VERSION "dbc-export 1 2025.20.8"

NS_ :

BS_:

BU_: APP BMS CC CMP CMPD CP DAS DI DIF DIR EPBL EPBR EVSE FC GTW HCML HCMR HVP ICR PCS PM PMF PMR PTC SCCM SDCR TAS UMC VC VCFRONT VCLEFT VCRIGHT VCSEC

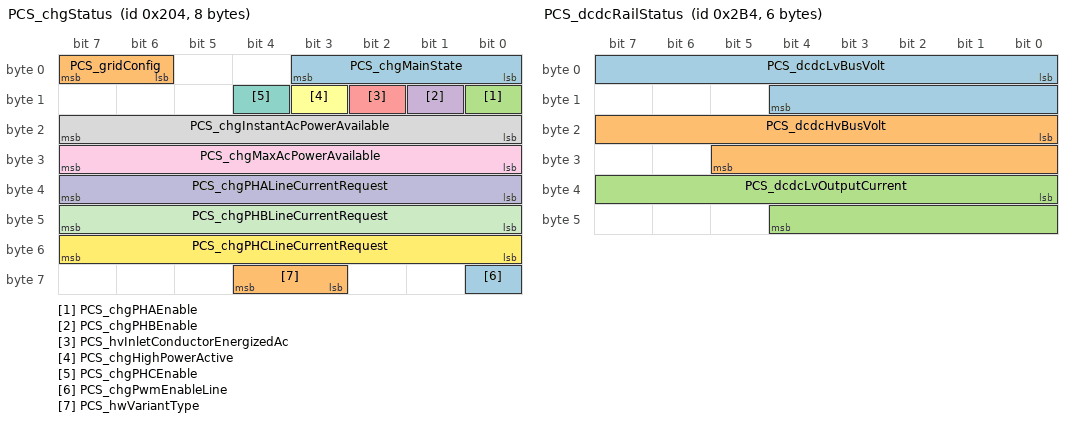
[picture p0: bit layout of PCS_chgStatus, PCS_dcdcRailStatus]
BO_ 516 PCS_chgStatus: 8 PCS
 SG_ PCS_chgMainState : 0|4@1+ (1,0) [0|15] "" Vector__XXX
 SG_ PCS_gridConfig : 6|2@1+ (1,0) [1|3] "" Vector__XXX
 SG_ PCS_chgPHAEnable : 8|1@1+ (1,0) [0|1] "" Vector__XXX
 SG_ PCS_chgPHBEnable : 9|1@1+ (1,0) [0|1] "" Vector__XXX
 SG_ PCS_hvInletConductorEnergizedAc : 10|1@1+ (1,0) [0|1] "" Vector__XXX
 SG_ PCS_chgHighPowerActive : 11|1@1+ (1,0) [0|1] "" Vector__XXX
 SG_ PCS_chgPHCEnable : 12|1@1+ (1,0) [0|1] "" Vector__XXX
 SG_ PCS_chgInstantAcPowerAvailable : 16|8@1+ (0.1,0) [0|20] "kW" Vector__XXX
 SG_ PCS_chgMaxAcPowerAvailable : 24|8@1+ (0.1,0) [0|20] "kW" Vector__XXX
 SG_ PCS_chgPHALineCurrentRequest : 32|8@1+ (0.1,0) [0|20] "A" Vector__XXX
 SG_ PCS_chgPHBLineCurrentRequest : 40|8@1+ (0.1,0) [0|20] "A" Vector__XXX
 SG_ PCS_chgPHCLineCurrentRequest : 48|8@1+ (0.1,0) [0|20] "A" Vector__XXX
 SG_ PCS_chgPwmEnableLine : 56|1@1+ (1,0) [0|1] "" Vector__XXX
 SG_ PCS_hwVariantType : 59|2@1+ (1,0) [0|2] "" Vector__XXX

BO_ 692 PCS_dcdcRailStatus: 6 PCS
 SG_ PCS_dcdcLvBusVolt : 0|13@1+ (0.01,0) [0|80] "V" Vector__XXX
 SG_ PCS_dcdcHvBusVolt : 16|14@1+ (0.1,0) [0|1600] "V" Vector__XXX
 SG_ PCS_dcdcLvOutputCurrent : 32|13@1- (0.1,0) [-400|400] "A" Vector__XXX

BO_ 548 PCS_dcdcStatus: 8 PCS
 SG_ PCS_dcdcPrechargeStatus : 0|2@1+ (1,0) [0|3] "" Vector__XXX
 SG_ PCS_dcdcLvSupportStatus : 2|2@1+ (1,0) [0|3] "" Vector__XXX
 SG_ PCS_dcdcHvBusDischargeStatus : 4|2@1+ (1,0) [0|3] "" Vector__XXX
 SG_ PCS_coldSleepAllowed : 8|1@1+ (1,0) [0|1] "" Vector__XXX
 SG_ PCS_dcdcPchgHVBusLowRDetected : 9|1@1+ (1,0) [0|1] "" Vector__XXX
 SG_ PCS_dcdcSubState : 10|5@1+ (1,0) [0|31] "" Vector__XXX
 SG_ PCS_dcdcFaulted : 15|1@1+ (1,0) [0|1] "" Vector__XXX
 SG_ PCS_okToBePowerCycled : 27|1@1+ (1,0) [0|1] "" Vector__XXX
 SG_ PCS_dcdcOutputIsLimited : 28|1@1+ (1,0) [0|1] "" Vector__XXX
 SG_ PCS_dcdcMaxOutputCurrentAllowed : 29|12@1+ (0.1,0) [0|400] "A" Vector__XXX
 SG_ PCS_dcdcPrechargeRtyCnt : 41|3@1+ (1,0) [0|7] "" Vector__XXX
 SG_ PCS_dcdcLvSupportRtyCnt : 44|4@1+ (1,0) [0|15] "" Vector__XXX
 SG_ PCS_dcdcDischargeRtyCnt : 48|4@1+ (1,0) [0|15] "" Vector__XXX
 SG_ PCS_dcdcPwmEnableLine : 52|1@1+ (1,0) [0|1] "" Vector__XXX
 SG_ PCS_dcdcSupportingFixedLvTarget : 53|1@1+ (1,0) [0|1] "" Vector__XXX
 SG_ PCS_ecuLogUploadRequest : 54|2@1+ (1,0) [0|3] "" Vector__XXX
 SG_ PCS_dcdcPrechargeRestartCnt : 56|3@1+ (1,0) [0|7] "" Vector__XXX
 SG_ PCS_dcdcInitialPrechargeSubState : 59|5@1+ (1,0) [0|31] "" Vector__XXX

BO_ 964 PCS_info: 8 PCS
 SG_ PCS_infoIndex M : 0|8@1+ (1,0) [0|255] "" Vector__XXX
 SG_ PCS_buildType m10 : 8|8@1+ (1,0) [0|255] "" Vector__XXX
 SG_ PCS_buildConfigId m10 : 16|16@1+ (1,0) [0|65535] "" Vector__XXX
 SG_ PCS_hardwareId m10 : 32|16@1+ (1,0) [0|65535] "" Vector__XXX
 SG_ PCS_componentId m10 : 48|16@1+ (1,0) [0|65535] "" Vector__XXX
 SG_ PCS_pcbaId m11 : 16|8@1+ (1,0) [0|255] "" Vector__XXX
 SG_ PCS_assemblyId m11 : 24|8@1+ (1,0) [0|255] "" Vector__XXX
 SG_ PCS_usageId m11 : 32|16@1+ (1,0) [0|65535] "" Vector__XXX
 SG_ PCS_subUsageId m11 : 48|16@1+ (1,0) [0|65535] "" Vector__XXX
 SG_ PCS_platformType m13 : 8|8@1+ (1,0) [0|255] "" Vector__XXX
 SG_ PCS_appCrc m13 : 32|32@1+ (1,0) [0|4294967295] "" Vector__XXX
 SG_ PCS_cpu2AppCrc m16 : 32|32@1+ (1,0) [0|4294967295] "" Vector__XXX
 SG_ PCS_appGitHash m17 : 8|56@1+ (1,0) [0|7.20575940379e+16] "" Vector__XXX
 SG_ PCS_bootGitHash m18 : 8|56@1+ (1,0) [0|7.20575940379e+16] "" Vector__XXX
 SG_ PCS_bootUdsProtoVersion m20 : 8|8@1+ (1,0) [0|255] "" Vector__XXX
 SG_ PCS_bootCrc m20 : 32|32@1+ (1,0) [0|4294967295] "" Vector__XXX

BO_ 708 PCS_logging: 8 PCS
 SG_ PCS_logMessageSelect M : 0|5@1+ (1,0) [0|31] "" Vector__XXX
 SG_ PCS_chgPhAInputIrms m0 : 5|9@1+ (0.1,0) [0|51.1] "A" Vector__XXX
 SG_ PCS_chgPhAIntBusV m0 : 14|9@1+ (1,0) [0|511] "V" Vector__XXX
 SG_ PCS_chgPhAIntBusVTarget m0 : 23|9@1+ (1,0) [0|511] "V" Vector__XXX
 SG_ PCS_chgPhAOutputI m0 : 32|8@1+ (0.1,0) [0|25.5] "A" Vector__XXX
 SG_ PCS_chgPhAInputCurrentLimitReaso m0 : 40|3@1+ (1,0) [0|7] "" Vector__XXX
 SG_ PCS_chgPhBInputIrms m1 : 5|9@1+ (0.1,0) [0|51.1] "A" Vector__XXX
 SG_ PCS_chgPhBIntBusV m1 : 14|9@1+ (1,0) [0|511] "V" Vector__XXX
 SG_ PCS_chgPhBIntBusVTarget m1 : 23|9@1+ (1,0) [0|511] "V" Vector__XXX
 SG_ PCS_chgPhBOutputI m1 : 32|8@1+ (0.1,0) [0|25.5] "A" Vector__XXX
 SG_ PCS_chgPhBInputCurrentLimitReaso m1 : 40|3@1+ (1,0) [0|7] "" Vector__XXX
 SG_ PCS_chgPhCInputIrms m2 : 5|9@1+ (0.1,0) [0|51.1] "A" Vector__XXX
 SG_ PCS_chgPhCIntBusV m2 : 14|9@1+ (1,0) [0|511] "V" Vector__XXX
 SG_ PCS_chgPhCIntBusVTarget m2 : 23|9@1+ (1,0) [0|511] "V" Vector__XXX
 SG_ PCS_chgPhCOutputI m2 : 32|8@1+ (0.1,0) [0|25.5] "A" Vector__XXX
 SG_ PCS_chgPhCInputCurrentLimitReaso m2 : 40|3@1+ (1,0) [0|7] "" Vector__XXX
 SG_ PCS_chgInputL1NVrms m3 : 5|12@1+ (0.2,0) [0|819] "V" Vector__XXX
 SG_ PCS_chgInputL2NVrms m3 : 17|12@1+ (0.2,0) [0|819] "V" Vector__XXX
 SG_ PCS_chgInputL3NVrms m3 : 29|12@1+ (0.2,0) [0|819] "V" Vector__XXX
 SG_ PCS_chgInputL1L2Vrms m3 : 41|12@1+ (0.2,0) [0|819] "V" Vector__XXX
 SG_ PCS_chgInputNGVrms m3 : 53|9@1+ (1,0) [0|511] "V" Vector__XXX
 SG_ PCS_chgInputFrequencyL1N m4 : 5|12@1+ (0.01,40) [40|80.95] "Hz" Vector__XXX
 SG_ PCS_chgInputFrequencyL2N m4 : 17|12@1+ (0.01,40) [40|80.95] "Hz" Vector__XXX
 SG_ PCS_chgInputFrequencyL3N m4 : 29|12@1+ (0.01,40) [40|80.95] "Hz" Vector__XXX
 SG_ PCS_chgInternalPhaseConfig m4 : 41|4@1+ (1,0) [1|15] "" Vector__XXX
 SG_ PCS_chgPhasesPriority m4 : 45|6@1+ (1,0) [0|63] "" Vector__XXX
 SG_ PCS_chgOutputV m4 : 51|12@1+ (0.146484375,0) [0|599.853515625] "V" Vector__XXX
 SG_ PCS_chgPhAState m5 : 5|4@1+ (1,0) [0|15] "" Vector__XXX
 SG_ PCS_chgPhBState m5 : 9|4@1+ (1,0) [0|15] "" Vector__XXX
 SG_ PCS_chgPhCState m5 : 13|4@1+ (1,0) [0|15] "" Vector__XXX
 SG_ PCS_chgPhALastShutdownReason m5 : 17|5@1+ (1,0) [0|31] "" Vector__XXX
 SG_ PCS_chgPhBLastShutdownReason m5 : 22|5@1+ (1,0) [0|31] "" Vector__XXX
 SG_ PCS_chgPhCLastShutdownReason m5 : 27|5@1+ (1,0) [0|31] "" Vector__XXX
 SG_ PCS_chgPhARetryCount m5 : 32|3@1+ (1,0) [0|7] "" Vector__XXX
 SG_ PCS_chgPhBRetryCount m5 : 35|3@1+ (1,0) [0|7] "" Vector__XXX
 SG_ PCS_chgPhCRetryCount m5 : 38|3@1+ (1,0) [0|7] "" Vector__XXX
 SG_ PCS_chgRetryCount m5 : 41|3@1+ (1,0) [0|7] "" Vector__XXX
 SG_ PCS_chgPhManCurrentToDist m5 : 44|10@1+ (0.1,0) [0|100] "A" Vector__XXX
 SG_ PCS_chgL1NPllLocked m5 : 54|1@1+ (1,0) [0|1] "" Vector__XXX
 SG_ PCS_chgL2NPllLocked m5 : 55|1@1+ (1,0) [0|1] "" Vector__XXX
 SG_ PCS_chgL3NPllLocked m5 : 56|1@1+ (1,0) [0|1] "" Vector__XXX
 SG_ PCS_chgL1L2PllLocked m5 : 57|1@1+ (1,0) [0|1] "" Vector__XXX
 SG_ PCS_chgNgPllLocked m5 : 58|1@1+ (1,0) [0|1] "" Vector__XXX
 SG_ PCS_chgPhManOptimalPhsToUse m5 : 59|2@1+ (1,0) [0|3] "" Vector__XXX
 SG_ PCS_chg5VL1Enable m5 : 61|1@1+ (1,0) [0|1] "" Vector__XXX
 SG_ PCS_dcdcMaxLvOutputCurrent m6 : 8|12@1+ (0.1,0) [0|400] "A" Vector__XXX
 SG_ PCS_dcdcCurrentLimit m6 : 20|12@1+ (0.1,0) [0|400] "A" Vector__XXX
 SG_ PCS_dcdcLvOutputCurrentTempLimit m6 : 32|12@1+ (0.1,0) [0|400] "A" Vector__XXX
 SG_ PCS_dcdcLvOutputCurrentFiltered m6 : 44|12@1+ (0.1,0) [0|400] "A" Vector__XXX
 SG_ PCS_dcdcUnifiedCommand m7 : 5|10@1+ (0.001,0) [0|1] "1" Vector__XXX
 SG_ PCS_dcdcCLAControllerOutput m7 : 16|10@1+ (0.001,0) [0|1] "1" Vector__XXX
 SG_ PCS_dcdcTankVoltage m7 : 26|11@1- (1,0) [-1024|1023] "V" Vector__XXX
 SG_ PCS_dcdcTankVoltageTarget m7 : 37|10@1+ (1,0) [0|1023] "V" Vector__XXX
 SG_ PCS_dcdcClaCurrentFreq m7 : 48|12@1+ (0.09765625,0) [0|399.9] "kHz" Vector__XXX
 SG_ PCS_dcdcTCommMeasured m8 : 5|16@1- (0.001953125,0) [-64|63.998] "us" Vector__XXX
 SG_ PCS_dcdcShortTimeUs m8 : 21|16@1+ (0.00048828125,0) [0|31.9995] "us" Vector__XXX
 SG_ PCS_dcdcHalfPeriodUs m8 : 37|16@1+ (0.00048828125,0) [0|31.9995] "us" Vector__XXX
 SG_ PCS_dcdcLvBusVoltTargetWithOffse m8 : 53|11@1+ (0.01,0) [0|20] "V" Vector__XXX
 SG_ PCS_cpu2BootState m9 : 5|2@1+ (1,0) [0|3] "" Vector__XXX
 SG_ PCS_acChargeSelfTestState m9 : 7|1@1+ (1,0) [0|1] "" Vector__XXX
 SG_ PCS_1V5Min10s m9 : 8|11@1+ (0.001,0) [0|2.047] "V" Vector__XXX
 SG_ PCS_1V5Max10s m9 : 19|11@1+ (0.001,0) [0|2.047] "V" Vector__XXX
 SG_ PCS_1V2Min10s m9 : 32|11@1+ (0.001,0) [0|2.047] "V" Vector__XXX
 SG_ PCS_1V2Max10s m9 : 43|11@1+ (0.001,0) [0|2.047] "V" Vector__XXX
 SG_ PCS_5VNMax10s m9 : 54|10@1+ (0.01,0) [0|10.23] "V" Vector__XXX
 SG_ PCS_chgPhAIntBusVMin10s m10 : 5|9@1+ (1,0) [0|511] "V" Vector__XXX
 SG_ PCS_chgPhAIntBusVMax10s m10 : 14|9@1+ (1,0) [0|511] "V" Vector__XXX
 SG_ PCS_chgPhAPchgVoltDeltaMax10s m10 : 23|8@1+ (0.5,0) [0|127.5] "V" Vector__XXX
 SG_ PCS_chgPhALifetimekWh m10 : 31|24@1+ (0.01,0) [0|167772.15] "kWh" Vector__XXX
 SG_ PCS_chgPhATransientRetryCount m10 : 55|9@1+ (0.1,0) [0|51.1] "-" Vector__XXX
 SG_ PCS_chgPhBIntBusVMin10s m11 : 5|9@1+ (1,0) [0|511] "V" Vector__XXX
 SG_ PCS_chgPhBIntBusVMax10s m11 : 14|9@1+ (1,0) [0|511] "V" Vector__XXX
 SG_ PCS_chgPhBPchgVoltDeltaMax10s m11 : 23|8@1+ (0.5,0) [0|127.5] "V" Vector__XXX
 SG_ PCS_chgPhBLifetimekWh m11 : 31|24@1+ (0.01,0) [0|167772.15] "kWh" Vector__XXX
 SG_ PCS_chgPhBTransientRetryCount m11 : 55|9@1+ (0.1,0) [0|51.1] "-" Vector__XXX
 SG_ PCS_chgPhCIntBusVMin10s m12 : 5|9@1+ (1,0) [0|511] "V" Vector__XXX
 SG_ PCS_chgPhCIntBusVMax10s m12 : 14|9@1+ (1,0) [0|511] "V" Vector__XXX
 SG_ PCS_chgPhCPchgVoltDeltaMax10s m12 : 23|8@1+ (0.5,0) [0|127.5] "V" Vector__XXX
 SG_ PCS_chgPhCLifetimekWh m12 : 31|24@1+ (0.01,0) [0|167772.15] "kWh" Vector__XXX
 SG_ PCS_chgPhCTransientRetryCount m12 : 55|9@1+ (0.1,0) [0|51.1] "-" Vector__XXX
 SG_ PCS_chgPhANoFlowBucket m20 : 5|9@1+ (0.01,0) [0|5.11] "-" Vector__XXX
 SG_ PCS_chgPhBNoFlowBucket m20 : 14|9@1+ (0.01,0) [0|5.11] "-" Vector__XXX
 SG_ PCS_chgPhCNoFlowBucket m20 : 23|9@1+ (0.01,0) [0|5.11] "-" Vector__XXX
 SG_ PCS_chgCurrentSensorOutOfBandUs m20 : 32|10@1+ (0.01,0) [0|10.23] "us" Vector__XXX
 SG_ PCS_chgAcpwHeartbeatState m20 : 42|3@1+ (1,0) [0|7] "" Vector__XXX
 SG_ PCS_chgKwhLostByFreqDroop m20 : 48|8@1+ (0.1,0) [0|25.5] "kWh" Vector__XXX
 SG_ PCS_chgReqKwhLostByFreqDroop m20 : 56|8@1+ (0.1,0) [0|25.5] "kWh" Vector__XXX
 SG_ PCS_dcdcLvSupportLifetimekWh m22 : 8|24@1+ (0.01,0) [0|167772.15] "kWh" Vector__XXX
 SG_ PCS_chgPwmEnableLineErrorCount m22 : 32|10@1+ (1,0) [0|1023] "" Vector__XXX
 SG_ PCS_dcdcPwmEnableLineErrorCount m22 : 42|10@1+ (1,0) [0|1023] "" Vector__XXX
 SG_ PCS_numAlertsSet m22 : 56|7@1+ (1,0) [0|127] "" Vector__XXX
 SG_ PCS_dcdcPchgStartLvBusVolt m24 : 5|10@1+ (0.0390625,0) [0|39.9609375] "V" Vector__XXX
 SG_ PCS_dcdcPchgStartHvBusVolt m24 : 16|12@1+ (0.146484375,0) [0|599.853515625] "V" Vector__XXX
 SG_ PCS_processorDieIdLot m26 : 8|24@1+ (1,0) [0|16777215] "" Vector__XXX
 SG_ PCS_processorDieIdWafer m26 : 32|8@1+ (1,0) [0|255] "" Vector__XXX
 SG_ PCS_processorDieIdX m26 : 40|12@1+ (1,0) [0|4095] "" Vector__XXX
 SG_ PCS_processorDieIdY m26 : 52|12@1+ (1,0) [0|4095] "" Vector__XXX

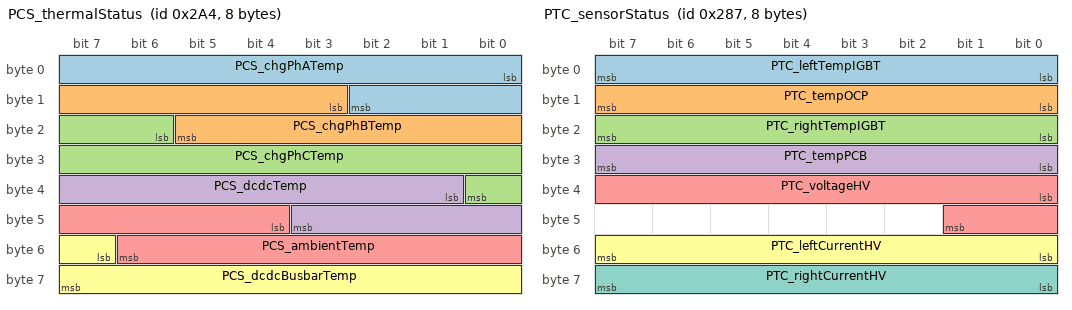
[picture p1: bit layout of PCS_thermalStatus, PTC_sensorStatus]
BO_ 676 PCS_thermalStatus: 8 PCS
 SG_ PCS_chgPhATemp : 0|11@1- (0.1,40) [-62.4|142.3] "C" Vector__XXX
 SG_ PCS_chgPhBTemp : 11|11@1- (0.1,40) [-62.4|142.3] "C" Vector__XXX
 SG_ PCS_chgPhCTemp : 22|11@1- (0.1,40) [-62.4|142.3] "C" Vector__XXX
 SG_ PCS_dcdcTemp : 33|11@1- (0.1,40) [-62.4|142.3] "C" Vector__XXX
 SG_ PCS_ambientTemp : 44|11@1- (0.1,40) [-62.4|142.3] "C" Vector__XXX
 SG_ PCS_dcdcBusbarTemp : 55|9@1+ (0.2935421,0) [0|149.706471] "C" Vector__XXX

BO_ 790 PMF_info: 8 PMF
 SG_ PMF_infoIndex M : 0|8@1+ (1,0) [0|255] "" Vector__XXX
 SG_ PMF_buildType m10 : 8|8@1+ (1,0) [0|255] "" Vector__XXX
 SG_ PMF_buildConfigurationId m10 : 16|16@1+ (1,0) [0|65535] "" Vector__XXX
 SG_ PMF_hardwareId m10 : 32|8@1+ (1,0) [0|252] "" Vector__XXX
 SG_ PMF_deviceFused m10 : 40|1@1+ (1,0) [0|1] "" Vector__XXX
 SG_ PMF_componentId m10 : 48|16@1+ (1,0) [0|65535] "" Vector__XXX
 SG_ PMF_pcbaId m11 : 16|8@1+ (1,0) [0|255] "" Vector__XXX
 SG_ PMF_assemblyId m11 : 24|8@1+ (1,0) [0|255] "" Vector__XXX
 SG_ PMF_usageId m11 : 32|16@1+ (1,0) [0|65535] "" Vector__XXX
 SG_ PMF_subUsageId m11 : 48|16@1+ (1,0) [0|65535] "" Vector__XXX
 SG_ PMF_applicationCrc m13 : 32|32@1+ (1,0) [0|4294967295] "" Vector__XXX
 SG_ PMF_appGitHash m17 : 8|56@1+ (1,0) [0|7.20575940379e+16] "" Vector__XXX
 SG_ PMF_bootGitHash m18 : 8|56@1+ (1,0) [0|7.20575940379e+16] "" Vector__XXX
 SG_ PMF_platformTyp m19 : 8|8@1+ (1,0) [0|255] "" Vector__XXX
 SG_ PMF_udsProtocolVersion m20 : 8|8@1+ (1,0) [0|255] "" Vector__XXX
 SG_ PMF_bootloaderCrc m20 : 32|32@1+ (1,0) [0|4294967295] "" Vector__XXX

BO_ 1748 PMR_info: 8 PMR
 SG_ PMR_infoIndex M : 0|8@1+ (1,0) [0|255] "" Vector__XXX
 SG_ PMR_buildType m10 : 8|8@1+ (1,0) [0|255] "" Vector__XXX
 SG_ PMR_buildConfigurationId m10 : 16|16@1+ (1,0) [0|65535] "" Vector__XXX
 SG_ PMR_hardwareId m10 : 32|8@1+ (1,0) [0|252] "" Vector__XXX
 SG_ PMR_deviceFused m10 : 40|1@1+ (1,0) [0|1] "" Vector__XXX
 SG_ PMR_componentId m10 : 48|16@1+ (1,0) [0|65535] "" Vector__XXX
 SG_ PMR_pcbaId m11 : 16|8@1+ (1,0) [0|255] "" Vector__XXX
 SG_ PMR_assemblyId m11 : 24|8@1+ (1,0) [0|255] "" Vector__XXX
 SG_ PMR_usageId m11 : 32|16@1+ (1,0) [0|65535] "" Vector__XXX
 SG_ PMR_subUsageId m11 : 48|16@1+ (1,0) [0|65535] "" Vector__XXX
 SG_ PMR_applicationCrc m13 : 32|32@1+ (1,0) [0|4294967295] "" Vector__XXX
 SG_ PMR_appGitHash m17 : 8|56@1+ (1,0) [0|7.20575940379e+16] "" Vector__XXX
 SG_ PMR_bootGitHash m18 : 8|56@1+ (1,0) [0|7.20575940379e+16] "" Vector__XXX
 SG_ PMR_platformTyp m19 : 8|8@1+ (1,0) [0|255] "" Vector__XXX
 SG_ PMR_udsProtocolVersion m20 : 8|8@1+ (1,0) [0|255] "" Vector__XXX
 SG_ PMR_bootloaderCrc m20 : 32|32@1+ (1,0) [0|4294967295] "" Vector__XXX

BO_ 1551 PM_info: 8 PM
 SG_ PM_infoIndex M : 0|8@1+ (1,0) [0|255] "" Vector__XXX
 SG_ PM_buildType m10 : 8|8@1+ (1,0) [0|255] "" Vector__XXX
 SG_ PM_buildConfigurationId m10 : 16|16@1+ (1,0) [0|65535] "" Vector__XXX
 SG_ PM_hardwareId m10 : 32|8@1+ (1,0) [0|252] "" Vector__XXX
 SG_ PM_deviceFused m10 : 40|1@1+ (1,0) [0|1] "" Vector__XXX
 SG_ PM_componentId m10 : 48|16@1+ (1,0) [0|65535] "" Vector__XXX
 SG_ PM_pcbaId m11 : 16|8@1+ (1,0) [0|255] "" Vector__XXX
 SG_ PM_assemblyId m11 : 24|8@1+ (1,0) [0|255] "" Vector__XXX
 SG_ PM_usageId m11 : 32|16@1+ (1,0) [0|65535] "" Vector__XXX
 SG_ PM_subUsageId m11 : 48|16@1+ (1,0) [0|65535] "" Vector__XXX
 SG_ PM_applicationCrc m13 : 32|32@1+ (1,0) [0|4294967295] "" Vector__XXX
 SG_ PM_bootGitHash m18 : 8|56@1+ (1,0) [0|7.20575940379e+16] "" Vector__XXX

BO_ 837 PTC_info: 8 PTC
 SG_ PTC_infoIndex M : 0|8@1+ (1,0) [0|255] "" Vector__XXX
 SG_ PTC_infoBuildType m10 : 8|3@1+ (1,0) [0|7] "" Vector__XXX
 SG_ PTC_infoBuildConfigId m10 : 16|16@1+ (1,0) [0|65535] "" Vector__XXX
 SG_ PTC_infoHardwareId m10 : 32|16@1+ (1,0) [0|65535] "" Vector__XXX
 SG_ PTC_infoComponentId m10 : 48|16@1+ (1,0) [0|65535] "" Vector__XXX
 SG_ PTC_infoPcbaId m11 : 16|8@1+ (1,0) [0|255] "" Vector__XXX
 SG_ PTC_infoAssemblyId m11 : 24|8@1+ (1,0) [0|254] "" Vector__XXX
 SG_ PTC_infoUsageId m11 : 32|16@1+ (1,0) [0|65535] "" Vector__XXX
 SG_ PTC_infoSubUsageId m11 : 48|16@1+ (1,0) [0|65535] "" Vector__XXX
 SG_ PTC_infoPlatformType m13 : 8|8@1+ (1,0) [0|255] "" Vector__XXX
 SG_ PTC_infoAppCrc m13 : 32|32@1+ (1,0) [0|4294967295] "" Vector__XXX
 SG_ PTC_infoBootUdsProtoVersion m20 : 8|8@1+ (1,0) [0|255] "" Vector__XXX
 SG_ PTC_infoBootCrc m20 : 32|32@1+ (1,0) [0|4294967295] "" Vector__XXX

BO_ 647 PTC_sensorStatus: 8 PTC
 SG_ PTC_leftTempIGBT : 0|8@1+ (1,-40) [-40|200] "degC" Vector__XXX
 SG_ PTC_tempOCP : 8|8@1+ (1,-40) [-40|200] "degC" Vector__XXX
 SG_ PTC_rightTempIGBT : 16|8@1+ (1,-40) [-40|200] "degC" Vector__XXX
 SG_ PTC_tempPCB : 24|8@1+ (1,-40) [-40|200] "degC" Vector__XXX
 SG_ PTC_voltageHV : 32|10@1+ (0.5,0) [0|511.5] "V" Vector__XXX
 SG_ PTC_leftCurrentHV : 48|8@1+ (0.2,0) [0|50] "A" Vector__XXX
 SG_ PTC_rightCurrentHV : 56|8@1+ (0.2,0) [0|50] "A" Vector__XXX

BO_ 816 SCCM_info: 8 SCCM
 SG_ SCCM_infoIndex M : 0|8@1+ (1,0) [0|255] "" Vector__XXX
 SG_ SCCM_infoBuildType m10 : 8|8@1+ (1,0) [0|255] "" Vector__XXX
 SG_ SCCM_infoBuildConfigId m10 : 16|16@1+ (1,0) [0|65535] "" Vector__XXX
 SG_ SCCM_infoHardwareId m10 : 32|16@1+ (1,0) [0|65535] "" Vector__XXX
 SG_ SCCM_infoComponentId m10 : 48|16@1+ (1,0) [0|65535] "" Vector__XXX
 SG_ SCCM_infoPcbaId m11 : 16|8@1+ (1,0) [0|255] "" Vector__XXX
 SG_ SCCM_infoAssemblyId m11 : 24|8@1+ (1,0) [0|255] "" Vector__XXX
 SG_ SCCM_infoUsageId m11 : 32|16@1+ (1,0) [0|65535] "" Vector__XXX
 SG_ SCCM_infoSubUsageId m11 : 48|16@1+ (1,0) [0|65535] "" Vector__XXX
 SG_ SCCM_infoPlatformType m13 : 8|8@1+ (1,0) [0|255] "" Vector__XXX
 SG_ SCCM_infoAppCrc m13 : 39|32@0+ (1,0) [0|4294967295] "" Vector__XXX
 SG_ SCCM_infoBootSvnRev m14 : 8|24@1+ (1,0) [0|16777215] "" Vector__XXX
 SG_ SCCM_infoBootSvnUrlHash m14 : 32|32@1+ (1,0) [0|4294967295] "" Vector__XXX
 SG_ SCCM_infoSubcomponent1Version m16 : 16|32@1+ (1,0) [0|4294967295] "" Vector__XXX
 SG_ SCCM_infoAppSvnHash m17 : 8|56@1+ (1,0) [0|7.20575940379e+16] "" Vector__XXX
 SG_ SCCM_infoBootSvnHash m18 : 8|56@1+ (1,0) [0|7.20575940379e+16] "" Vector__XXX
 SG_ SCCM_infoUdsProtoVersion m20 : 8|8@1+ (1,0) [0|255] "" Vector__XXX
 SG_ SCCM_infoBootCrc m20 : 32|32@1+ (1,0) [0|4294967295] "" Vector__XXX

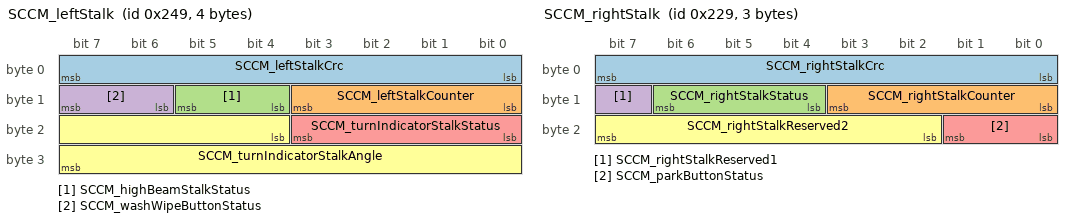
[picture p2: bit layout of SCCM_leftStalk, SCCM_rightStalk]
BO_ 585 SCCM_leftStalk: 4 SCCM
 SG_ SCCM_leftStalkCrc : 0|8@1+ (1,0) [0|255] "" Vector__XXX
 SG_ SCCM_leftStalkCounter : 8|4@1+ (1,0) [0|15] "" Vector__XXX
 SG_ SCCM_highBeamStalkStatus : 12|2@1+ (1,0) [0|2] "" Vector__XXX
 SG_ SCCM_washWipeButtonStatus : 14|2@1+ (1,0) [0|2] "" Vector__XXX
 SG_ SCCM_turnIndicatorStalkStatus : 16|4@1+ (1,0) [0|15] "" Vector__XXX
 SG_ SCCM_turnIndicatorStalkAngle : 20|12@1+ (0.1,-180) [-180|180] "deg" Vector__XXX

BO_ 553 SCCM_rightStalk: 3 SCCM
 SG_ SCCM_rightStalkCrc : 0|8@1+ (1,0) [0|255] "" Vector__XXX
 SG_ SCCM_rightStalkCounter : 8|4@1+ (1,0) [0|15] "" Vector__XXX
 SG_ SCCM_rightStalkStatus : 12|3@1+ (1,0) [0|7] "" Vector__XXX
 SG_ SCCM_rightStalkReserved1 : 15|1@1+ (1,0) [0|1] "" Vector__XXX
 SG_ SCCM_parkButtonStatus : 16|2@1+ (1,0) [0|2] "" Vector__XXX
 SG_ SCCM_rightStalkReserved2 : 18|6@1+ (1,0) [0|63] "" Vector__XXX

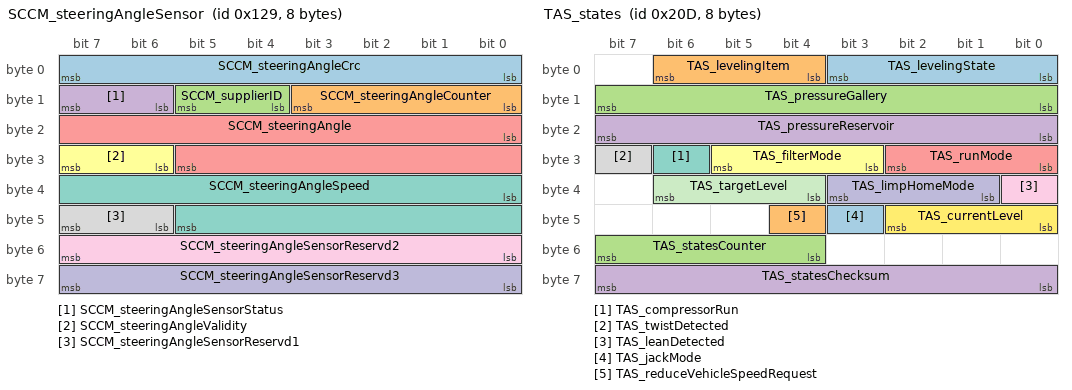
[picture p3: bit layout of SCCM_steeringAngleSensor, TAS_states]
BO_ 297 SCCM_steeringAngleSensor: 8 SCCM
 SG_ SCCM_steeringAngleCrc : 0|8@1+ (1,0) [0|255] "" Vector__XXX
 SG_ SCCM_steeringAngleCounter : 8|4@1+ (1,0) [0|15] "" Vector__XXX
 SG_ SCCM_supplierID : 12|2@1+ (1,0) [0|3] "" Vector__XXX
 SG_ SCCM_steeringAngleSensorStatus : 14|2@1+ (1,0) [0|3] "" Vector__XXX
 SG_ SCCM_steeringAngle : 16|14@1+ (0.1,-819.2) [-819.2|819] "deg" Vector__XXX
 SG_ SCCM_steeringAngleValidity : 30|2@1+ (1,0) [0|2] "" Vector__XXX
 SG_ SCCM_steeringAngleSpeed : 32|14@1+ (0.5,-4096) [-4096|4095.5] "deg/s" Vector__XXX
 SG_ SCCM_steeringAngleSensorReservd1 : 46|2@1+ (1,0) [0|3] "" Vector__XXX
 SG_ SCCM_steeringAngleSensorReservd2 : 48|8@1+ (1,0) [0|255] "" Vector__XXX
 SG_ SCCM_steeringAngleSensorReservd3 : 56|8@1+ (1,0) [0|255] "" Vector__XXX

BO_ 1597 SDCR_info: 8 SDCR
 SG_ SDCR_infoIndex M : 0|8@1+ (1,0) [0|255] "" Vector__XXX
 SG_ SDCR_infoBuildType m10 : 13|3@1+ (1,0) [0|7] "" Vector__XXX
 SG_ SDCR_infoBuildConfigId m10 : 16|16@1+ (1,0) [0|65535] "" Vector__XXX
 SG_ SDCR_infoHardwareId m10 : 32|16@1+ (1,0) [0|65535] "" Vector__XXX
 SG_ SDCR_infoComponentId m10 : 55|16@0+ (1,0) [0|65535] "" Vector__XXX
 SG_ SDCR_infoPcbaId m11 : 8|8@1+ (1,0) [0|255] "" Vector__XXX
 SG_ SDCR_infoAssemblyId m11 : 16|8@1+ (1,0) [0|255] "" Vector__XXX
 SG_ SDCR_infoUsageId m11 : 31|16@0+ (1,0) [0|65535] "" Vector__XXX
 SG_ SDCR_infoSubUsageId m11 : 40|16@1+ (1,0) [0|65535] "" Vector__XXX
 SG_ SDCR_infoAppCrc m13 : 15|32@0+ (1,0) [0|4294967295] "" Vector__XXX
 SG_ SDCR_infoBootGitHash m18 : 8|56@1+ (1,0) [0|7.20575940379e+16] "" Vector__XXX

BO_ 523 TAS_axleData: 8 TAS
 SG_ TAS_axleIndex M : 0|1@1+ (1,0) [0|1] "" Vector__XXX
 SG_ TAS_rawHeightFL m0 : 4|10@1+ (1,-512) [-512|510] "mm" Vector__XXX
 SG_ TAS_staticHeightEstimateFL m0 : 14|10@1+ (1,-512) [-512|510] "mm" Vector__XXX
 SG_ TAS_componentPressureFL m0 : 24|8@1+ (0.1,0) [0|25.4] "bara" Vector__XXX
 SG_ TAS_rawHeightFR m0 : 32|10@1+ (1,-512) [-512|510] "mm" Vector__XXX
 SG_ TAS_staticHeightEstimateFR m0 : 42|10@1+ (1,-512) [-512|510] "mm" Vector__XXX
 SG_ TAS_componentPressureFR m0 : 52|8@1+ (0.1,0) [0|25.4] "bara" Vector__XXX
 SG_ TAS_rawHeightRL m1 : 4|10@1+ (1,-512) [-512|510] "mm" Vector__XXX
 SG_ TAS_staticHeightEstimateRL m1 : 14|10@1+ (1,-512) [-512|510] "mm" Vector__XXX
 SG_ TAS_componentPressureRL m1 : 24|8@1+ (0.1,0) [0|25.4] "bara" Vector__XXX
 SG_ TAS_rawHeightRR m1 : 32|10@1+ (1,-512) [-512|510] "mm" Vector__XXX
 SG_ TAS_staticHeightEstimateRR m1 : 42|10@1+ (1,-512) [-512|510] "mm" Vector__XXX
 SG_ TAS_componentPressureRR m1 : 52|8@1+ (0.1,0) [0|25.4] "bara" Vector__XXX

BO_ 1398 TAS_dampingStates: 8 TAS
 SG_ TAS_endstopState : 0|1@1+ (1,0) [0|1] "" Vector__XXX
 SG_ TAS_continuousControlState : 1|1@1+ (1,0) [0|1] "" Vector__XXX
 SG_ TAS_activeTireTune : 2|1@1+ (1,0) [0|1] "" Vector__XXX
 SG_ TAS_roughnessRaiseReason : 3|2@1+ (1,0) [0|3] "" Vector__XXX
 SG_ TAS_frontMetricDrivesRear : 5|2@1+ (1,0) [0|3] "" Vector__XXX
 SG_ TAS_roadCondition : 8|8@1+ (0.005,0) [0|1.27] "-" Vector__XXX
 SG_ TAS_bellyProtect : 16|2@1+ (1,0) [0|3] "" Vector__XXX
 SG_ TAS_frontMetricDrivesFront : 18|2@1+ (1,0) [0|3] "" Vector__XXX
 SG_ TAS_speedBumpAxleFront : 20|3@1+ (1,0) [0|7] "" Vector__XXX
 SG_ TAS_speedBumpAxleRear : 23|3@1+ (1,0) [0|7] "" Vector__XXX
 SG_ TAS_holeProtectFL : 26|2@1+ (1,0) [0|3] "" Vector__XXX
 SG_ TAS_holeProtectFR : 28|2@1+ (1,0) [0|3] "" Vector__XXX
 SG_ TAS_holeProtectRL : 30|2@1+ (1,0) [0|3] "" Vector__XXX
 SG_ TAS_holeProtectRR : 32|2@1+ (1,0) [0|3] "" Vector__XXX
 SG_ TAS_stepProtectFL : 34|2@1+ (1,0) [0|3] "" Vector__XXX
 SG_ TAS_stepProtectFR : 36|2@1+ (1,0) [0|3] "" Vector__XXX
 SG_ TAS_stepProtectRL : 38|2@1+ (1,0) [0|3] "" Vector__XXX
 SG_ TAS_stepProtectRR : 40|2@1+ (1,0) [0|3] "" Vector__XXX
 SG_ TAS_FDUTorqueCorruptionScale : 42|4@1+ (0.075,0) [0|1.05] "-" Vector__XXX
 SG_ TAS_sprungMassEstimate : 46|5@1+ (64,1800) [1800|3720] "kg" Vector__XXX
 SG_ TAS_anyDamperActive : 51|1@1+ (1,0) [0|1] "" Vector__XXX
 SG_ TAS_dampingStatesCounter : 52|4@1+ (1,0) [0|15] "" Vector__XXX
 SG_ TAS_dampingStatesChecksum : 56|8@1+ (1,0) [0|255] "" Vector__XXX

BO_ 1357 TAS_info: 8 TAS
 SG_ TAS_infoIndex M : 0|8@1+ (1,0) [0|255] "" Vector__XXX
 SG_ TAS_infoBuildType m10 : 8|8@1+ (1,0) [0|255] "" Vector__XXX
 SG_ TAS_infoBuildConfigId m10 : 16|16@1+ (1,0) [0|65535] "" Vector__XXX
 SG_ TAS_infoHardwareId m10 : 32|1@1+ (1,0) [0|1] "" Vector__XXX
 SG_ TAS_infoComponentId m10 : 48|16@1+ (1,0) [0|65535] "" Vector__XXX
 SG_ TAS_infoPcbaId m11 : 16|8@1+ (1,0) [0|255] "" Vector__XXX
 SG_ TAS_infoAssemblyId m11 : 24|8@1+ (1,0) [0|254] "" Vector__XXX
 SG_ TAS_infoUsageId m11 : 32|16@1+ (1,0) [0|65535] "" Vector__XXX
 SG_ TAS_infoSubUsageId m11 : 48|16@1+ (1,0) [0|65535] "" Vector__XXX
 SG_ TAS_infoAppCrc m13 : 32|32@1+ (1,0) [0|4294967295] "" Vector__XXX
 SG_ TAS_infoAppGitHash m17 : 8|56@1+ (1,0) [0|7.20575940379e+16] "" Vector__XXX
 SG_ TAS_infoBootGitHash m18 : 8|56@1+ (1,0) [0|7.20575940379e+16] "" Vector__XXX
 SG_ TAS_infoPlatformType m19 : 8|8@1+ (1,0) [0|255] "" Vector__XXX
 SG_ TAS_infoMajorVersion m19 : 16|8@1+ (1,0) [0|254] "" Vector__XXX
 SG_ TAS_infoBranchOrigin m19 : 24|8@1+ (1,0) [0|254] "" Vector__XXX
 SG_ TAS_infoMaturity m19 : 32|8@1+ (1,0) [0|254] "" Vector__XXX
 SG_ TAS_infoHardwareRevision m19 : 40|8@1+ (1,0) [0|254] "" Vector__XXX

BO_ 525 TAS_states: 8 TAS
 SG_ TAS_levelingState : 0|4@1+ (1,0) [0|15] "" Vector__XXX
 SG_ TAS_levelingItem : 4|3@1+ (1,0) [0|7] "" Vector__XXX
 SG_ TAS_pressureGallery : 8|8@1+ (0.1,0) [0|25.4] "bara" Vector__XXX
 SG_ TAS_pressureReservoir : 16|8@1+ (0.1,0) [0|25.4] "bara" Vector__XXX
 SG_ TAS_runMode : 24|3@1+ (1,0) [0|7] "" Vector__XXX
 SG_ TAS_filterMode : 27|3@1+ (1,0) [0|7] "" Vector__XXX
 SG_ TAS_compressorRun : 30|1@1+ (1,0) [0|1] "" Vector__XXX
 SG_ TAS_twistDetected : 31|1@1+ (1,0) [0|1] "" Vector__XXX
 SG_ TAS_leanDetected : 32|1@1+ (1,0) [0|1] "" Vector__XXX
 SG_ TAS_limpHomeMode : 33|3@1+ (1,0) [0|7] "" Vector__XXX
 SG_ TAS_targetLevel : 36|3@1+ (1,0) [0|7] "" Vector__XXX
 SG_ TAS_currentLevel : 40|3@1+ (1,0) [0|7] "" Vector__XXX
 SG_ TAS_jackMode : 43|1@1+ (1,0) [0|1] "" Vector__XXX
 SG_ TAS_reduceVehicleSpeedRequest : 44|1@1+ (1,0) [0|1] "" Vector__XXX
 SG_ TAS_statesCounter : 52|4@1+ (1,0) [0|15] "" Vector__XXX
 SG_ TAS_statesChecksum : 56|8@1+ (1,0) [0|255] "" Vector__XXX

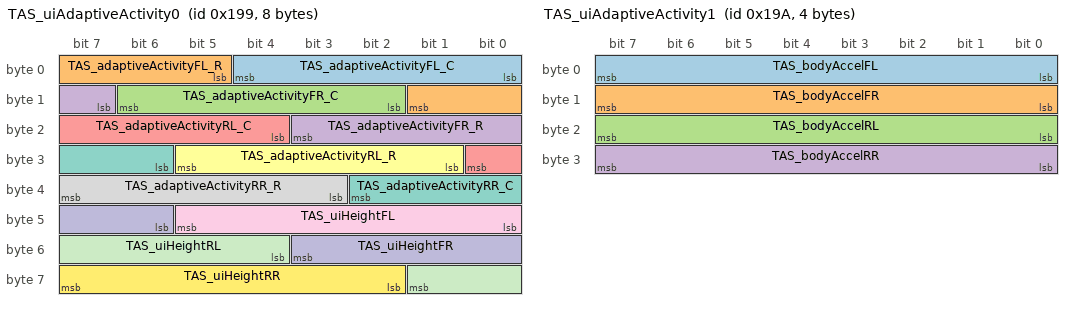
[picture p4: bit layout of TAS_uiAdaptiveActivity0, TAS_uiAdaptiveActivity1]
BO_ 409 TAS_uiAdaptiveActivity0: 8 TAS
 SG_ TAS_adaptiveActivityFL_C : 0|5@1+ (0.04,0) [0|1] "-" Vector__XXX
 SG_ TAS_adaptiveActivityFL_R : 5|5@1+ (0.04,0) [0|1] "-" Vector__XXX
 SG_ TAS_adaptiveActivityFR_C : 10|5@1+ (0.04,0) [0|1] "-" Vector__XXX
 SG_ TAS_adaptiveActivityFR_R : 15|5@1+ (0.04,0) [0|1] "-" Vector__XXX
 SG_ TAS_adaptiveActivityRL_C : 20|5@1+ (0.04,0) [0|1] "-" Vector__XXX
 SG_ TAS_adaptiveActivityRL_R : 25|5@1+ (0.04,0) [0|1] "-" Vector__XXX
 SG_ TAS_adaptiveActivityRR_C : 30|5@1+ (0.04,0) [0|1] "-" Vector__XXX
 SG_ TAS_adaptiveActivityRR_R : 35|5@1+ (0.04,0) [0|1] "-" Vector__XXX
 SG_ TAS_uiHeightFL : 40|6@1+ (4,-128) [-128|120] "mm" Vector__XXX
 SG_ TAS_uiHeightFR : 46|6@1+ (4,-128) [-128|120] "mm" Vector__XXX
 SG_ TAS_uiHeightRL : 52|6@1+ (4,-128) [-128|120] "mm" Vector__XXX
 SG_ TAS_uiHeightRR : 58|6@1+ (4,-128) [-128|120] "mm" Vector__XXX

BO_ 410 TAS_uiAdaptiveActivity1: 4 TAS
 SG_ TAS_bodyAccelFL : 0|8@1+ (0.05,-5) [-5|5] "g" Vector__XXX
 SG_ TAS_bodyAccelFR : 8|8@1+ (0.05,-5) [-5|5] "g" Vector__XXX
 SG_ TAS_bodyAccelRL : 16|8@1+ (0.05,-5) [-5|5] "g" Vector__XXX
 SG_ TAS_bodyAccelRR : 24|8@1+ (0.05,-5) [-5|5] "g" Vector__XXX

BO_ 538 TAS_uiControl: 5 TAS
 SG_ TAS_yellowWarningLamp : 0|1@1+ (1,0) [0|1] "" Vector__XXX
 SG_ TAS_redWarningLamp : 1|1@1+ (1,0) [0|1] "" Vector__XXX
 SG_ TAS_veryLowAllowed : 2|1@1+ (1,0) [0|1] "" Vector__XXX
 SG_ TAS_lowAllowed : 3|1@1+ (1,0) [0|1] "" Vector__XXX
 SG_ TAS_standardAllowed : 4|1@1+ (1,0) [0|1] "" Vector__XXX
 SG_ TAS_highAllowed : 5|1@1+ (1,0) [0|1] "" Vector__XXX
 SG_ TAS_veryHighAllowed : 6|1@1+ (1,0) [0|1] "" Vector__XXX
 SG_ TAS_extractAllowed : 7|1@1+ (1,0) [0|1] "" Vector__XXX
 SG_ TAS_showSpinner : 9|1@1+ (1,0) [0|1] "" Vector__XXX
 SG_ TAS_adaptiveRideModeOverride : 10|2@1+ (1,0) [0|2] "" Vector__XXX
 SG_ TAS_levelSelectEnabled : 12|1@1+ (1,0) [0|1] "" Vector__XXX
 SG_ TAS_jackModeToggleEnabled : 13|1@1+ (1,0) [0|1] "" Vector__XXX
 SG_ TAS_adaptiveRideSelectEnabled : 14|1@1+ (1,0) [0|1] "" Vector__XXX
 SG_ TAS_launchModeState : 16|3@1+ (1,0) [0|7] "" Vector__XXX
 SG_ TAS_restrictUpLevelingFalcons : 19|1@1+ (1,0) [0|1] "" Vector__XXX
 SG_ TAS_restrictUpLevelingTrunk : 20|1@1+ (1,0) [0|1] "" Vector__XXX
 SG_ TAS_restrictDownLevelingDoors : 21|1@1+ (1,0) [0|1] "" Vector__XXX
 SG_ TAS_restrictLevelingChargeCable : 22|1@1+ (1,0) [0|1] "" Vector__XXX
 SG_ TAS_restrictLevelingSystemCheck : 23|1@1+ (1,0) [0|1] "" Vector__XXX
 SG_ TAS_restrictLevelingTransport : 24|1@1+ (1,0) [0|1] "" Vector__XXX
 SG_ TAS_restrictLevelingShowroom : 25|1@1+ (1,0) [0|1] "" Vector__XXX
 SG_ TAS_uiControlCounter : 28|4@1+ (1,0) [0|15] "" Vector__XXX
 SG_ TAS_uiControlChecksum : 32|8@1+ (1,0) [0|255] "" Vector__XXX

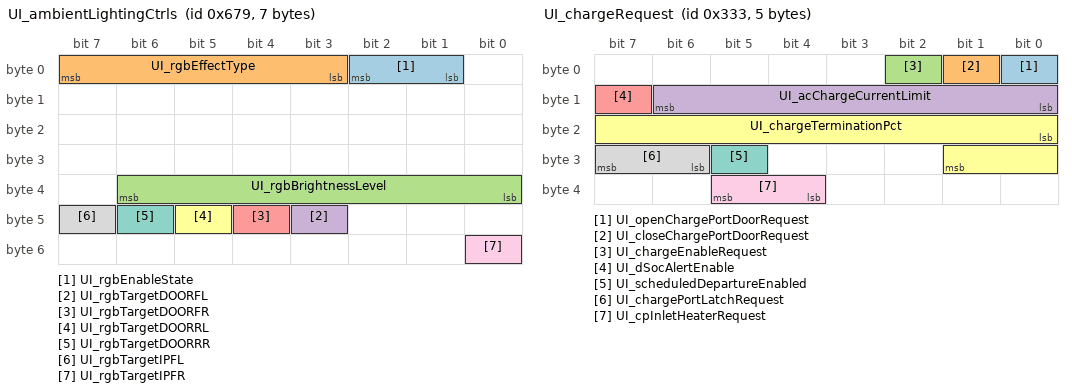
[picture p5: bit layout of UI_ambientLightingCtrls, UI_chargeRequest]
BO_ 1657 UI_ambientLightingCtrls: 7 GTW
 SG_ UI_rgbEnableState : 1|2@1+ (1,0) [0|3] "" Vector__XXX
 SG_ UI_rgbEffectType : 3|5@1+ (1,0) [0|31] "" Vector__XXX
 SG_ UI_rgbBrightnessLevel : 32|7@1+ (1,0) [0|100] "%" Vector__XXX
 SG_ UI_rgbTargetDOORFL : 43|1@1+ (1,0) [0|1] "" Vector__XXX
 SG_ UI_rgbTargetDOORFR : 44|1@1+ (1,0) [0|1] "" Vector__XXX
 SG_ UI_rgbTargetDOORRL : 45|1@1+ (1,0) [0|1] "" Vector__XXX
 SG_ UI_rgbTargetDOORRR : 46|1@1+ (1,0) [0|1] "" Vector__XXX
 SG_ UI_rgbTargetIPFL : 47|1@1+ (1,0) [0|1] "" Vector__XXX
 SG_ UI_rgbTargetIPFR : 48|1@1+ (1,0) [0|1] "" Vector__XXX

BO_ 1021 UI_autopilotControl: 8 GTW
 SG_ UI_autopilotControlIndex M : 0|3@1+ (1,0) [0|7] "" Vector__XXX
 SG_ UI_hovEnabled m0 : 3|1@1+ (1,0) [0|1] "" Vector__XXX
 SG_ UI_smartSetSpeedOffset m0 : 25|6@1+ (1,-30) [-30|33] "%" Vector__XXX
 SG_ UI_smartSetSpeedOffsetType m0 : 31|1@1+ (1,0) [0|1] "" Vector__XXX
 SG_ UI_fsdStopsControlEnabled m0 : 38|1@1+ (1,0) [0|1] "" Vector__XXX
 SG_ UI_smartSetSpeed m0 : 40|1@1+ (1,0) [0|1] "" Vector__XXX
 SG_ UI_automaticSetSpeedOffset m0 : 41|1@1+ (1,0) [0|1] "" Vector__XXX
 SG_ UI_enableFullSelfDriving m0 : 46|1@1+ (1,0) [0|1] "" Vector__XXX
 SG_ UI_hasFullSelfDriving m0 : 47|1@1+ (1,0) [0|1] "" Vector__XXX
 SG_ UI_autosteerActivation m0 : 48|1@1+ (1,0) [0|1] "" Vector__XXX
 SG_ UI_autopilotDrivingProfile m0 : 49|2@1+ (1,0) [0|3] "" Vector__XXX
 SG_ UI_fsdBetaRequest m0 : 51|1@1+ (1,0) [0|1] "" Vector__XXX
 SG_ UI_fullSelfDrivingSuspended m0 : 52|1@1+ (1,0) [0|1] "" Vector__XXX
 SG_ UI_disableOptionalLaneChanges m0 : 53|1@1+ (1,0) [0|1] "" Vector__XXX
 SG_ UI_selectableCameraRequest m1 : 8|4@1+ (1,0) [0|14] "" Vector__XXX
 SG_ UI_driverMonitorConfirmation m1 : 17|1@1+ (1,0) [0|1] "" Vector__XXX
 SG_ UI_parkAssistUseVision m1 : 18|1@1+ (1,0) [0|1] "" Vector__XXX
 SG_ UI_noStalkConfirmAlertHaptic m1 : 32|1@1+ (1,0) [0|1] "" Vector__XXX
 SG_ UI_noStalkConfirmAlertChime m1 : 37|1@1+ (1,0) [0|1] "" Vector__XXX
 SG_ UI_factorySummonEnable m1 : 39|1@1+ (1,0) [0|1] "" Vector__XXX
 SG_ UI_enableCabinCamera m1 : 43|1@1+ (1,0) [0|1] "" Vector__XXX
 SG_ UI_enableAutopilotStopWarning m1 : 44|1@1+ (1,0) [0|1] "" Vector__XXX
 SG_ UI_enableVisionSpeedControl m1 : 49|1@1+ (1,0) [0|1] "" Vector__XXX
 SG_ UI_enableTeslaAutopark m1 : 51|1@1+ (1,0) [0|1] "" Vector__XXX
 SG_ UI_autoTurnSignalMode m1 : 52|1@1+ (1,0) [0|1] "" Vector__XXX
 SG_ UI_enableCabinAudioRecording m1 : 59|1@1+ (1,0) [0|1] "" Vector__XXX

BO_ 819 UI_chargeRequest: 5 GTW
 SG_ UI_openChargePortDoorRequest : 0|1@1+ (1,0) [0|1] "" Vector__XXX
 SG_ UI_closeChargePortDoorRequest : 1|1@1+ (1,0) [0|1] "" Vector__XXX
 SG_ UI_chargeEnableRequest : 2|1@1+ (1,0) [0|1] "" Vector__XXX
 SG_ UI_acChargeCurrentLimit : 8|7@1+ (1,0) [0|126] "A" Vector__XXX
 SG_ UI_dSocAlertEnable : 15|1@1+ (1,0) [0|1] "" Vector__XXX
 SG_ UI_chargeTerminationPct : 16|10@1+ (0.1,0) [5|100] "%" Vector__XXX
 SG_ UI_scheduledDepartureEnabled : 29|1@1+ (1,0) [0|1] "" Vector__XXX
 SG_ UI_chargePortLatchRequest : 30|2@1+ (1,0) [0|3] "" Vector__XXX
 SG_ UI_cpInletHeaterRequest : 36|2@1+ (1,0) [0|3] "" Vector__XXX

BO_ 659 UI_chassisControl: 8 GTW
 SG_ UI_steeringTuneRequest : 0|2@1+ (1,0) [0|3] "" Vector__XXX
 SG_ UI_tractionControlMode : 2|3@1+ (1,0) [0|7] "" Vector__XXX
 SG_ UI_parkBrakeRequest : 5|2@1+ (1,0) [0|2] "" Vector__XXX
 SG_ UI_winchModeRequest : 8|2@1+ (1,0) [0|3] "" Vector__XXX
 SG_ UI_trailerMode : 12|1@1+ (1,0) [0|1] "" Vector__XXX
 SG_ UI_accOvertakeEnable : 16|2@1+ (1,0) [0|2] "" Vector__XXX
 SG_ UI_aebEnable : 18|2@1+ (1,0) [0|2] "" Vector__XXX
 SG_ UI_aesEnable : 20|2@1+ (1,0) [0|2] "" Vector__XXX
 SG_ UI_ahlbEnable : 22|2@1+ (1,0) [0|2] "" Vector__XXX
 SG_ UI_autoLaneChangeEnable : 24|2@1+ (1,0) [0|2] "" Vector__XXX
 SG_ UI_winchProxUserOverride : 26|1@1+ (1,0) [0|1] "" Vector__XXX
 SG_ UI_autoParkRequest : 28|4@1+ (1,0) [0|14] "" Vector__XXX
 SG_ UI_bsdEnable : 32|2@1+ (1,0) [0|2] "" Vector__XXX
 SG_ UI_fcwEnable : 34|2@1+ (1,0) [0|2] "" Vector__XXX
 SG_ UI_fcwSensitivity : 36|2@1+ (1,0) [0|2] "" Vector__XXX
 SG_ UI_latControlEnable : 38|2@1+ (1,0) [0|2] "" Vector__XXX
 SG_ UI_ldwEnable : 40|2@1+ (1,0) [0|2] "" Vector__XXX

BO_ 531 UI_cruiseControl: 2 GTW
 SG_ UI_cruiseSpeedCommand : 0|3@1+ (1,0) [0|7] "" Vector__XXX

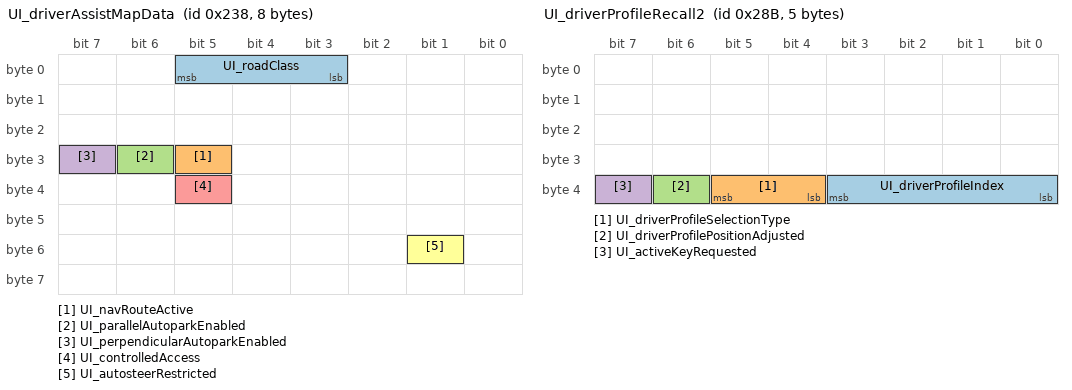
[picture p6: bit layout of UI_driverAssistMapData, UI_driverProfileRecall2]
BO_ 568 UI_driverAssistMapData: 8 GTW
 SG_ UI_roadClass : 3|3@1+ (1,0) [1|7] "" Vector__XXX
 SG_ UI_navRouteActive : 29|1@1+ (1,0) [0|1] "" Vector__XXX
 SG_ UI_parallelAutoparkEnabled : 30|1@1+ (1,0) [0|1] "" Vector__XXX
 SG_ UI_perpendicularAutoparkEnabled : 31|1@1+ (1,0) [0|1] "" Vector__XXX
 SG_ UI_controlledAccess : 37|1@1+ (1,0) [0|1] "" Vector__XXX
 SG_ UI_autosteerRestricted : 49|1@1+ (1,0) [0|1] "" Vector__XXX

BO_ 645 UI_driverProfileRecall: 8 GTW
 SG_ UI_driverProfileRecallIndex M : 0|3@1+ (1,0) [1|7] "" Vector__XXX
 SG_ UI_driverProfileRecallStop : 3|1@1+ (1,0) [0|1] "" Vector__XXX
 SG_ UI_frontSeatRecallActive m1 : 4|1@1+ (1,0) [0|1] "" Vector__XXX
 SG_ UI_leftMirrorTiltXPosition m3 : 8|8@1+ (0.02,0) [0|5] "V" Vector__XXX
 SG_ UI_leftMirrorTiltYPosition m3 : 16|8@1+ (0.02,0) [0|5] "V" Vector__XXX
 SG_ UI_customMirrorDipPositionsSet m4 : 5|1@1+ (1,0) [0|1] "" Vector__XXX
 SG_ UI_leftMirrorDipXPosition m4 : 8|8@1+ (0.02,0) [0|5] "V" Vector__XXX
 SG_ UI_leftMirrorDipYPosition m4 : 16|8@1+ (0.02,0) [0|5] "V" Vector__XXX
 SG_ UI_modifyMirrorDipRequest m4 : 40|2@1+ (1,0) [0|3] "" Vector__XXX

BO_ 651 UI_driverProfileRecall2: 5 GTW
 SG_ UI_driverProfileIndex : 32|4@1+ (1,0) [0|15] "" Vector__XXX
 SG_ UI_driverProfileSelectionType : 36|2@1+ (1,0) [0|3] "" Vector__XXX
 SG_ UI_driverProfilePositionAdjusted : 38|1@1+ (1,0) [0|1] "" Vector__XXX
 SG_ UI_activeKeyRequested : 39|1@1+ (1,0) [0|1] "" Vector__XXX

BO_ 1139 UI_ethNm: 8 GTW
 SG_ UI_nmKeepAwakeReason : 16|5@1+ (1,0) [1|31] "" Vector__XXX
 SG_ UI_wakeupTime : 32|32@1+ (1,0) [0|4294967295] "" Vector__XXX

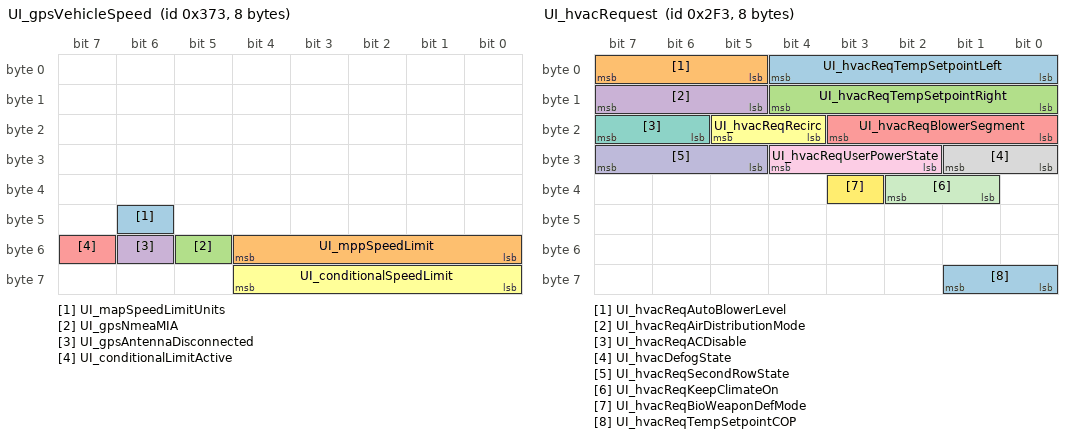
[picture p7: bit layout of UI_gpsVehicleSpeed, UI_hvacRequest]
BO_ 883 UI_gpsVehicleSpeed: 8 GTW
 SG_ UI_mapSpeedLimitUnits : 46|1@1+ (1,0) [0|1] "" Vector__XXX
 SG_ UI_mppSpeedLimit : 48|5@1+ (5,0) [0|155] "kph/mph" Vector__XXX
 SG_ UI_gpsNmeaMIA : 53|1@1+ (1,0) [0|1] "" Vector__XXX
 SG_ UI_gpsAntennaDisconnected : 54|1@1+ (1,0) [0|1] "" Vector__XXX
 SG_ UI_conditionalLimitActive : 55|1@1+ (1,0) [0|1] "" Vector__XXX
 SG_ UI_conditionalSpeedLimit : 56|5@1+ (5,0) [0|150] "kph/mph" Vector__XXX

BO_ 755 UI_hvacRequest: 8 GTW
 SG_ UI_hvacReqTempSetpointLeft : 0|5@1+ (0.5,15) [15|28] "degC" Vector__XXX
 SG_ UI_hvacReqAutoBlowerLevel : 5|3@1+ (1,0) [0|7] "" Vector__XXX
 SG_ UI_hvacReqTempSetpointRight : 8|5@1+ (0.5,15) [15|28] "degC" Vector__XXX
 SG_ UI_hvacReqAirDistributionMode : 13|3@1+ (1,0) [0|7] "" Vector__XXX
 SG_ UI_hvacReqBlowerSegment : 16|4@1+ (1,0) [0|15] "" Vector__XXX
 SG_ UI_hvacReqRecirc : 20|2@1+ (1,0) [0|3] "" Vector__XXX
 SG_ UI_hvacReqACDisable : 22|2@1+ (1,0) [0|3] "" Vector__XXX
 SG_ UI_hvacDefogState : 24|2@1+ (1,0) [0|3] "" Vector__XXX
 SG_ UI_hvacReqUserPowerState : 26|3@1+ (1,0) [0|7] "" Vector__XXX
 SG_ UI_hvacReqSecondRowState : 29|3@1+ (1,0) [0|7] "" Vector__XXX
 SG_ UI_hvacReqKeepClimateOn : 33|2@1+ (1,0) [0|3] "" Vector__XXX
 SG_ UI_hvacReqBioWeaponDefMode : 35|1@1+ (1,0) [0|1] "" Vector__XXX
 SG_ UI_hvacReqTempSetpointCOP : 56|2@1+ (1,0) [0|3] "" Vector__XXX

BO_ 1523 UI_odo: 3 GTW
 SG_ UI_odometer : 0|24@1+ (0.1,0) [0|1677721.4] "km" Vector__XXX

BO_ 948 UI_peripheralPowerRequests: 1 GTW
 SG_ UI_usbFrontHubPowerStateRequest : 0|2@1+ (1,0) [1|3] "" Vector__XXX

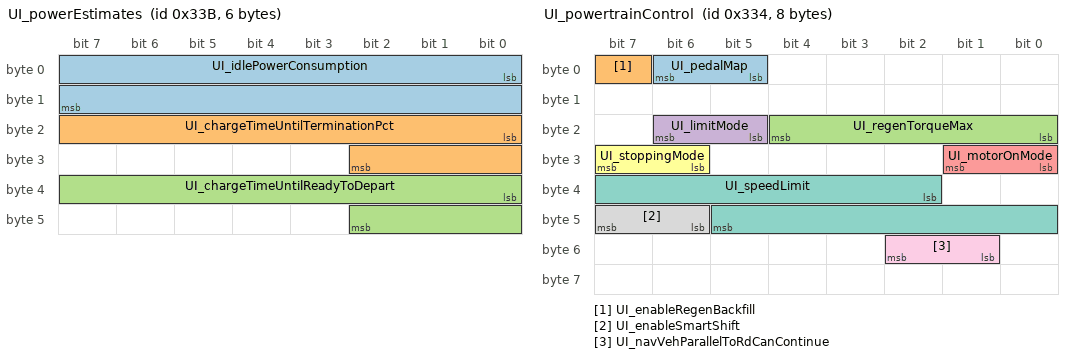
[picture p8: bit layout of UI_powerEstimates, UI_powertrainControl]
BO_ 827 UI_powerEstimates: 6 GTW
 SG_ UI_idlePowerConsumption : 0|16@1+ (0.001,0) [0|50] "kW" Vector__XXX
 SG_ UI_chargeTimeUntilTerminationPct : 16|11@1+ (1,0) [0|2046] "min" Vector__XXX
 SG_ UI_chargeTimeUntilReadyToDepart : 32|11@1+ (1,0) [0|2046] "min" Vector__XXX

BO_ 820 UI_powertrainControl: 8 GTW
 SG_ UI_pedalMap : 5|2@1+ (1,0) [0|3] "" Vector__XXX
 SG_ UI_enableRegenBackfill : 7|1@1+ (1,0) [0|1] "" Vector__XXX
 SG_ UI_regenTorqueMax : 16|5@1+ (5,0) [0|100] "%" Vector__XXX
 SG_ UI_limitMode : 21|2@1+ (1,0) [0|3] "" Vector__XXX
 SG_ UI_motorOnMode : 24|2@1+ (1,0) [0|3] "" Vector__XXX
 SG_ UI_stoppingMode : 30|2@1+ (1,0) [0|3] "" Vector__XXX
 SG_ UI_speedLimit : 34|12@1+ (0.1,0) [0|335] "kph" Vector__XXX
 SG_ UI_enableSmartShift : 46|2@1+ (1,0) [0|3] "" Vector__XXX
 SG_ UI_navVehParallelToRdCanContinue : 49|2@1+ (1,0) [1|3] "" Vector__XXX

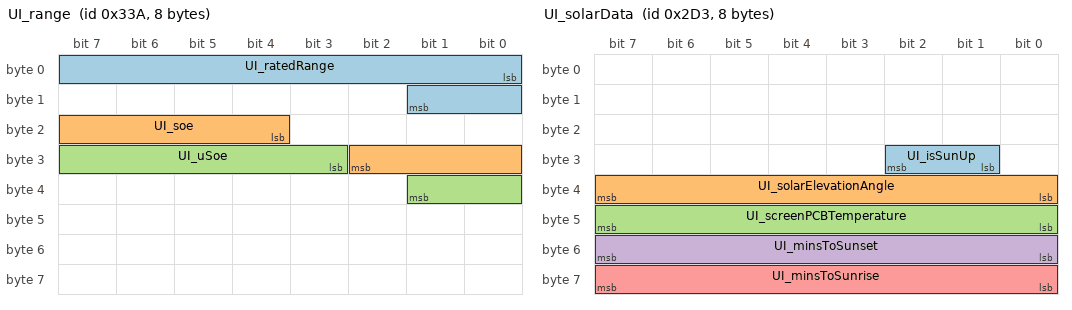
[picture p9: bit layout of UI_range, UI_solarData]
BO_ 826 UI_range: 8 GTW
 SG_ UI_ratedRange : 0|10@1+ (1,0) [0|1023] "mi" Vector__XXX
 SG_ UI_soe : 20|7@1+ (1,0) [0|127] "%" Vector__XXX
 SG_ UI_uSoe : 27|7@1+ (1,0) [0|127] "%" Vector__XXX

BO_ 723 UI_solarData: 8 GTW
 SG_ UI_isSunUp : 25|2@1+ (1,0) [0|2] "" Vector__XXX
 SG_ UI_solarElevationAngle : 32|8@1- (1,0) [-128|126] "degrees" Vector__XXX
 SG_ UI_screenPCBTemperature : 40|8@1- (0.5,40) [-20|100] "degC" Vector__XXX
 SG_ UI_minsToSunset : 48|8@1+ (10,0) [0|2550] "min" Vector__XXX
 SG_ UI_minsToSunrise : 56|8@1+ (10,0) [0|2550] "min" Vector__XXX

BO_ 851 UI_status: 8 GTW
 SG_ UI_touchActive : 0|1@1+ (1,0) [0|1] "" Vector__XXX
 SG_ UI_audioActive : 1|1@1+ (1,0) [0|1] "" Vector__XXX
 SG_ UI_cellActive : 3|1@1+ (1,0) [0|1] "" Vector__XXX
 SG_ UI_displayReady : 4|1@1+ (1,0) [0|1] "" Vector__XXX
 SG_ UI_displayOn : 5|1@1+ (1,0) [0|1] "" Vector__XXX
 SG_ UI_wifiActive : 6|1@1+ (1,0) [0|1] "" Vector__XXX
 SG_ UI_wifiConnected : 7|1@1+ (1,0) [0|1] "" Vector__XXX
 SG_ UI_readyForDrive : 9|1@1+ (1,0) [0|1] "" Vector__XXX
 SG_ UI_cellConnected : 10|1@1+ (1,0) [0|1] "" Vector__XXX
 SG_ UI_vpnActive : 11|1@1+ (1,0) [0|1] "" Vector__XXX
 SG_ UI_factoryReset : 14|2@1+ (1,0) [1|3] "" Vector__XXX
 SG_ UI_gpsActive : 16|1@1+ (1,0) [0|1] "" Vector__XXX
 SG_ UI_cellNetworkTechnology : 19|4@1+ (1,0) [0|14] "" Vector__XXX
 SG_ UI_falseTouchCounter : 32|8@1+ (1,0) [0|255] "1" Vector__XXX
 SG_ UI_cellSignalBars : 42|3@1+ (1,0) [0|6] "" Vector__XXX
 SG_ UI_trailerModeTelltale : 45|2@1+ (1,0) [0|3] "" Vector__XXX
 SG_ UI_pcbTemperature : 48|8@1- (1,40) [-20|100] "degC" Vector__XXX
 SG_ UI_cpuTemperature : 56|8@1- (1,40) [-20|100] "degC" Vector__XXX

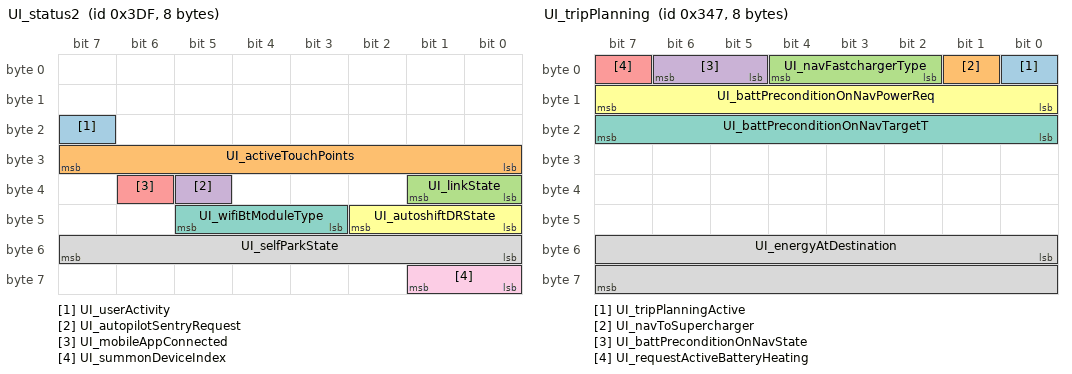
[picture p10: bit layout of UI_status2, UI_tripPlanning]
BO_ 991 UI_status2: 8 GTW
 SG_ UI_userActivity : 23|1@1+ (1,0) [0|1] "" Vector__XXX
 SG_ UI_activeTouchPoints : 24|8@1+ (1,0) [0|255] "1" Vector__XXX
 SG_ UI_linkState : 32|2@1+ (1,0) [0|3] "" Vector__XXX
 SG_ UI_autopilotSentryRequest : 37|1@1+ (1,0) [0|1] "" Vector__XXX
 SG_ UI_mobileAppConnected : 38|1@1+ (1,0) [0|1] "" Vector__XXX
 SG_ UI_autoshiftDRState : 40|3@1+ (1,0) [0|7] "" Vector__XXX
 SG_ UI_wifiBtModuleType : 43|3@1+ (1,0) [0|7] "" Vector__XXX
 SG_ UI_selfParkState : 48|8@1+ (1,0) [0|254] "" Vector__XXX
 SG_ UI_summonDeviceIndex : 56|2@1+ (1,0) [0|3] "" Vector__XXX

BO_ 663 UI_suspensionControl: 8 GTW
 SG_ UI_adaptiveRideRequest : 3|2@1+ (1,0) [0|3] "" Vector__XXX
 SG_ UI_geofenceLevelingRequest : 7|3@1+ (1,0) [0|7] "" Vector__XXX

BO_ 787 UI_trackModeSettings: 8 GTW
 SG_ UI_trackModeRequest : 0|2@1+ (1,0) [0|3] "" Vector__XXX
 SG_ UI_trackDrivePowerAvailability : 27|2@1+ (1,0) [0|3] "" Vector__XXX

BO_ 839 UI_tripPlanning: 8 GTW
 SG_ UI_tripPlanningActive : 0|1@1+ (1,0) [0|1] "" Vector__XXX
 SG_ UI_navToSupercharger : 1|1@1+ (1,0) [0|1] "" Vector__XXX
 SG_ UI_navFastchargerType : 2|3@1+ (1,0) [0|7] "" Vector__XXX
 SG_ UI_battPreconditionOnNavState : 5|2@1+ (1,0) [0|3] "" Vector__XXX
 SG_ UI_requestActiveBatteryHeating : 7|1@1+ (1,0) [0|1] "" Vector__XXX
 SG_ UI_battPreconditionOnNavPowerReq : 8|8@1- (125,0) [-16000|15750] "W" Vector__XXX
 SG_ UI_battPreconditionOnNavTargetT : 16|8@1+ (0.25,0) [0|63.5] "degC" Vector__XXX
 SG_ UI_energyAtDestination : 48|16@1- (0.01,0) [-327.67|327.67] "kWh" Vector__XXX

BO_ 627 UI_vehicleControl: 8 GTW
 SG_ UI_powerStateRequest : 0|2@1+ (1,0) [0|3] "" Vector__XXX
 SG_ UI_childDoorLockOnRight : 2|1@1+ (1,0) [0|1] "" Vector__XXX
 SG_ UI_frontFogSwitch : 3|1@1+ (1,0) [0|1] "" Vector__XXX
 SG_ UI_summonActive : 4|1@1+ (1,0) [0|1] "" Vector__XXX
 SG_ UI_frunkRequest : 5|1@1+ (1,0) [0|1] "" Vector__XXX
 SG_ UI_wiperMode : 6|2@1+ (1,0) [1|3] "" Vector__XXX
 SG_ UI_steeringButtonMode : 9|3@1+ (1,0) [0|7] "" Vector__XXX
 SG_ UI_walkUpUnlock : 12|1@1+ (1,0) [0|1] "" Vector__XXX
 SG_ UI_walkAwayLock : 13|1@1+ (1,0) [0|1] "" Vector__XXX
 SG_ UI_unlockOnPark : 14|1@1+ (1,0) [0|1] "" Vector__XXX
 SG_ UI_globalUnlockOn : 15|1@1+ (1,0) [0|1] "" Vector__XXX
 SG_ UI_childDoorLockOnLeft : 16|1@1+ (1,0) [0|1] "" Vector__XXX
 SG_ UI_lockRequest : 17|3@1+ (1,0) [0|6] "" Vector__XXX
 SG_ UI_alarmEnabled : 20|1@1+ (1,0) [0|1] "" Vector__XXX
 SG_ UI_stop12vSupport : 22|1@1+ (1,0) [0|1] "" Vector__XXX
 SG_ UI_rearFogSwitch : 23|1@1+ (1,0) [0|1] "" Vector__XXX
 SG_ UI_mirrorFoldRequest : 24|2@1+ (1,0) [0|2] "" Vector__XXX
 SG_ UI_mirrorHeatRequest : 26|1@1+ (1,0) [0|1] "" Vector__XXX
 SG_ UI_remoteStartRequest : 27|3@1+ (1,0) [0|7] "" Vector__XXX
 SG_ UI_seeYouHomeLightingOn : 30|1@1+ (1,0) [0|1] "" Vector__XXX
 SG_ UI_powerOff : 31|1@1+ (1,0) [0|1] "" Vector__XXX
 SG_ UI_displayBrightnessLevel : 32|8@1+ (0.5,0) [0|127] "%" Vector__XXX
 SG_ UI_autoHighBeamEnabled : 41|1@1+ (1,0) [0|1] "" Vector__XXX
 SG_ UI_frontLeftSeatHeatReq : 42|2@1+ (1,0) [0|3] "" Vector__XXX
 SG_ UI_frontRightSeatHeatReq : 44|2@1+ (1,0) [0|3] "" Vector__XXX
 SG_ UI_rearLeftSeatHeatReq : 46|2@1+ (1,0) [0|3] "" Vector__XXX
 SG_ UI_rearCenterSeatHeatReq : 48|2@1+ (1,0) [0|3] "" Vector__XXX
 SG_ UI_rearRightSeatHeatReq : 50|2@1+ (1,0) [0|3] "" Vector__XXX
 SG_ UI_autoFoldMirrorsOn : 52|1@1+ (1,0) [0|1] "" Vector__XXX
 SG_ UI_mirrorDipOnReverse : 53|1@1+ (1,0) [0|1] "" Vector__XXX
 SG_ UI_remoteClosureRequest : 54|2@1+ (1,0) [0|2] "" Vector__XXX
 SG_ UI_wiperRequest : 56|3@1+ (1,0) [1|7] "" Vector__XXX
 SG_ UI_domeLightSwitch : 59|2@1+ (1,0) [0|3] "" Vector__XXX

BO_ 947 UI_vehicleControl2: 8 GTW
 SG_ UI_gloveboxRequest : 0|1@1+ (1,0) [0|1] "" Vector__XXX
 SG_ UI_trunkRequest : 1|1@1+ (1,0) [0|1] "" Vector__XXX
 SG_ UI_PINToDriveEnabled : 6|1@1+ (1,0) [0|1] "" Vector__XXX
 SG_ UI_PINToDrivePassed : 7|1@1+ (1,0) [0|1] "" Vector__XXX
 SG_ UI_disableMirrorAutoDim : 8|1@1+ (1,0) [0|1] "" Vector__XXX
 SG_ UI_lightSwitch : 9|3@1+ (1,0) [0|7] "" Vector__XXX
 SG_ UI_readyToAddKey : 12|1@1+ (1,0) [0|1] "" Vector__XXX
 SG_ UI_alarmTriggerRequest : 13|1@1+ (1,0) [0|1] "" Vector__XXX
 SG_ UI_displayOnForUser : 18|1@1+ (1,0) [0|1] "" Vector__XXX
 SG_ UI_BLEPushNotificationRequest : 20|1@1+ (1,0) [0|1] "" Vector__XXX
 SG_ UI_keepAutopilotAwake : 22|1@1+ (1,0) [0|1] "" Vector__XXX
 SG_ UI_batteryPreconditioningRequest : 23|1@1+ (1,0) [0|1] "" Vector__XXX
 SG_ UI_autopilotPowerStateRequest : 25|2@1+ (1,0) [0|3] "" Vector__XXX
 SG_ UI_autoRollWindowsOnLockEnable : 29|1@1+ (1,0) [0|1] "" Vector__XXX
 SG_ UI_steeringWheelHeatReq : 33|1@1+ (1,0) [0|1] "" Vector__XXX
 SG_ UI_disableHorn : 34|1@1+ (1,0) [0|1] "" Vector__XXX
 SG_ UI_frontLeftSeatFanReq : 37|2@1+ (1,0) [0|3] "" Vector__XXX
 SG_ UI_frontRightSeatAutoClimateReq : 39|1@1+ (1,0) [0|1] "" Vector__XXX
 SG_ UI_frontRightSeatFanReq : 40|2@1+ (1,0) [0|3] "" Vector__XXX
 SG_ UI_frontLeftSeatAutoClimateReq : 56|1@1+ (1,0) [0|1] "" Vector__XXX
 SG_ UI_wiperHeaterReq : 57|1@1+ (1,0) [0|1] "" Vector__XXX
 SG_ UI_silentAlarm : 61|1@1+ (1,0) [0|1] "" Vector__XXX

BO_ 660 UI_vehicleControl3: 8 GTW
 SG_ UI_lightFlashRequest : 0|2@1+ (1,0) [0|3] "" Vector__XXX
 SG_ UI_phoneCallActive : 3|1@1+ (1,0) [0|1] "" Vector__XXX
 SG_ UI_lightShowClosuresEnabled : 8|1@1+ (1,0) [0|1] "" Vector__XXX
 SG_ UI_steeringWheelHeatAutoReq : 9|1@1+ (1,0) [0|1] "" Vector__XXX
 SG_ UI_steeringWheelHeatLevelReq : 10|2@1+ (1,0) [0|3] "" Vector__XXX
 SG_ UI_headlightPulseRequest : 12|1@1+ (1,0) [0|1] "" Vector__XXX
 SG_ UI_displayRedShiftActive : 24|1@1+ (1,0) [0|1] "" Vector__XXX
 SG_ UI_fasciaCameraWashRequest : 26|1@1+ (1,0) [0|1] "" Vector__XXX
 SG_ UI_leftRearSeatAdjustmentRequest : 28|3@1+ (1,0) [0|7] "" Vector__XXX
 SG_ UI_rightRearSeatAdjustmentReques : 32|3@1+ (1,0) [0|7] "" Vector__XXX
 SG_ UI_blindSpotIndicatorLightReques : 35|1@1+ (1,0) [0|1] "" Vector__XXX
 SG_ UI_keepOnAccessoryPortsReq : 38|1@1+ (1,0) [0|1] "" Vector__XXX
 SG_ UI_fasciaCameraShown : 39|1@1+ (1,0) [0|1] "" Vector__XXX
 SG_ UI_rearSeatChildLock : 40|2@1+ (1,0) [0|3] "" Vector__XXX
 SG_ UI_windowPercentageRequest : 42|6@1- (5,0) [-100|100] "%" Vector__XXX
 SG_ UI_windowRequestedFL : 48|1@1+ (1,0) [0|1] "" Vector__XXX
 SG_ UI_windowRequestedFR : 49|1@1+ (1,0) [0|1] "" Vector__XXX
 SG_ UI_windowRequestedRL : 50|1@1+ (1,0) [0|1] "" Vector__XXX
 SG_ UI_windowRequestedRR : 51|1@1+ (1,0) [0|1] "" Vector__XXX
 SG_ UI_windowRequest : 52|3@1+ (1,0) [0|7] "" Vector__XXX
 SG_ UI_closeTrunkRequest : 55|1@1+ (1,0) [0|1] "" Vector__XXX
 SG_ UI_childPresenceDetectionDisable : 56|1@1+ (1,0) [0|1] "" Vector__XXX
 SG_ UI_derivedLoadshedFeature : 59|1@1+ (1,0) [0|1] "" Vector__XXX
 SG_ UI_selfParkStandingBy : 62|1@1+ (1,0) [0|1] "" Vector__XXX

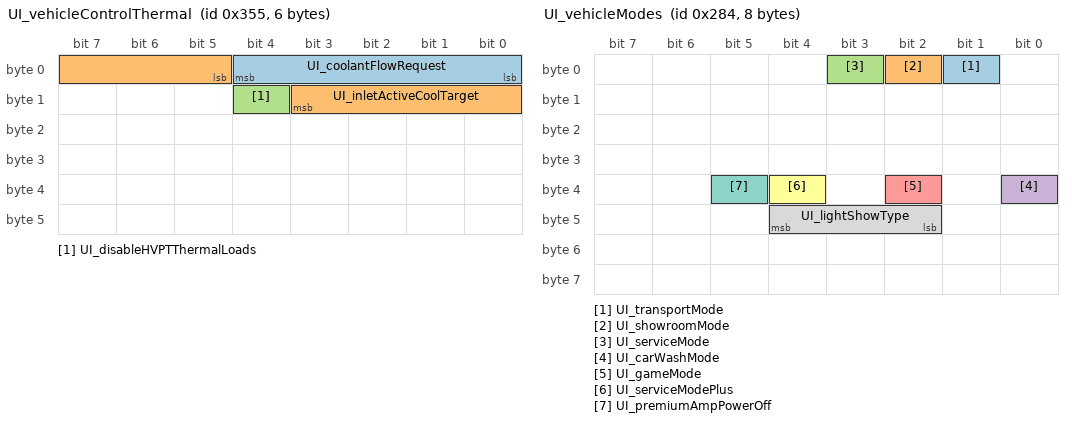
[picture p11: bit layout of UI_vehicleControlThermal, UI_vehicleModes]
BO_ 853 UI_vehicleControlThermal: 6 GTW
 SG_ UI_coolantFlowRequest : 0|5@1+ (1,0) [0|25] "LPM" Vector__XXX
 SG_ UI_inletActiveCoolTarget : 5|7@1+ (1,0) [0|127] "degC" Vector__XXX
 SG_ UI_disableHVPTThermalLoads : 12|1@1+ (1,0) [0|1] "" Vector__XXX

BO_ 644 UI_vehicleModes: 8 GTW
 SG_ UI_transportMode : 1|1@1+ (1,0) [0|1] "" Vector__XXX
 SG_ UI_showroomMode : 2|1@1+ (1,0) [0|1] "" Vector__XXX
 SG_ UI_serviceMode : 3|1@1+ (1,0) [0|1] "" Vector__XXX
 SG_ UI_carWashMode : 32|1@1+ (1,0) [0|1] "" Vector__XXX
 SG_ UI_gameMode : 34|1@1+ (1,0) [0|1] "" Vector__XXX
 SG_ UI_serviceModePlus : 36|1@1+ (1,0) [0|1] "" Vector__XXX
 SG_ UI_premiumAmpPowerOff : 37|1@1+ (1,0) [0|1] "" Vector__XXX
 SG_ UI_lightShowType : 42|3@1+ (1,0) [0|7] "" Vector__XXX

BO_ 595 UI_ventPanelControlRequest: 8 GTW
 SG_ UI_ventPanelControlRequestIndex M : 0|1@1+ (1,0) [0|1] "" Vector__XXX
 SG_ UI_ventPanelLeftPositionX m0 : 8|8@1+ (0.5,0) [0|100] "%" Vector__XXX
 SG_ UI_ventPanelLeftPositionY m0 : 16|8@1+ (0.5,0) [0|100] "%" Vector__XXX
 SG_ UI_ventPanelLeftLateralSplit m0 : 24|8@1+ (0.5,0) [0|100] "%" Vector__XXX
 SG_ UI_ventPanelRightPositionX m0 : 32|8@1+ (0.5,0) [0|100] "%" Vector__XXX
 SG_ UI_ventPanelRightPositionY m0 : 40|8@1+ (0.5,0) [0|100] "%" Vector__XXX
 SG_ UI_ventPanelRightLateralSplit m0 : 48|8@1+ (0.5,0) [0|100] "%" Vector__XXX
 SG_ UI_ventPanelLeftLateralMode m0 : 56|2@1+ (1,0) [0|3] "" Vector__XXX
 SG_ UI_ventPanelRightLateralMode m0 : 58|2@1+ (1,0) [0|3] "" Vector__XXX
 SG_ UI_hvacReqActiveVents m0 : 60|2@1+ (1,0) [0|3] "" Vector__XXX
 SG_ UI_vent2RLeftPositionX m1 : 8|8@1+ (0.5,0) [0|100] "%" Vector__XXX
 SG_ UI_vent2RLeftPositionY m1 : 16|8@1+ (0.5,0) [0|100] "%" Vector__XXX
 SG_ UI_vent2RRightPositionX m1 : 24|8@1+ (0.5,0) [0|100] "%" Vector__XXX
 SG_ UI_vent2RRightPositionY m1 : 32|8@1+ (0.5,0) [0|100] "%" Vector__XXX

BO_ 1285 UMC_smartAdapterInfo: 8 UMC
 SG_ SA_infoIndex M : 0|8@1+ (1,0) [0|255] "" Vector__XXX
 SG_ SA_genealogyVersion m0 : 8|8@1+ (1,0) [0|255] "" Vector__XXX
 SG_ SA_genealogyCrc m0 : 16|32@1+ (1,0) [0|4294967295] "" Vector__XXX
 SG_ SA_region m0 : 48|4@1+ (1,0) [0|15] "" Vector__XXX
 SG_ SA_OverTempThreshold m0 : 56|8@1+ (1,0) [0|255] "" Vector__XXX
 SG_ SA_partNumInt m31 : 8|32@1+ (1,0) [0|4294967295] "" Vector__XXX
 SG_ SA_partNumRev m31 : 40|8@1+ (1,0) [0|255] "" Vector__XXX
 SG_ SA_currentLimit m31 : 48|8@1+ (1,0) [0|255] "" Vector__XXX
 SG_ SA_l1Voltage m31 : 56|8@1+ (1,0) [0|255] "" Vector__XXX

BO_TX_BU_ 516 : PCS;
BO_TX_BU_ 692 : PCS;
BO_TX_BU_ 548 : PCS;
BO_TX_BU_ 964 : PCS;
BO_TX_BU_ 708 : PCS;
BO_TX_BU_ 676 : PCS;
BO_TX_BU_ 790 : PMF;
BO_TX_BU_ 1748 : PMR;
BO_TX_BU_ 1551 : PM;
BO_TX_BU_ 837 : PTC;
BO_TX_BU_ 647 : PTC;
BO_TX_BU_ 816 : SCCM;
BO_TX_BU_ 585 : SCCM;
BO_TX_BU_ 553 : SCCM;
BO_TX_BU_ 297 : SCCM;
BO_TX_BU_ 1597 : SDCR;
BO_TX_BU_ 523 : TAS;
BO_TX_BU_ 1398 : TAS;
BO_TX_BU_ 1357 : TAS;
BO_TX_BU_ 525 : TAS;
BO_TX_BU_ 409 : TAS;
BO_TX_BU_ 410 : TAS;
BO_TX_BU_ 538 : TAS;
BO_TX_BU_ 1657 : GTW;
BO_TX_BU_ 1021 : GTW;
BO_TX_BU_ 819 : GTW;
BO_TX_BU_ 659 : GTW;
BO_TX_BU_ 531 : GTW;
BO_TX_BU_ 568 : GTW;
BO_TX_BU_ 645 : GTW;
BO_TX_BU_ 651 : GTW;
BO_TX_BU_ 1139 : GTW;
BO_TX_BU_ 883 : GTW;
BO_TX_BU_ 755 : GTW;
BO_TX_BU_ 1523 : GTW;
BO_TX_BU_ 948 : GTW;
BO_TX_BU_ 827 : GTW;
BO_TX_BU_ 820 : GTW;
BO_TX_BU_ 826 : GTW;
BO_TX_BU_ 723 : GTW;
BO_TX_BU_ 851 : GTW;
BO_TX_BU_ 991 : GTW;
BO_TX_BU_ 663 : GTW;
BO_TX_BU_ 787 : GTW;
BO_TX_BU_ 839 : GTW;
BO_TX_BU_ 627 : GTW;
BO_TX_BU_ 947 : GTW;
BO_TX_BU_ 660 : GTW;
BO_TX_BU_ 853 : GTW;
BO_TX_BU_ 644 : GTW;
BO_TX_BU_ 595 : GTW;
BO_TX_BU_ 1285 : UMC;
CM_ BO_ 516 "Power conversion system (on-board charger and DC-DC converter) message: chg status";
CM_ SG_ 516 PCS_chgMainState "Power conversion system (on-board charger and DC-DC converter): chg main state";
CM_ SG_ 516 PCS_gridConfig "AC charger sensed grid configuration; raw 0 = signal not available (SNA)";
CM_ SG_ 516 PCS_chgPHAEnable "Indicates whether AC charger phase A is enabled";
CM_ SG_ 516 PCS_chgPHBEnable "Indicates whether AC charger phase B is enabled";
CM_ SG_ 516 PCS_hvInletConductorEnergizedAc "Power conversion system (on-board charger and DC-DC converter): hv inlet conductor energized ac";
CM_ SG_ 516 PCS_chgHighPowerActive "Power conversion system (on-board charger and DC-DC converter): chg high power active";
CM_ SG_ 516 PCS_chgPHCEnable "Indicates whether AC charger phase C is enabled";
CM_ SG_ 516 PCS_chgInstantAcPowerAvailable "Instantaneous power capability of the AC charger";
CM_ SG_ 516 PCS_chgMaxAcPowerAvailable "Maximum power capability of the AC charger; raw 255 = signal not available (SNA)";
CM_ SG_ 516 PCS_chgPHALineCurrentRequest "AC charger phase A input current command";
CM_ SG_ 516 PCS_chgPHBLineCurrentRequest "AC charger phase B input current command";
CM_ SG_ 516 PCS_chgPHCLineCurrentRequest "AC charger phase B input current command";
CM_ SG_ 516 PCS_chgPwmEnableLine "Sensed state of the charger PWM enable hardline";
CM_ SG_ 516 PCS_hwVariantType "Hardware variant of AC charger; raw 3 = signal not available (SNA)";
CM_ BO_ 692 "Power conversion system (on-board charger and DC-DC converter) message: dcdc rail status";
CM_ SG_ 692 PCS_dcdcLvBusVolt "DCDC's sensed LV bus voltage";
CM_ SG_ 692 PCS_dcdcHvBusVolt "DCDC's sensed HV bus voltage";
CM_ SG_ 692 PCS_dcdcLvOutputCurrent "DCDC's computed LV output current";
CM_ BO_ 548 "Power conversion system (on-board charger and DC-DC converter) message: dcdc status";
CM_ SG_ 548 PCS_dcdcPrechargeStatus "Status of DCDC HV bus precharge";
CM_ SG_ 548 PCS_dcdcLvSupportStatus "Status of DCDC LV support";
CM_ SG_ 548 PCS_dcdcHvBusDischargeStatus "Power conversion system (on-board charger and DC-DC converter): dcdc hv bus discharge status";
CM_ SG_ 548 PCS_coldSleepAllowed "Power conversion system (on-board charger and DC-DC converter): cold sleep allowed";
CM_ SG_ 548 PCS_dcdcPchgHVBusLowRDetected "Power conversion system (on-board charger and DC-DC converter): dcdc pchg HV bus low r detected";
CM_ SG_ 548 PCS_dcdcSubState "Substate of DCDC state machine";
CM_ SG_ 548 PCS_dcdcFaulted "Whether the DCDC is in faulted state";
CM_ SG_ 548 PCS_okToBePowerCycled "Power conversion system (on-board charger and DC-DC converter): ok to be power cycled";
CM_ SG_ 548 PCS_dcdcOutputIsLimited "Whether the DCDC's output is current limiting";
CM_ SG_ 548 PCS_dcdcMaxOutputCurrentAllowed "Maximum LV output current capability of DCDC based on operating point";
CM_ SG_ 548 PCS_dcdcPrechargeRtyCnt "Power conversion system (on-board charger and DC-DC converter): dcdc precharge rty cnt";
CM_ SG_ 548 PCS_dcdcLvSupportRtyCnt "Power conversion system (on-board charger and DC-DC converter): dcdc lv support rty cnt";
CM_ SG_ 548 PCS_dcdcDischargeRtyCnt "Power conversion system (on-board charger and DC-DC converter): dcdc discharge rty cnt";
CM_ SG_ 548 PCS_dcdcPwmEnableLine "Sensed state of the DCDC PWM enable hardline";
CM_ SG_ 548 PCS_dcdcSupportingFixedLvTarget "Whether DCDC is running LV support at a fixed voltage target";
CM_ SG_ 548 PCS_ecuLogUploadRequest "Power conversion system (on-board charger and DC-DC converter): ecu log upload request";
CM_ SG_ 548 PCS_dcdcPrechargeRestartCnt "Power conversion system (on-board charger and DC-DC converter): dcdc precharge restart cnt";
CM_ SG_ 548 PCS_dcdcInitialPrechargeSubState "Power conversion system (on-board charger and DC-DC converter): dcdc initial precharge sub state";
CM_ BO_ 964 "Power conversion system (on-board charger and DC-DC converter) message: info";
CM_ SG_ 964 PCS_infoIndex "Power conversion system (on-board charger and DC-DC converter): info index";
CM_ SG_ 964 PCS_buildType "Power conversion system (on-board charger and DC-DC converter): build type";
CM_ SG_ 964 PCS_buildConfigId "Power conversion system (on-board charger and DC-DC converter): build config id";
CM_ SG_ 964 PCS_hardwareId "Power conversion system (on-board charger and DC-DC converter): hardware id";
CM_ SG_ 964 PCS_componentId "Power conversion system (on-board charger and DC-DC converter): component id";
CM_ SG_ 964 PCS_pcbaId "PCBA ID portion of component hardware ID as reported by application";
CM_ SG_ 964 PCS_assemblyId "Power conversion system (on-board charger and DC-DC converter): assembly id";
CM_ SG_ 964 PCS_usageId "Usage ID portion of component hardware ID as reported by application";
CM_ SG_ 964 PCS_subUsageId "Sub-usage ID portion of component hardware ID as reported by application";
CM_ SG_ 964 PCS_platformType "Power conversion system (on-board charger and DC-DC converter): platform type";
CM_ SG_ 964 PCS_appCrc "Power conversion system (on-board charger and DC-DC converter): app crc";
CM_ SG_ 964 PCS_cpu2AppCrc "Power conversion system (on-board charger and DC-DC converter): cpu2 app crc";
CM_ SG_ 964 PCS_appGitHash "Power conversion system (on-board charger and DC-DC converter): app git hash";
CM_ SG_ 964 PCS_bootGitHash "Power conversion system (on-board charger and DC-DC converter): boot git hash";
CM_ SG_ 964 PCS_bootUdsProtoVersion "Power conversion system (on-board charger and DC-DC converter): boot uds proto version";
CM_ SG_ 964 PCS_bootCrc "Power conversion system (on-board charger and DC-DC converter): boot crc";
CM_ BO_ 708 "Power conversion system (on-board charger and DC-DC converter) message: logging";
CM_ SG_ 708 PCS_logMessageSelect "Power conversion system (on-board charger and DC-DC converter): log message select";
CM_ SG_ 708 PCS_chgPhAInputIrms "AC charger phase A's sensed RMS input current";
CM_ SG_ 708 PCS_chgPhAIntBusV "AC charger phase A's sensed intermediate bus voltage";
CM_ SG_ 708 PCS_chgPhAIntBusVTarget "AC charger phase A's intermediate bus voltage target";
CM_ SG_ 708 PCS_chgPhAOutputI "AC charger phase A sensed output current";
CM_ SG_ 708 PCS_chgPhAInputCurrentLimitReaso "Provides the reason behind the input AC charging current limit for phase A";
CM_ SG_ 708 PCS_chgPhBInputIrms "AC charger phase B's sensed RMS input current";
CM_ SG_ 708 PCS_chgPhBIntBusV "AC charger phase B's sensed intermediate bus voltage";
CM_ SG_ 708 PCS_chgPhBIntBusVTarget "AC charger phase B's intermediate bus voltage target";
CM_ SG_ 708 PCS_chgPhBOutputI "AC charger phase B sensed output current";
CM_ SG_ 708 PCS_chgPhBInputCurrentLimitReaso "Provides the reason behind the input AC charging current limit for phase B";
CM_ SG_ 708 PCS_chgPhCInputIrms "AC charger phase C's sensed RMS input current";
CM_ SG_ 708 PCS_chgPhCIntBusV "AC charger phase C's sensed intermediate bus voltage";
CM_ SG_ 708 PCS_chgPhCIntBusVTarget "AC charger phase C's intermediate bus voltage target";
CM_ SG_ 708 PCS_chgPhCOutputI "AC charger phase C sensed output current";
CM_ SG_ 708 PCS_chgPhCInputCurrentLimitReaso "Provides the reason behind the input AC charging current limit for phase C";
CM_ SG_ 708 PCS_chgInputL1NVrms "AC charger's sensed AC RMS voltage of L1-N voltage source";
CM_ SG_ 708 PCS_chgInputL2NVrms "AC charger's sensed AC RMS voltage of L2-N voltage source";
CM_ SG_ 708 PCS_chgInputL3NVrms "AC charger's sensed AC RMS voltage of L3-N voltage source";
CM_ SG_ 708 PCS_chgInputL1L2Vrms "AC charger's sensed input frequency of L2-N voltage source";
CM_ SG_ 708 PCS_chgInputNGVrms "AC charger's sensed AC RMS voltage of N-G voltage source";
CM_ SG_ 708 PCS_chgInputFrequencyL1N "AC charger's sensed input frequency of L1-N voltage source";
CM_ SG_ 708 PCS_chgInputFrequencyL2N "AC charger's sensed input frequency of L2-N voltage source";
CM_ SG_ 708 PCS_chgInputFrequencyL3N "AC charger's sensed input frequency of L3-N voltage source";
CM_ SG_ 708 PCS_chgInternalPhaseConfig "Internal phase configuration of the AC charger (three phase vs. single phase); raw 0 = signal not available (SNA)";
CM_ SG_ 708 PCS_chgPhasesPriority "AC charger phase manager's priority logic for enabling phases in single phase PCS variant";
CM_ SG_ 708 PCS_chgOutputV "Sensed output voltage of AC charger";
CM_ SG_ 708 PCS_chgPhAState "State of AC charger phase A";
CM_ SG_ 708 PCS_chgPhBState "State of AC charger phase B";
CM_ SG_ 708 PCS_chgPhCState "State of AC charger phase C";
CM_ SG_ 708 PCS_chgPhALastShutdownReason "Last reason for shutting down AC charger phase A";
CM_ SG_ 708 PCS_chgPhBLastShutdownReason "Last reason for shutting down AC charger phase B";
CM_ SG_ 708 PCS_chgPhCLastShutdownReason "Last reason for shutting down AC charger phase C";
CM_ SG_ 708 PCS_chgPhARetryCount "AC charger phase A number of retries used during the current charge session";
CM_ SG_ 708 PCS_chgPhBRetryCount "AC charger phase B number of retries used during the current charge session";
CM_ SG_ 708 PCS_chgPhCRetryCount "AC charger phase C number of retries used during the current charge session";
CM_ SG_ 708 PCS_chgRetryCount "AC charger number of system level retries used during the current charge session";
CM_ SG_ 708 PCS_chgPhManCurrentToDist "Power conversion system (on-board charger and DC-DC converter): chg ph man current to dist";
CM_ SG_ 708 PCS_chgL1NPllLocked "Power conversion system (on-board charger and DC-DC converter): chg L1 n pll locked";
CM_ SG_ 708 PCS_chgL2NPllLocked "Power conversion system (on-board charger and DC-DC converter): chg L2 n pll locked";
CM_ SG_ 708 PCS_chgL3NPllLocked "Power conversion system (on-board charger and DC-DC converter): chg L3 n pll locked";
CM_ SG_ 708 PCS_chgL1L2PllLocked "Power conversion system (on-board charger and DC-DC converter): chg L1 L2 pll locked";
CM_ SG_ 708 PCS_chgNgPllLocked "Power conversion system (on-board charger and DC-DC converter): chg ng pll locked";
CM_ SG_ 708 PCS_chgPhManOptimalPhsToUse "Power conversion system (on-board charger and DC-DC converter): chg ph man optimal phs to use";
CM_ SG_ 708 PCS_chg5VL1Enable "Power conversion system (on-board charger and DC-DC converter): chg5 VL1 enable";
CM_ SG_ 708 PCS_dcdcMaxLvOutputCurrent "Overall maxmum LV output current capability of DCDC";
CM_ SG_ 708 PCS_dcdcCurrentLimit "Power conversion system (on-board charger and DC-DC converter): dcdc current limit";
CM_ SG_ 708 PCS_dcdcLvOutputCurrentTempLimit "Maximum LV output current capability of DCDC based on thermals";
CM_ SG_ 708 PCS_dcdcLvOutputCurrentFiltered "DCDC's filtered LV output current";
CM_ SG_ 708 PCS_dcdcUnifiedCommand "Power conversion system (on-board charger and DC-DC converter): dcdc unified command";
CM_ SG_ 708 PCS_dcdcCLAControllerOutput "Power conversion system (on-board charger and DC-DC converter): dcdc CLA controller output";
CM_ SG_ 708 PCS_dcdcTankVoltage "Power conversion system (on-board charger and DC-DC converter): dcdc tank voltage; raw 1024 = signal not available (SNA)";
CM_ SG_ 708 PCS_dcdcTankVoltageTarget "Power conversion system (on-board charger and DC-DC converter): dcdc tank voltage target";
CM_ SG_ 708 PCS_dcdcClaCurrentFreq "Power conversion system (on-board charger and DC-DC converter): dcdc cla current freq";
CM_ SG_ 708 PCS_dcdcTCommMeasured "Power conversion system (on-board charger and DC-DC converter): dcdc t comm measured";
CM_ SG_ 708 PCS_dcdcShortTimeUs "Power conversion system (on-board charger and DC-DC converter): dcdc short time us";
CM_ SG_ 708 PCS_dcdcHalfPeriodUs "Power conversion system (on-board charger and DC-DC converter): dcdc half period us";
CM_ SG_ 708 PCS_dcdcLvBusVoltTargetWithOffse "LV support Voltage target with Feed-forward offset";
CM_ SG_ 708 PCS_cpu2BootState "Power conversion system (on-board charger and DC-DC converter): cpu2 boot state";
CM_ SG_ 708 PCS_acChargeSelfTestState "Power conversion system (on-board charger and DC-DC converter): ac charge self test state";
CM_ SG_ 708 PCS_1V5Min10s "Power conversion system (on-board charger and DC-DC converter): 1 V5 min10s";
CM_ SG_ 708 PCS_1V5Max10s "Power conversion system (on-board charger and DC-DC converter): 1 V5 max10s";
CM_ SG_ 708 PCS_1V2Min10s "Power conversion system (on-board charger and DC-DC converter): 1 V2 min10s";
CM_ SG_ 708 PCS_1V2Max10s "Power conversion system (on-board charger and DC-DC converter): 1 V2 max10s";
CM_ SG_ 708 PCS_5VNMax10s "Power conversion system (on-board charger and DC-DC converter): 5 VN max10s";
CM_ SG_ 708 PCS_chgPhAIntBusVMin10s "AC charger phase A's minimum sensed intermediate bus voltage over the last ten seconds";
CM_ SG_ 708 PCS_chgPhAIntBusVMax10s "AC charger phase A's maximum sensed intermediate bus voltage over the last ten seconds";
CM_ SG_ 708 PCS_chgPhAPchgVoltDeltaMax10s "AC charger phase A maximum sensed voltage delta between line and intermediate bus in the last 10 seconds during SCR precharge";
CM_ SG_ 708 PCS_chgPhALifetimekWh "Lifetime total energy throughput of AC charger phase A";
CM_ SG_ 708 PCS_chgPhATransientRetryCount "AC charger phase A number of transient retries used during the current charge session";
CM_ SG_ 708 PCS_chgPhBIntBusVMin10s "AC charger phase B's minimum sensed intermediate bus voltage over the last ten seconds";
CM_ SG_ 708 PCS_chgPhBIntBusVMax10s "AC charger phase B's maximum sensed intermediate bus voltage over the last ten seconds";
CM_ SG_ 708 PCS_chgPhBPchgVoltDeltaMax10s "AC charger phase B maximum sensed voltage delta between line and intermediate bus in the last 10 seconds during SCR precharge";
CM_ SG_ 708 PCS_chgPhBLifetimekWh "Lifetime total energy throughput of AC charger phase B";
CM_ SG_ 708 PCS_chgPhBTransientRetryCount "AC charger phase B number of transient retries used during the current charge session";
CM_ SG_ 708 PCS_chgPhCIntBusVMin10s "AC charger phase C's minimum sensed intermediate bus voltage over the last ten seconds";
CM_ SG_ 708 PCS_chgPhCIntBusVMax10s "AC charger phase C's maximum sensed intermediate bus voltage over the last ten seconds";
CM_ SG_ 708 PCS_chgPhCPchgVoltDeltaMax10s "AC charger phase C maximum sensed voltage delta between line and intermediate bus in the last 10 seconds during SCR precharge";
CM_ SG_ 708 PCS_chgPhCLifetimekWh "Lifetime total energy throughput of AC charger phase C";
CM_ SG_ 708 PCS_chgPhCTransientRetryCount "AC charger phase C number of transient retries used during the current charge session";
CM_ SG_ 708 PCS_chgPhANoFlowBucket "Power conversion system (on-board charger and DC-DC converter): chg ph a no flow bucket";
CM_ SG_ 708 PCS_chgPhBNoFlowBucket "Power conversion system (on-board charger and DC-DC converter): chg ph b no flow bucket";
CM_ SG_ 708 PCS_chgPhCNoFlowBucket "Power conversion system (on-board charger and DC-DC converter): chg ph c no flow bucket";
CM_ SG_ 708 PCS_chgCurrentSensorOutOfBandUs "Power conversion system (on-board charger and DC-DC converter): chg current sensor out of band us";
CM_ SG_ 708 PCS_chgAcpwHeartbeatState "A signal to indicate if PCS detects the heartbeat signature from AC Power Wall";
CM_ SG_ 708 PCS_chgKwhLostByFreqDroop "Power conversion system (on-board charger and DC-DC converter): chg kwh lost by freq droop";
CM_ SG_ 708 PCS_chgReqKwhLostByFreqDroop "Power conversion system (on-board charger and DC-DC converter): chg req kwh lost by freq droop";
CM_ SG_ 708 PCS_dcdcLvSupportLifetimekWh "Lifetime energy throughput of DCDC LV support mode";
CM_ SG_ 708 PCS_chgPwmEnableLineErrorCount "Power conversion system (on-board charger and DC-DC converter): chg pwm enable line error count";
CM_ SG_ 708 PCS_dcdcPwmEnableLineErrorCount "Number of deassertions detected for DCDC PWM enable line";
CM_ SG_ 708 PCS_numAlertsSet "Power conversion system (on-board charger and DC-DC converter): num alerts set";
CM_ SG_ 708 PCS_dcdcPchgStartLvBusVolt "Sensed LV bus votlage when beginning DCDC precharge";
CM_ SG_ 708 PCS_dcdcPchgStartHvBusVolt "Sensed HV bus votlage when beginning DCDC precharge";
CM_ SG_ 708 PCS_processorDieIdLot "Power conversion system (on-board charger and DC-DC converter): processor die id lot";
CM_ SG_ 708 PCS_processorDieIdWafer "Power conversion system (on-board charger and DC-DC converter): processor die id wafer";
CM_ SG_ 708 PCS_processorDieIdX "Power conversion system (on-board charger and DC-DC converter): processor die id x";
CM_ SG_ 708 PCS_processorDieIdY "Power conversion system (on-board charger and DC-DC converter): processor die id y";
CM_ BO_ 676 "Power conversion system (on-board charger and DC-DC converter) message: thermal status";
CM_ SG_ 676 PCS_chgPhATemp "Sensed temperature of AC charger phase A; raw 1025 = signal not available (SNA)";
CM_ SG_ 676 PCS_chgPhBTemp "Sensed temperature of AC charger phase B; raw 1025 = signal not available (SNA)";
CM_ SG_ 676 PCS_chgPhCTemp "Sensed temperature of AC charger phase C; raw 1025 = signal not available (SNA)";
CM_ SG_ 676 PCS_dcdcTemp "Sensed temperature of DCDC; raw 1025 = signal not available (SNA)";
CM_ SG_ 676 PCS_ambientTemp "Ambient temperature sensed by the PCS; raw 1025 = signal not available (SNA)";
CM_ SG_ 676 PCS_dcdcBusbarTemp "Sensed temperature of DCDC busbar; raw 511 = signal not available (SNA)";
CM_ BO_ 790 "PMF ECU message: info";
CM_ SG_ 790 PMF_infoIndex "PMF ECU: info index";
CM_ SG_ 790 PMF_buildType "PMF ECU: build type";
CM_ SG_ 790 PMF_buildConfigurationId "PMF ECU: build configuration id";
CM_ SG_ 790 PMF_hardwareId "PMF ECU: hardware id";
CM_ SG_ 790 PMF_deviceFused "PMF ECU: device fused";
CM_ SG_ 790 PMF_componentId "PMF ECU: component id";
CM_ SG_ 790 PMF_pcbaId "PMF ECU: pcba id";
CM_ SG_ 790 PMF_assemblyId "PMF ECU: assembly id";
CM_ SG_ 790 PMF_usageId "PMF ECU: usage id";
CM_ SG_ 790 PMF_subUsageId "PMF ECU: sub usage id";
CM_ SG_ 790 PMF_applicationCrc "PMF ECU: application crc";
CM_ SG_ 790 PMF_appGitHash "PMF ECU: app git hash";
CM_ SG_ 790 PMF_bootGitHash "PMF ECU: boot git hash";
CM_ SG_ 790 PMF_platformTyp "PMF ECU: platform typ";
CM_ SG_ 790 PMF_udsProtocolVersion "PMF ECU: uds protocol version";
CM_ SG_ 790 PMF_bootloaderCrc "PMF ECU: bootloader crc";
CM_ BO_ 1748 "PMR ECU message: info";
CM_ SG_ 1748 PMR_infoIndex "PMR ECU: info index";
CM_ SG_ 1748 PMR_buildType "PMR ECU: build type";
CM_ SG_ 1748 PMR_buildConfigurationId "PMR ECU: build configuration id";
CM_ SG_ 1748 PMR_hardwareId "PMR ECU: hardware id";
CM_ SG_ 1748 PMR_deviceFused "PMR ECU: device fused";
CM_ SG_ 1748 PMR_componentId "PMR ECU: component id";
CM_ SG_ 1748 PMR_pcbaId "PMR ECU: pcba id";
CM_ SG_ 1748 PMR_assemblyId "PMR ECU: assembly id";
CM_ SG_ 1748 PMR_usageId "PMR ECU: usage id";
CM_ SG_ 1748 PMR_subUsageId "PMR ECU: sub usage id";
CM_ SG_ 1748 PMR_applicationCrc "PMR ECU: application crc";
CM_ SG_ 1748 PMR_appGitHash "PMR ECU: app git hash";
CM_ SG_ 1748 PMR_bootGitHash "PMR ECU: boot git hash";
CM_ SG_ 1748 PMR_platformTyp "PMR ECU: platform typ";
CM_ SG_ 1748 PMR_udsProtocolVersion "PMR ECU: uds protocol version";
CM_ SG_ 1748 PMR_bootloaderCrc "PMR ECU: bootloader crc";
CM_ BO_ 1551 "PM ECU message: info";
CM_ SG_ 1551 PM_infoIndex "PM ECU: info index";
CM_ SG_ 1551 PM_buildType "PM ECU: build type";
CM_ SG_ 1551 PM_buildConfigurationId "PM ECU: build configuration id";
CM_ SG_ 1551 PM_hardwareId "PM ECU: hardware id";
CM_ SG_ 1551 PM_deviceFused "PM ECU: device fused";
CM_ SG_ 1551 PM_componentId "PM ECU: component id";
CM_ SG_ 1551 PM_pcbaId "PM ECU: pcba id";
CM_ SG_ 1551 PM_assemblyId "PM ECU: assembly id";
CM_ SG_ 1551 PM_usageId "PM ECU: usage id";
CM_ SG_ 1551 PM_subUsageId "PM ECU: sub usage id";
CM_ SG_ 1551 PM_applicationCrc "PM ECU: application crc";
CM_ SG_ 1551 PM_bootGitHash "PM ECU: boot git hash";
CM_ BO_ 837 "Cabin heater message: info";
CM_ SG_ 837 PTC_infoIndex "Cabin heater: info index";
CM_ SG_ 837 PTC_infoBuildType "Cabin heater: info build type";
CM_ SG_ 837 PTC_infoBuildConfigId "Cabin heater: info build config id";
CM_ SG_ 837 PTC_infoHardwareId "Cabin heater: info hardware id";
CM_ SG_ 837 PTC_infoComponentId "Cabin heater: info component id";
CM_ SG_ 837 PTC_infoPcbaId "Cabin heater: info pcba id";
CM_ SG_ 837 PTC_infoAssemblyId "Cabin heater: info assembly id; raw 255 = signal not available (SNA)";
CM_ SG_ 837 PTC_infoUsageId "Cabin heater: info usage id";
CM_ SG_ 837 PTC_infoSubUsageId "Cabin heater: info sub usage id";
CM_ SG_ 837 PTC_infoPlatformType "Cabin heater: info platform type";
CM_ SG_ 837 PTC_infoAppCrc "Cabin heater: info app crc";
CM_ SG_ 837 PTC_infoBootUdsProtoVersion "Cabin heater: info boot uds proto version";
CM_ SG_ 837 PTC_infoBootCrc "Cabin heater: info boot crc";
CM_ BO_ 647 "Cabin heater message: sensor status";
CM_ SG_ 647 PTC_leftTempIGBT "Heater left bank IGBT temperature";
CM_ SG_ 647 PTC_tempOCP "Temperature measured near the over current protection circuit";
CM_ SG_ 647 PTC_rightTempIGBT "Heater right bank IGBT temperature";
CM_ SG_ 647 PTC_tempPCB "Heater printed circuit board temperature";
CM_ SG_ 647 PTC_voltageHV "Heater high voltage input voltage";
CM_ SG_ 647 PTC_leftCurrentHV "Cabin heater: left current HV";
CM_ SG_ 647 PTC_rightCurrentHV "Cabin heater: right current HV";
CM_ BO_ 816 "Steering column control module message: info";
CM_ SG_ 816 SCCM_infoIndex "Steering column control module: info index";
CM_ SG_ 816 SCCM_infoBuildType "Steering column control module: info build type";
CM_ SG_ 816 SCCM_infoBuildConfigId "Steering column control module: info build config id";
CM_ SG_ 816 SCCM_infoHardwareId "Steering column control module: info hardware id";
CM_ SG_ 816 SCCM_infoComponentId "Steering column control module: info component id";
CM_ SG_ 816 SCCM_infoPcbaId "Steering column control module: info pcba id";
CM_ SG_ 816 SCCM_infoAssemblyId "Steering column control module: info assembly id";
CM_ SG_ 816 SCCM_infoUsageId "Steering column control module: info usage id";
CM_ SG_ 816 SCCM_infoSubUsageId "Steering column control module: info sub usage id";
CM_ SG_ 816 SCCM_infoPlatformType "Steering column control module: info platform type";
CM_ SG_ 816 SCCM_infoAppCrc "Steering column control module: info app crc";
CM_ SG_ 816 SCCM_infoBootSvnRev "Steering column control module: info boot svn rev";
CM_ SG_ 816 SCCM_infoBootSvnUrlHash "Steering column control module: info boot svn url hash";
CM_ SG_ 816 SCCM_infoSubcomponent1Version "Steering column control module: info subcomponent1 version";
CM_ SG_ 816 SCCM_infoAppSvnHash "Steering column control module: info app svn hash";
CM_ SG_ 816 SCCM_infoBootSvnHash "Steering column control module: info boot svn hash";
CM_ SG_ 816 SCCM_infoUdsProtoVersion "Steering column control module: info uds proto version";
CM_ SG_ 816 SCCM_infoBootCrc "Steering column control module: info boot crc";
CM_ BO_ 585 "Steering column control module message: left stalk";
CM_ SG_ 585 SCCM_leftStalkCrc "Steering column control module: left stalk crc";
CM_ SG_ 585 SCCM_leftStalkCounter "Steering column control module: left stalk counter";
CM_ SG_ 585 SCCM_highBeamStalkStatus "Active state of high beam push/pull stalk position; raw 3 = signal not available (SNA)";
CM_ SG_ 585 SCCM_washWipeButtonStatus "Active state of wash/wipe button on the turn signal stalk; raw 3 = signal not available (SNA)";
CM_ SG_ 585 SCCM_turnIndicatorStalkStatus "Active state of turn indicator stalk position; raw 9 = signal not available (SNA)";
CM_ SG_ 585 SCCM_turnIndicatorStalkAngle "Measured angle of the turn signal stalk; raw 4095 = signal not available (SNA)";
CM_ BO_ 553 "Steering column control module message: right stalk";
CM_ SG_ 553 SCCM_rightStalkCrc "Steering column control module: right stalk crc";
CM_ SG_ 553 SCCM_rightStalkCounter "Steering column control module: right stalk counter";
CM_ SG_ 553 SCCM_rightStalkStatus "Active state of drive stalk position, does not indicate active drive gear; raw 6 = signal not available (SNA)";
CM_ SG_ 553 SCCM_rightStalkReserved1 "Steering column control module: right stalk reserved1";
CM_ SG_ 553 SCCM_parkButtonStatus "Active state of park button on the drive stalk; raw 3 = signal not available (SNA)";
CM_ SG_ 553 SCCM_rightStalkReserved2 "Steering column control module: right stalk reserved2";
CM_ BO_ 297 "Steering column control module message: steering angle sensor";
CM_ SG_ 297 SCCM_steeringAngleCrc "Steering column control module: steering angle crc";
CM_ SG_ 297 SCCM_steeringAngleCounter "Message counter";
CM_ SG_ 297 SCCM_supplierID "Steering column control module: supplier ID";
CM_ SG_ 297 SCCM_steeringAngleSensorStatus "Reports steering angle sensor status and validity based on bootup checks";
CM_ SG_ 297 SCCM_steeringAngle "Measured ASAS sensor angle; raw 16383 = signal not available (SNA)";
CM_ SG_ 297 SCCM_steeringAngleValidity "Transitions to VALID when rotation of over 4 deg has occurred; raw 3 = signal not available (SNA)";
CM_ SG_ 297 SCCM_steeringAngleSpeed "Speed of steering angle rotation";
CM_ SG_ 297 SCCM_steeringAngleSensorReservd1 "Steering column control module: steering angle sensor reservd1";
CM_ SG_ 297 SCCM_steeringAngleSensorReservd2 "Steering column control module: steering angle sensor reservd2";
CM_ SG_ 297 SCCM_steeringAngleSensorReservd3 "Steering column control module: steering angle sensor reservd3";
CM_ BO_ 1597 "SDCR ECU message: info";
CM_ SG_ 1597 SDCR_infoIndex "SDCR ECU: info index";
CM_ SG_ 1597 SDCR_infoBuildType "SDCR ECU: info build type";
CM_ SG_ 1597 SDCR_infoBuildConfigId "SDCR ECU: info build config id";
CM_ SG_ 1597 SDCR_infoHardwareId "SDCR ECU: info hardware id";
CM_ SG_ 1597 SDCR_infoComponentId "SDCR ECU: info component id";
CM_ SG_ 1597 SDCR_infoPcbaId "SDCR ECU: info pcba id";
CM_ SG_ 1597 SDCR_infoAssemblyId "SDCR ECU: info assembly id";
CM_ SG_ 1597 SDCR_infoUsageId "SDCR ECU: info usage id";
CM_ SG_ 1597 SDCR_infoSubUsageId "SDCR ECU: info sub usage id";
CM_ SG_ 1597 SDCR_infoAppCrc "SDCR ECU: info app crc";
CM_ SG_ 1597 SDCR_infoBootGitHash "SDCR ECU: info boot git hash";
CM_ BO_ 523 "Air suspension controller message: axle data";
CM_ SG_ 523 TAS_axleIndex "Air suspension controller: axle index";
CM_ SG_ 523 TAS_rawHeightFL "Current height of the FL air spring.; raw 1023 = signal not available (SNA)";
CM_ SG_ 523 TAS_staticHeightEstimateFL "Current static height estimate of the FL air spring.; raw 1023 = signal not available (SNA)";
CM_ SG_ 523 TAS_componentPressureFL "Current static pressure of the FL air spring.; raw 255 = signal not available (SNA)";
CM_ SG_ 523 TAS_rawHeightFR "Current height of the FR air spring.; raw 1023 = signal not available (SNA)";
CM_ SG_ 523 TAS_staticHeightEstimateFR "Current static height estimate of the FR air spring.; raw 1023 = signal not available (SNA)";
CM_ SG_ 523 TAS_componentPressureFR "Current static pressure of the FR air spring.; raw 255 = signal not available (SNA)";
CM_ SG_ 523 TAS_rawHeightRL "Current height of the RL air spring.; raw 1023 = signal not available (SNA)";
CM_ SG_ 523 TAS_staticHeightEstimateRL "Current static height estimate of the RL air spring.; raw 1023 = signal not available (SNA)";
CM_ SG_ 523 TAS_componentPressureRL "Current static pressure of the RL air spring.; raw 255 = signal not available (SNA)";
CM_ SG_ 523 TAS_rawHeightRR "Current height of the RR air spring.; raw 1023 = signal not available (SNA)";
CM_ SG_ 523 TAS_staticHeightEstimateRR "Current static height estimate of the RR air spring.; raw 1023 = signal not available (SNA)";
CM_ SG_ 523 TAS_componentPressureRR "Current static pressure of the RR air spring.; raw 255 = signal not available (SNA)";
CM_ BO_ 1398 "Air suspension controller message: damping states";
CM_ SG_ 1398 TAS_endstopState "Air suspension controller: endstop state";
CM_ SG_ 1398 TAS_continuousControlState "SW-237496";
CM_ SG_ 1398 TAS_activeTireTune "Air suspension controller: active tire tune";
CM_ SG_ 1398 TAS_roughnessRaiseReason "Air suspension controller: roughness raise reason";
CM_ SG_ 1398 TAS_frontMetricDrivesRear "Air suspension controller: front metric drives rear";
CM_ SG_ 1398 TAS_roadCondition "Air suspension controller: road condition; raw 255 = signal not available (SNA)";
CM_ SG_ 1398 TAS_bellyProtect "Air suspension controller: belly protect";
CM_ SG_ 1398 TAS_frontMetricDrivesFront "Air suspension controller: front metric drives front";
CM_ SG_ 1398 TAS_speedBumpAxleFront "Air suspension controller: speed bump axle front";
CM_ SG_ 1398 TAS_speedBumpAxleRear "Air suspension controller: speed bump axle rear";
CM_ SG_ 1398 TAS_holeProtectFL "Air suspension controller: hole protect FL";
CM_ SG_ 1398 TAS_holeProtectFR "Air suspension controller: hole protect FR";
CM_ SG_ 1398 TAS_holeProtectRL "Air suspension controller: hole protect RL";
CM_ SG_ 1398 TAS_holeProtectRR "Air suspension controller: hole protect RR";
CM_ SG_ 1398 TAS_stepProtectFL "Air suspension controller: step protect FL";
CM_ SG_ 1398 TAS_stepProtectFR "Air suspension controller: step protect FR";
CM_ SG_ 1398 TAS_stepProtectRL "Air suspension controller: step protect RL";
CM_ SG_ 1398 TAS_stepProtectRR "Air suspension controller: step protect RR";
CM_ SG_ 1398 TAS_FDUTorqueCorruptionScale "Air suspension controller: FDU torque corruption scale; raw 15 = signal not available (SNA)";
CM_ SG_ 1398 TAS_sprungMassEstimate "Air suspension controller: sprung mass estimate; raw 31 = signal not available (SNA)";
CM_ SG_ 1398 TAS_anyDamperActive "Air suspension controller: any damper active";
CM_ SG_ 1398 TAS_dampingStatesCounter "Air suspension controller: damping states counter";
CM_ SG_ 1398 TAS_dampingStatesChecksum "Air suspension controller: damping states checksum";
CM_ BO_ 1357 "Air suspension controller message: info";
CM_ SG_ 1357 TAS_infoIndex "Air suspension controller: info index";
CM_ SG_ 1357 TAS_infoBuildType "Air suspension controller: info build type";
CM_ SG_ 1357 TAS_infoBuildConfigId "Air suspension controller: info build config id";
CM_ SG_ 1357 TAS_infoHardwareId "Air suspension controller: info hardware id";
CM_ SG_ 1357 TAS_infoComponentId "Air suspension controller: info component id";
CM_ SG_ 1357 TAS_infoPcbaId "Air suspension controller: info pcba id";
CM_ SG_ 1357 TAS_infoAssemblyId "Air suspension controller: info assembly id; raw 255 = signal not available (SNA)";
CM_ SG_ 1357 TAS_infoUsageId "Air suspension controller: info usage id";
CM_ SG_ 1357 TAS_infoSubUsageId "Air suspension controller: info sub usage id";
CM_ SG_ 1357 TAS_infoAppCrc "Air suspension controller: info app crc";
CM_ SG_ 1357 TAS_infoAppGitHash "Air suspension controller: info app git hash";
CM_ SG_ 1357 TAS_infoBootGitHash "Air suspension controller: info boot git hash";
CM_ SG_ 1357 TAS_infoPlatformType "Air suspension controller: info platform type";
CM_ SG_ 1357 TAS_infoMajorVersion "Air suspension controller: info major version; raw 255 = signal not available (SNA)";
CM_ SG_ 1357 TAS_infoBranchOrigin "Air suspension controller: info branch origin; raw 255 = signal not available (SNA)";
CM_ SG_ 1357 TAS_infoMaturity "Air suspension controller: info maturity; raw 255 = signal not available (SNA)";
CM_ SG_ 1357 TAS_infoHardwareRevision "Air suspension controller: info hardware revision; raw 255 = signal not available (SNA)";
CM_ BO_ 525 "Air suspension controller message: states";
CM_ SG_ 525 TAS_levelingState "Indicates air suspension leveling state.";
CM_ SG_ 525 TAS_levelingItem "Indicates the currently active air suspension components.";
CM_ SG_ 525 TAS_pressureGallery "Current air suspension valve block gallery pressure.; raw 255 = signal not available (SNA)";
CM_ SG_ 525 TAS_pressureReservoir "Indicates the latest valid reservoir pressure.; raw 255 = signal not available (SNA)";
CM_ SG_ 525 TAS_runMode "Indicates the status of run mode.";
CM_ SG_ 525 TAS_filterMode "Indicates the status of filter mode.";
CM_ SG_ 525 TAS_compressorRun "Either an indication that the compressor is running or a request to run the air compressor";
CM_ SG_ 525 TAS_twistDetected "TAS has detected large amount of twist.";
CM_ SG_ 525 TAS_leanDetected "TAS has detected vehicle to be leaning left or right.";
CM_ SG_ 525 TAS_limpHomeMode "Indicates which limp home mode is active.";
CM_ SG_ 525 TAS_targetLevel "Indicates target ride height.";
CM_ SG_ 525 TAS_currentLevel "Indicates current ride height.";
CM_ SG_ 525 TAS_jackMode "Indicates the status of Jack mode.";
CM_ SG_ 525 TAS_reduceVehicleSpeedRequest "Air suspension controller: reduce vehicle speed request";
CM_ SG_ 525 TAS_statesCounter "Air suspension controller: states counter";
CM_ SG_ 525 TAS_statesChecksum "Air suspension controller: states checksum";
CM_ BO_ 409 "Air suspension controller message: ui adaptive activity0";
CM_ SG_ 409 TAS_adaptiveActivityFL_C "Air suspension controller: adaptive activity FL c; raw 31 = signal not available (SNA)";
CM_ SG_ 409 TAS_adaptiveActivityFL_R "Air suspension controller: adaptive activity FL r; raw 31 = signal not available (SNA)";
CM_ SG_ 409 TAS_adaptiveActivityFR_C "Air suspension controller: adaptive activity FR c; raw 31 = signal not available (SNA)";
CM_ SG_ 409 TAS_adaptiveActivityFR_R "Air suspension controller: adaptive activity FR r; raw 31 = signal not available (SNA)";
CM_ SG_ 409 TAS_adaptiveActivityRL_C "Air suspension controller: adaptive activity RL c; raw 31 = signal not available (SNA)";
CM_ SG_ 409 TAS_adaptiveActivityRL_R "Air suspension controller: adaptive activity RL r; raw 31 = signal not available (SNA)";
CM_ SG_ 409 TAS_adaptiveActivityRR_C "Air suspension controller: adaptive activity RR c; raw 31 = signal not available (SNA)";
CM_ SG_ 409 TAS_adaptiveActivityRR_R "Air suspension controller: adaptive activity RR r; raw 31 = signal not available (SNA)";
CM_ SG_ 409 TAS_uiHeightFL "Air suspension controller: ui height FL; raw 63 = signal not available (SNA)";
CM_ SG_ 409 TAS_uiHeightFR "Air suspension controller: ui height FR; raw 63 = signal not available (SNA)";
CM_ SG_ 409 TAS_uiHeightRL "Air suspension controller: ui height RL; raw 63 = signal not available (SNA)";
CM_ SG_ 409 TAS_uiHeightRR "Air suspension controller: ui height RR; raw 63 = signal not available (SNA)";
CM_ BO_ 410 "Air suspension controller message: ui adaptive activity1";
CM_ SG_ 410 TAS_bodyAccelFL "Air suspension controller: body accel FL; raw 255 = signal not available (SNA)";
CM_ SG_ 410 TAS_bodyAccelFR "Air suspension controller: body accel FR; raw 255 = signal not available (SNA)";
CM_ SG_ 410 TAS_bodyAccelRL "Air suspension controller: body accel RL; raw 255 = signal not available (SNA)";
CM_ SG_ 410 TAS_bodyAccelRR "Air suspension controller: body accel RR; raw 255 = signal not available (SNA)";
CM_ BO_ 538 "Air suspension controller message: ui control";
CM_ SG_ 538 TAS_yellowWarningLamp "Air suspension controller: yellow warning lamp";
CM_ SG_ 538 TAS_redWarningLamp "Air suspension controller: red warning lamp";
CM_ SG_ 538 TAS_veryLowAllowed "Air suspension controller: very low allowed";
CM_ SG_ 538 TAS_lowAllowed "Air suspension controller: low allowed";
CM_ SG_ 538 TAS_standardAllowed "Air suspension controller: standard allowed";
CM_ SG_ 538 TAS_highAllowed "Air suspension controller: high allowed";
CM_ SG_ 538 TAS_veryHighAllowed "Air suspension controller: very high allowed";
CM_ SG_ 538 TAS_extractAllowed "Air suspension controller: extract allowed";
CM_ SG_ 538 TAS_showSpinner "Air suspension controller: show spinner";
CM_ SG_ 538 TAS_adaptiveRideModeOverride "Air suspension controller: adaptive ride mode override; raw 3 = signal not available (SNA)";
CM_ SG_ 538 TAS_levelSelectEnabled "Air suspension controller: level select enabled";
CM_ SG_ 538 TAS_jackModeToggleEnabled "Air suspension controller: jack mode toggle enabled";
CM_ SG_ 538 TAS_adaptiveRideSelectEnabled "Air suspension controller: adaptive ride select enabled";
CM_ SG_ 538 TAS_launchModeState "Air suspension controller: launch mode state";
CM_ SG_ 538 TAS_restrictUpLevelingFalcons "Air suspension controller: restrict up leveling falcons";
CM_ SG_ 538 TAS_restrictUpLevelingTrunk "Air suspension controller: restrict up leveling trunk";
CM_ SG_ 538 TAS_restrictDownLevelingDoors "Air suspension controller: restrict down leveling doors";
CM_ SG_ 538 TAS_restrictLevelingChargeCable "Air suspension controller: restrict leveling charge cable";
CM_ SG_ 538 TAS_restrictLevelingSystemCheck "Air suspension controller: restrict leveling system check";
CM_ SG_ 538 TAS_restrictLevelingTransport "Air suspension controller: restrict leveling transport";
CM_ SG_ 538 TAS_restrictLevelingShowroom "Indication that up and down leveling are restricted while showroom mode is active.";
CM_ SG_ 538 TAS_uiControlCounter "Air suspension controller: ui control counter";
CM_ SG_ 538 TAS_uiControlChecksum "Air suspension controller: ui control checksum";
CM_ BO_ 1657 "Touchscreen user interface computer message: ambient lighting ctrls; forwarded onto this bus by the gateway";
CM_ SG_ 1657 UI_rgbEnableState "Request to enable RGB lights";
CM_ SG_ 1657 UI_rgbEffectType "Reports the RGB light effect type.";
CM_ SG_ 1657 UI_rgbBrightnessLevel "Reports the requested RGB brightness level.; raw 127 = signal not available (SNA)";
CM_ SG_ 1657 UI_rgbTargetDOORFL "Target RGB control for front left door";
CM_ SG_ 1657 UI_rgbTargetDOORFR "Target RGB control for the front right door";
CM_ SG_ 1657 UI_rgbTargetDOORRL "Target RGB control for rear left door";
CM_ SG_ 1657 UI_rgbTargetDOORRR "Target RGB control for the rear right door";
CM_ SG_ 1657 UI_rgbTargetIPFL "Reports control for RGB lighting for the front left instrument panel.";
CM_ SG_ 1657 UI_rgbTargetIPFR "Reports control for RGB lighting for the front right instrument panel.";
CM_ BO_ 1021 "Touchscreen user interface computer message: autopilot control; forwarded onto this bus by the gateway";
CM_ SG_ 1021 UI_autopilotControlIndex "Touchscreen user interface computer: autopilot control index";
CM_ SG_ 1021 UI_hovEnabled "UI HOV routes enabled";
CM_ SG_ 1021 UI_smartSetSpeedOffset "TACC will apply this offset over the speed limit";
CM_ SG_ 1021 UI_smartSetSpeedOffsetType "Offset applied will be a percentage or fixed value based on this setting";
CM_ SG_ 1021 UI_fsdStopsControlEnabled "Indicates if autopilot control for traffic lights and stops signs has been enabled by the driver";
CM_ SG_ 1021 UI_smartSetSpeed "TACC will use speed limit + offset as user set speed when enabled";
CM_ SG_ 1021 UI_automaticSetSpeedOffset "Maximum set speed offset would be determined automatically when this option is enabled";
CM_ SG_ 1021 UI_enableFullSelfDriving "Indicates if the driver has enabled FSD behaviors";
CM_ SG_ 1021 UI_hasFullSelfDriving "Indicates if the vehicle hardware, software, and dependencies allow FSD";
CM_ SG_ 1021 UI_autosteerActivation "User-selected autosteer activation method";
CM_ SG_ 1021 UI_autopilotDrivingProfile "Driving profile for autopilot control";
CM_ SG_ 1021 UI_fsdBetaRequest "User accepted disclaimer and requested FSD (Supervised) builds";
CM_ SG_ 1021 UI_fullSelfDrivingSuspended "Full self driving is suspended";
CM_ SG_ 1021 UI_disableOptionalLaneChanges "Disable optional lane changes while FSD is controlling";
CM_ SG_ 1021 UI_selectableCameraRequest "Infotainment selectable camera state request from AP signal; raw 15 = signal not available (SNA)";
CM_ SG_ 1021 UI_driverMonitorConfirmation "Driver attentiveness confirmation";
CM_ SG_ 1021 UI_parkAssistUseVision "Reports if the vehicle should use vision park assist.";
CM_ SG_ 1021 UI_noStalkConfirmAlertHaptic "Detects if alert haptic feedback should trigger.";
CM_ SG_ 1021 UI_noStalkConfirmAlertChime "Detects if alert chime should trigger.";
CM_ SG_ 1021 UI_factorySummonEnable "Controls Factory Summon.";
CM_ SG_ 1021 UI_enableCabinCamera "Indicates if autopilot can enable cabin camera";
CM_ SG_ 1021 UI_enableAutopilotStopWarning "Enables the Autopilot active red light warning function.";
CM_ SG_ 1021 UI_enableVisionSpeedControl "Indicates if autopilot can enable vision speed control";
CM_ SG_ 1021 UI_enableTeslaAutopark "Indicates if autopilot can enable Telsa Autopark control";
CM_ SG_ 1021 UI_autoTurnSignalMode "Turn signal activation mode";
CM_ SG_ 1021 UI_enableCabinAudioRecording "Indicates if autopilot can record cabin audio";
CM_ BO_ 819 "Touchscreen user interface computer message: charge request; forwarded onto this bus by the gateway";
CM_ SG_ 819 UI_openChargePortDoorRequest "Request to open charge port.";
CM_ SG_ 819 UI_closeChargePortDoorRequest "Request to close charge port.";
CM_ SG_ 819 UI_chargeEnableRequest "Charging request initiated";
CM_ SG_ 819 UI_acChargeCurrentLimit "UI charging line current request; raw 127 = signal not available (SNA)";
CM_ SG_ 819 UI_dSocAlertEnable "Set when the BMS_a117_SW_Delta_SOC_Weak_Short alert for the BMS should have a functional response";
CM_ SG_ 819 UI_chargeTerminationPct "Charge Termination Limit Percent";
CM_ SG_ 819 UI_scheduledDepartureEnabled "Reports scheduled departure feature enablement.";
CM_ SG_ 819 UI_chargePortLatchRequest "Request to engage or disengage the latch.";
CM_ SG_ 819 UI_cpInletHeaterRequest "Enable charge port inlet heater";
CM_ BO_ 659 "Touchscreen user interface computer message: chassis control; forwarded onto this bus by the gateway";
CM_ SG_ 659 UI_steeringTuneRequest "UI customer level request for steering feel. MS had comfort, normal, sport. M3 intent is Normal, sport see SW-95934";
CM_ SG_ 659 UI_tractionControlMode "Transport user selected traction control modes";
CM_ SG_ 659 UI_parkBrakeRequest "User selection for Park brake; raw 3 = signal not available (SNA)";
CM_ SG_ 659 UI_winchModeRequest "Winch mode (towing) request";
CM_ SG_ 659 UI_trailerMode "Indicates whether trailer mode is selected. To be used when towing a trailer.";
CM_ SG_ 659 UI_accOvertakeEnable "Enable ACC Overtake assistance (reduce follow distance when the turn signal is on), UI firmware only sets datavalue to True; raw 3 = signal not available (SNA)";
CM_ SG_ 659 UI_aebEnable "Enable Autonomous Emergency Brakes; raw 3 = signal not available (SNA)";
CM_ SG_ 659 UI_aesEnable "Enable Automatic Emergency Steering (associated datavalue set to true and never changed by UI firmware); raw 3 = signal not available (SNA)";
CM_ SG_ 659 UI_ahlbEnable "Enable Automatic High/Low Beams; raw 3 = signal not available (SNA)";
CM_ SG_ 659 UI_autoLaneChangeEnable "Enable Automatic Lane Change; raw 3 = signal not available (SNA)";
CM_ SG_ 659 UI_winchProxUserOverride "User feedback from tow mode panel confirming that charge cable is disconnected when vehicle is unable to determine cable status";
CM_ SG_ 659 UI_autoParkRequest "Request Automatic Parking; raw 15 = signal not available (SNA)";
CM_ SG_ 659 UI_bsdEnable "Enable Blind Spot Detection (datavalue defaults to true and not changed by UI firmware); raw 3 = signal not available (SNA)";
CM_ SG_ 659 UI_fcwEnable "Enable Forward Collision Warning; raw 3 = signal not available (SNA)";
CM_ SG_ 659 UI_fcwSensitivity "Forward Collision Warning Level; raw 3 = signal not available (SNA)";
CM_ SG_ 659 UI_latControlEnable "Enable Lateral Control (lane centering, lane keeping, lane changing); raw 3 = signal not available (SNA)";
CM_ SG_ 659 UI_ldwEnable "Enable Lane Departure Warning; raw 3 = signal not available (SNA)";
CM_ BO_ 531 "Touchscreen user interface computer message: cruise control; forwarded onto this bus by the gateway";
CM_ SG_ 531 UI_cruiseSpeedCommand "User command to change the cruise set speed.";
CM_ BO_ 568 "Touchscreen user interface computer message: driver assist map data; forwarded onto this bus by the gateway";
CM_ SG_ 568 UI_roadClass "Autopilot map road class; raw 0 = signal not available (SNA)";
CM_ SG_ 568 UI_navRouteActive "Navigation route is active";
CM_ SG_ 568 UI_parallelAutoparkEnabled "Autopilot map parallel park enabled.";
CM_ SG_ 568 UI_perpendicularAutoparkEnabled "Autopilot map perpendicular park enabled.";
CM_ SG_ 568 UI_controlledAccess "DAS map controlled access segment.";
CM_ SG_ 568 UI_autosteerRestricted "Autopilot map is autostreer restricted.";
CM_ BO_ 645 "Touchscreen user interface computer message: driver profile recall; forwarded onto this bus by the gateway";
CM_ SG_ 645 UI_driverProfileRecallIndex "Touchscreen user interface computer: driver profile recall index; raw 0 = signal not available (SNA)";
CM_ SG_ 645 UI_driverProfileRecallStop "notifies controller to stop profile recall action";
CM_ SG_ 645 UI_frontSeatRecallActive "signals when driver seat presets are being recalled";
CM_ SG_ 645 UI_leftMirrorTiltXPosition "signal from ui to command mirror X tilt position";
CM_ SG_ 645 UI_leftMirrorTiltYPosition "signal from ui to command mirror Y tilt position";
CM_ SG_ 645 UI_customMirrorDipPositionsSet "Reports whether custom mirror dip positions are set.";
CM_ SG_ 645 UI_leftMirrorDipXPosition "signal from ui to command left mirror X dip position";
CM_ SG_ 645 UI_leftMirrorDipYPosition "signal from ui to command mirror Y dip position";
CM_ SG_ 645 UI_modifyMirrorDipRequest "Reports that a user is trying to modify the mirrors in the dipped position.";
CM_ BO_ 651 "Touchscreen user interface computer message: driver profile recall2; forwarded onto this bus by the gateway";
CM_ SG_ 651 UI_driverProfileIndex "Tracks manual driver profile selection. Shows the linked phonekey / key card / key fob or profile index if not linked";
CM_ SG_ 651 UI_driverProfileSelectionType "Tracks manual driver profile selection. Shows the linked phonekey / key card / key fob or profile index if not linked";
CM_ SG_ 651 UI_driverProfilePositionAdjusted "Tracks adjustments to driver profile. Sets when a profile position has been adjusted from what was saved";
CM_ SG_ 651 UI_activeKeyRequested "Tracks manual driver profile selection. Shows the linked phonekey / key card / key fob or profile index if not linked";
CM_ BO_ 1139 "Touchscreen user interface computer message: eth nm; forwarded onto this bus by the gateway";
CM_ SG_ 1139 UI_nmKeepAwakeReason "reason UI is being kept awake; raw 0 = signal not available (SNA)";
CM_ SG_ 1139 UI_wakeupTime "Unix epoch time at which vehicle should wake for scheduled charge or update.";
CM_ BO_ 883 "Touchscreen user interface computer message: gps vehicle speed; forwarded onto this bus by the gateway";
CM_ SG_ 883 UI_mapSpeedLimitUnits "Autopilot map speed limit units.";
CM_ SG_ 883 UI_mppSpeedLimit "Autopilot map speed limit";
CM_ SG_ 883 UI_gpsNmeaMIA "GPS NMEA data MIA";
CM_ SG_ 883 UI_gpsAntennaDisconnected "GPS antenna state";
CM_ SG_ 883 UI_conditionalLimitActive "Conditional speed limit condition is currently active";
CM_ SG_ 883 UI_conditionalSpeedLimit "Conditional speed limit value; raw 31 = signal not available (SNA)";
CM_ BO_ 755 "Touchscreen user interface computer message: hvac request; forwarded onto this bus by the gateway";
CM_ SG_ 755 UI_hvacReqTempSetpointLeft "HVAC left set temperature.";
CM_ SG_ 755 UI_hvacReqAutoBlowerLevel "Reports the auto Heating, Ventilation, and Air Conditioning (HVAC) speed aggressiveness setting.";
CM_ SG_ 755 UI_hvacReqTempSetpointRight "HVAC right set temperature.";
CM_ SG_ 755 UI_hvacReqAirDistributionMode "Request for air distribution mode.";
CM_ SG_ 755 UI_hvacReqBlowerSegment "HVAC manual blower request (GUI_hvacManualBlowerRequest)";
CM_ SG_ 755 UI_hvacReqRecirc "HVAC recirculation mode";
CM_ SG_ 755 UI_hvacReqACDisable "Request to disable AC.";
CM_ SG_ 755 UI_hvacDefogState "HVAC defog state.";
CM_ SG_ 755 UI_hvacReqUserPowerState "Reports HVAC power state.";
CM_ SG_ 755 UI_hvacReqSecondRowState "HVAC rear fan request speed.";
CM_ SG_ 755 UI_hvacReqKeepClimateOn "Request accessory power";
CM_ SG_ 755 UI_hvacReqBioWeaponDefMode "Request for BioWeapon Defense Mode";
CM_ SG_ 755 UI_hvacReqTempSetpointCOP "HVAC cabin overheat protection set temperature.";
CM_ BO_ 1523 "Touchscreen user interface computer message: odo; forwarded onto this bus by the gateway";
CM_ SG_ 1523 UI_odometer "Odometer; raw 16777215 = signal not available (SNA)";
CM_ BO_ 948 "Touchscreen user interface computer message: peripheral power requests; forwarded onto this bus by the gateway";
CM_ SG_ 948 UI_usbFrontHubPowerStateRequest "Reports the Universal Serial Bus (USB) Hub power request.; raw 0 = signal not available (SNA)";
CM_ BO_ 827 "Touchscreen user interface computer message: power estimates; forwarded onto this bus by the gateway";
CM_ SG_ 827 UI_idlePowerConsumption "Power consumption when idle";
CM_ SG_ 827 UI_chargeTimeUntilTerminationPct "Charge time minutes until reached uSoe target; raw 2047 = signal not available (SNA)";
CM_ SG_ 827 UI_chargeTimeUntilReadyToDepart "Charge time minutes until enough energy to depart for rest of trip; raw 2047 = signal not available (SNA)";
CM_ BO_ 820 "Touchscreen user interface computer message: powertrain control; forwarded onto this bus by the gateway";
CM_ SG_ 820 UI_pedalMap "Switch between various platform specific pedal maps";
CM_ SG_ 820 UI_enableRegenBackfill "Indicates if regenerative braking backfill has been enabled by the driver";
CM_ SG_ 820 UI_regenTorqueMax "Maximum regen torque from UI - reports different value when in track mode";
CM_ SG_ 820 UI_limitMode "Commands limited drive inverter capabilities based on special vehicle modes";
CM_ SG_ 820 UI_motorOnMode "Request from the UI to selectively enable or disable a drive unit (dev-only)";
CM_ SG_ 820 UI_stoppingMode "Low-speed behavior when no pedal is pressed (stopping/rolling/creeping)";
CM_ SG_ 820 UI_speedLimit "Maximum allowed speed enforced at vehicle level.; raw 511 = signal not available (SNA)";
CM_ SG_ 820 UI_enableSmartShift "Stalkless convenience feature that allows unparking with only a firm press of brake pedal";
CM_ SG_ 820 UI_navVehParallelToRdCanContinue "Whether the vehicle is parallel parked on a public road; raw 0 = signal not available (SNA)";
CM_ BO_ 826 "Touchscreen user interface computer message: range; forwarded onto this bus by the gateway";
CM_ SG_ 826 UI_ratedRange "Rated range in miles";
CM_ SG_ 826 UI_soe "State of energy";
CM_ SG_ 826 UI_uSoe "Usable state of energy";
CM_ BO_ 723 "Touchscreen user interface computer message: solar data; forwarded onto this bus by the gateway";
CM_ SG_ 723 UI_isSunUp "is sun up; raw 3 = signal not available (SNA)";
CM_ SG_ 723 UI_solarElevationAngle "Solar Elevation Angle; raw 127 = signal not available (SNA)";
CM_ SG_ 723 UI_screenPCBTemperature "Temperature of display PCB";
CM_ SG_ 723 UI_minsToSunset "time until to sunset";
CM_ SG_ 723 UI_minsToSunrise "time until to sunrise";
CM_ BO_ 851 "Touchscreen user interface computer message: status; forwarded onto this bus by the gateway";
CM_ SG_ 851 UI_touchActive "No touchscreen errors";
CM_ SG_ 851 UI_audioActive "Audio system is ready.";
CM_ SG_ 851 UI_cellActive "Cell is powered";
CM_ SG_ 851 UI_displayReady "UI is ready (GUI_allReady) and display is ok (GUI_displayHardwareOK)";
CM_ SG_ 851 UI_displayOn "UI display on/off status";
CM_ SG_ 851 UI_wifiActive "WiFi active.";
CM_ SG_ 851 UI_wifiConnected "WiFi Connected.";
CM_ SG_ 851 UI_readyForDrive "Ready for drive (UI ready or self park request)";
CM_ SG_ 851 UI_cellConnected "Detects if the cell is connected to a network.";
CM_ SG_ 851 UI_vpnActive "VPN connected.";
CM_ SG_ 851 UI_factoryReset "UI request for factory reset; raw 0 = signal not available (SNA)";
CM_ SG_ 851 UI_gpsActive "GPS has valid fix";
CM_ SG_ 851 UI_cellNetworkTechnology "Describes the type of cellular network to which the car computer is connected: GPRS_2G(114Kbps) < EGDE_2G(368Kbps) < 3G(3Mbps) < HSDPA_3G(14Mbps) < HSPAplus_4Gg(168Mbps) < 4G_LTE(299Mbps); raw 15 = signal not available (SNA)";
CM_ SG_ 851 UI_falseTouchCounter "Count false touches after display is off.";
CM_ SG_ 851 UI_cellSignalBars "Number of cellular signal bars displayed on the UI, derived from cellSignalStrength; raw 7 = signal not available (SNA)";
CM_ SG_ 851 UI_trailerModeTelltale "Color of the trailer mode telltale";
CM_ SG_ 851 UI_pcbTemperature "PCB digital temp sensor reading in DegC";
CM_ SG_ 851 UI_cpuTemperature "Apollo Lake SOC temperature in DegC";
CM_ BO_ 991 "Touchscreen user interface computer message: status2; forwarded onto this bus by the gateway";
CM_ SG_ 991 UI_userActivity "Indicates user interaction with the center display";
CM_ SG_ 991 UI_activeTouchPoints "Quantity of active touch points on the Center Display";
CM_ SG_ 991 UI_linkState "Connectivity link state";
CM_ SG_ 991 UI_autopilotSentryRequest "whether AP sentry mode should be enabled";
CM_ SG_ 991 UI_mobileAppConnected "Reports if Web Real-Time Communication (WebRTC) connection is connected while summon screen is open on the mobile app.";
CM_ SG_ 991 UI_autoshiftDRState "Reports the User Interface (UI) autoshift Drive/Reverse state.";
CM_ SG_ 991 UI_wifiBtModuleType "Reports the type of Wi-Fi and Bluetooth (BT) module.";
CM_ SG_ 991 UI_selfParkState "Reports the auto park state changes.; raw 255 = signal not available (SNA)";
CM_ SG_ 991 UI_summonDeviceIndex "Reports which device is being used to control summon.";
CM_ BO_ 663 "Touchscreen user interface computer message: suspension control; forwarded onto this bus by the gateway";
CM_ SG_ 663 UI_adaptiveRideRequest "UI customer adaptive ride request for air suspension.";
CM_ SG_ 663 UI_geofenceLevelingRequest "Geofence level request from customer; raw 5 = signal not available (SNA)";
CM_ BO_ 787 "Touchscreen user interface computer message: track mode settings; forwarded onto this bus by the gateway";
CM_ SG_ 787 UI_trackModeRequest "User selected track mode";
CM_ SG_ 787 UI_trackDrivePowerAvailability "Reports power deployment strategy for Track Mode. Ranges from endurance limit to maximum power.";
CM_ BO_ 839 "Touchscreen user interface computer message: trip planning; forwarded onto this bus by the gateway";
CM_ SG_ 839 UI_tripPlanningActive "Indicates that there is active route in navigation with a valid energy at destination prediction.";
CM_ SG_ 839 UI_navToSupercharger "Navigation destination is a supercharger";
CM_ SG_ 839 UI_navFastchargerType "when navigation is turned on, this enum identifies the type of fastcharger the car is navigating to based on the rated power from sc_locations";
CM_ SG_ 839 UI_battPreconditionOnNavState "Indicates to battery and thermal systems whether the battery should be actively heated, passively heated, actively cooled, or passively cooled";
CM_ SG_ 839 UI_requestActiveBatteryHeating "Flag to request BMS enable active battery heating";
CM_ SG_ 839 UI_battPreconditionOnNavPowerReq "The preconditioning power that Trip Planner is requesting from the thermal system to use for battery preconditioning (cooling or heating).; raw 127 = signal not available (SNA)";
CM_ SG_ 839 UI_battPreconditionOnNavTargetT "The pack temperature that Trip Planner is targeting upon arriving to a fast charger.; raw 255 = signal not available (SNA)";
CM_ SG_ 839 UI_energyAtDestination "expected energy at destination in kWh for current navigation route; raw 32768 = signal not available (SNA)";
CM_ BO_ 627 "Touchscreen user interface computer message: vehicle control; forwarded onto this bus by the gateway";
CM_ SG_ 627 UI_powerStateRequest "Request accessory power";
CM_ SG_ 627 UI_childDoorLockOnRight "UI child door lock request status.";
CM_ SG_ 627 UI_frontFogSwitch "Request for front fog lights to be on";
CM_ SG_ 627 UI_summonActive "Summon is active";
CM_ SG_ 627 UI_frunkRequest "Request open frunk";
CM_ SG_ 627 UI_wiperMode "Wiper mode state; raw 0 = signal not available (SNA)";
CM_ SG_ 627 UI_steeringButtonMode "Steering wheel control mode";
CM_ SG_ 627 UI_walkUpUnlock "Walk up unlock request (datavalue defaults to false)";
CM_ SG_ 627 UI_walkAwayLock "Walk away door lock setting.";
CM_ SG_ 627 UI_unlockOnPark "Unlock on park setting";
CM_ SG_ 627 UI_globalUnlockOn "Global Unlock Setting";
CM_ SG_ 627 UI_childDoorLockOnLeft "UI child door lock request status.";
CM_ SG_ 627 UI_lockRequest "Lock or unlock request; raw 7 = signal not available (SNA)";
CM_ SG_ 627 UI_alarmEnabled "UI customer level request to enable alarm.";
CM_ SG_ 627 UI_stop12vSupport "UI request to stop rails as 12v support";
CM_ SG_ 627 UI_rearFogSwitch "Request for rear fog lights to be on";
CM_ SG_ 627 UI_mirrorFoldRequest "Fold the mirrors; raw 3 = signal not available (SNA)";
CM_ SG_ 627 UI_mirrorHeatRequest "Customer usage of mirror heater and rear defrost";
CM_ SG_ 627 UI_remoteStartRequest "remote start or self park request; raw 4 = signal not available (SNA)";
CM_ SG_ 627 UI_seeYouHomeLightingOn "Headlights after exit";
CM_ SG_ 627 UI_powerOff "power off rails request.";
CM_ SG_ 627 UI_displayBrightnessLevel "UI brightness; raw 255 = signal not available (SNA)";
CM_ SG_ 627 UI_autoHighBeamEnabled "Enable Automatic High/Low Beams";
CM_ SG_ 627 UI_frontLeftSeatHeatReq "Request for front left seat heat";
CM_ SG_ 627 UI_frontRightSeatHeatReq "Request for front left seat heat";
CM_ SG_ 627 UI_rearLeftSeatHeatReq "UI request for second row left seat heater";
CM_ SG_ 627 UI_rearCenterSeatHeatReq "UI request for second row middle seat heater";
CM_ SG_ 627 UI_rearRightSeatHeatReq "UI request for second row right seat heater";
CM_ SG_ 627 UI_autoFoldMirrorsOn "Enable Automatic Mirror Fold/Unfold";
CM_ SG_ 627 UI_mirrorDipOnReverse "Enable Mirror Dip On Reverse";
CM_ SG_ 627 UI_remoteClosureRequest "remote actuate trunk; raw 3 = signal not available (SNA)";
CM_ SG_ 627 UI_wiperRequest "Wiper speed; raw 0 = signal not available (SNA)";
CM_ SG_ 627 UI_domeLightSwitch "Dome light switch";
CM_ BO_ 947 "Touchscreen user interface computer message: vehicle control2; forwarded onto this bus by the gateway";
CM_ SG_ 947 UI_gloveboxRequest "UI request to open the glovebox";
CM_ SG_ 947 UI_trunkRequest "Rear trunk request";
CM_ SG_ 947 UI_PINToDriveEnabled "UI customer level request to pin to drive enabled.";
CM_ SG_ 947 UI_PINToDrivePassed "UI customer level request to enable drive with pin passed.";
CM_ SG_ 947 UI_disableMirrorAutoDim "Request to disable side and rear-view mirror auto dim";
CM_ SG_ 947 UI_lightSwitch "Headlight mode; raw 4 = signal not available (SNA)";
CM_ SG_ 947 UI_readyToAddKey "Ready to add key";
CM_ SG_ 947 UI_alarmTriggerRequest "Alarm activation request from UI";
CM_ SG_ 947 UI_displayOnForUser "User is present";
CM_ SG_ 947 UI_BLEPushNotificationRequest "Reports that the User Interface (UI) wants to talk to a phone and Vehicle Controller Security (VCSEC) should let all connected phones know.";
CM_ SG_ 947 UI_keepAutopilotAwake "Reports the request for Vehicle Controller (VC) to keep autopilot awake.";
CM_ SG_ 947 UI_batteryPreconditioningRequest "Requests battery preconditioning.";
CM_ SG_ 947 UI_autopilotPowerStateRequest "Requests different power states from autopilot ECU depending on feature usage.";
CM_ SG_ 947 UI_autoRollWindowsOnLockEnable "UI customer level request to enable auto-roll windows on lock";
CM_ SG_ 947 UI_steeringWheelHeatReq "Request to enable steering wheel heater";
CM_ SG_ 947 UI_disableHorn "Request to disable horn";
CM_ SG_ 947 UI_frontLeftSeatFanReq "Request for front left seat ventilation";
CM_ SG_ 947 UI_frontRightSeatAutoClimateReq "UI setting to enable auto seat heating and cooling for front right seat";
CM_ SG_ 947 UI_frontRightSeatFanReq "Request for front left seat ventilation";
CM_ SG_ 947 UI_frontLeftSeatAutoClimateReq "UI setting to enable auto seat heating and cooling for front left seat";
CM_ SG_ 947 UI_wiperHeaterReq "UI request to enable the wiper heater";
CM_ SG_ 947 UI_silentAlarm "Signal indicating alarms should be silenced";
CM_ BO_ 660 "Touchscreen user interface computer message: vehicle control3; forwarded onto this bus by the gateway";
CM_ SG_ 660 UI_lightFlashRequest "UI flash lights request";
CM_ SG_ 660 UI_phoneCallActive "On phone call via Bluetooth if active";
CM_ SG_ 660 UI_lightShowClosuresEnabled "Closure movements enabled during light show";
CM_ SG_ 660 UI_steeringWheelHeatAutoReq "UI setting to request auto steering wheel heat";
CM_ SG_ 660 UI_steeringWheelHeatLevelReq "Request for steering wheel heat";
CM_ SG_ 660 UI_headlightPulseRequest "Request headlights to pulse";
CM_ SG_ 660 UI_displayRedShiftActive "UI's reduce blue light setting is active";
CM_ SG_ 660 UI_fasciaCameraWashRequest "User request to activate fascia camera wash";
CM_ SG_ 660 UI_leftRearSeatAdjustmentRequest "Reports request from UI to actuate the left rear seat";
CM_ SG_ 660 UI_rightRearSeatAdjustmentReques "Reports request from UI to actuate the right rear seat";
CM_ SG_ 660 UI_blindSpotIndicatorLightReques "Request for blind spot indicator light";
CM_ SG_ 660 UI_keepOnAccessoryPortsReq "User setting to keep 12V outlets, USB ports, and phone chargers powered in CONDITIONING";
CM_ SG_ 660 UI_fasciaCameraShown "Whether the UI is currently showing the fascia camera view";
CM_ SG_ 660 UI_rearSeatChildLock "Reports the state of second row seat fold flat child lock from the UI";
CM_ SG_ 660 UI_windowPercentageRequest "Reports the window percentage value when window request is WINDOW_REQUEST_GOTO_PERCENT.";
CM_ SG_ 660 UI_windowRequestedFL "Reports that the front left window is requested.";
CM_ SG_ 660 UI_windowRequestedFR "Reports that the front right window is requested.";
CM_ SG_ 660 UI_windowRequestedRL "Reports that the rear left window is requested.";
CM_ SG_ 660 UI_windowRequestedRR "Reports that the rear right window is requested.";
CM_ SG_ 660 UI_windowRequest "Window operation request from the mobile app.";
CM_ SG_ 660 UI_closeTrunkRequest "Explicity request for the rear trunk to close";
CM_ SG_ 660 UI_childPresenceDetectionDisable "User request to disable child presence detection behaviors until the next drive cycle";
CM_ SG_ 660 UI_derivedLoadshedFeature "Reports whether vehicle controllers should enable derived loadshed feature.";
CM_ SG_ 660 UI_selfParkStandingBy "Reports that summon is in standby.";
CM_ BO_ 853 "Touchscreen user interface computer message: vehicle control thermal; forwarded onto this bus by the gateway";
CM_ SG_ 853 UI_coolantFlowRequest "request for coolant flow to MCU in LPM";
CM_ SG_ 853 UI_inletActiveCoolTarget "request for coolant temperature at Car Computer inlet";
CM_ SG_ 853 UI_disableHVPTThermalLoads "Request thermal system to disable active battery heating";
CM_ BO_ 644 "Touchscreen user interface computer message: vehicle modes; forwarded onto this bus by the gateway";
CM_ SG_ 644 UI_transportMode "Reports UI Transport mode. Distinct from GTW transport mode.";
CM_ SG_ 644 UI_showroomMode "Reports UI showroom mode.";
CM_ SG_ 644 UI_serviceMode "Service diagnostics mode active";
CM_ SG_ 644 UI_carWashMode "Car Wash Mode";
CM_ SG_ 644 UI_gameMode "Game mode";
CM_ SG_ 644 UI_serviceModePlus "Extended service diagnostics mode active";
CM_ SG_ 644 UI_premiumAmpPowerOff "Premium amplifier power off request";
CM_ SG_ 644 UI_lightShowType "Type of the light show to be run";
CM_ BO_ 595 "Touchscreen user interface computer message: vent panel control request; forwarded onto this bus by the gateway";
CM_ SG_ 595 UI_ventPanelControlRequestIndex "Touchscreen user interface computer: vent panel control request index";
CM_ SG_ 595 UI_ventPanelLeftPositionX "Airwave left X position.";
CM_ SG_ 595 UI_ventPanelLeftPositionY "Airwave left Y position.";
CM_ SG_ 595 UI_ventPanelLeftLateralSplit "Airwave left split amount.";
CM_ SG_ 595 UI_ventPanelRightPositionX "Airwave right X position.";
CM_ SG_ 595 UI_ventPanelRightPositionY "Airwave right Y position.";
CM_ SG_ 595 UI_ventPanelRightLateralSplit "Airwave right split amount.";
CM_ SG_ 595 UI_ventPanelLeftLateralMode "Airwave left focus or split.";
CM_ SG_ 595 UI_ventPanelRightLateralMode "Airwave right focus or split.";
CM_ SG_ 595 UI_hvacReqActiveVents "Active airwave sides - left/right/both";
CM_ SG_ 595 UI_vent2RLeftPositionX "Airwave left X position.";
CM_ SG_ 595 UI_vent2RLeftPositionY "Airwave left Y position.";
CM_ SG_ 595 UI_vent2RRightPositionX "Airwave left X position.";
CM_ SG_ 595 UI_vent2RRightPositionY "Airwave left Y position.";
CM_ BO_ 1285 "UMC ECU message: smart adapter info";
CM_ SG_ 1285 SA_infoIndex "UMC ECU: info index";
CM_ SG_ 1285 SA_genealogyVersion "UMC ECU: genealogy version";
CM_ SG_ 1285 SA_genealogyCrc "UMC ECU: genealogy crc";
CM_ SG_ 1285 SA_region "Reports the smart adapter region from Electrically Erasable Programmable Read-Only Memory (EEPROM).";
CM_ SG_ 1285 SA_OverTempThreshold "Reports the smart adapter overtemperature threshold from Electrically Erasable Programmable Read-Only Memory (EEPROM).";
CM_ SG_ 1285 SA_partNumInt "Reports the smart adapter part number integer representation.";
CM_ SG_ 1285 SA_partNumRev "Reports the smart adapter part number revision.";
CM_ SG_ 1285 SA_currentLimit "Reports the smart adapter current limit from Electrically Erasable Programmable Read-Only Memory (EEPROM).";
CM_ SG_ 1285 SA_l1Voltage "Reports the smart adapter nominal voltage request from Electrically Erasable Programmable Read-Only Memory (EEPROM).";
BA_DEF_ BO_ "GenMsgCycleTime" INT 0 3600000;
BA_DEF_ BO_ "GenMsgSendType" ENUM "Cyclic","NotUsed","NotUsed","NotUsed","NotUsed","NotUsed","NotUsed","IfActive","NoMsgSendType","NotUsed";
BA_DEF_ BO_ "VFrameFormat" ENUM "StandardCAN","ExtendedCAN","reserved","J1939PG","reserved","reserved","reserved","reserved","reserved","reserved","reserved","reserved","reserved","reserved","StandardCAN_FD","ExtendedCAN_FD";
BA_DEF_ BO_ "CANFD_BRS" ENUM "0","1";
BA_DEF_ SG_ "GenSigSNA" STRING;
BA_DEF_ SG_ "SystemSignalLongSymbol" STRING;
BA_DEF_ SG_ "Confidence" ENUM "validated","plausible","layout-only","contradicted";
BA_DEF_DEF_ "GenMsgCycleTime" 0;
BA_DEF_DEF_ "GenMsgSendType" "NoMsgSendType";
BA_DEF_DEF_ "VFrameFormat" "StandardCAN";
BA_DEF_DEF_ "CANFD_BRS" "1";
BA_DEF_DEF_ "GenSigSNA" "";
BA_DEF_DEF_ "SystemSignalLongSymbol" "";
BA_DEF_DEF_ "Confidence" "layout-only";
BA_ "GenMsgCycleTime" BO_ 516 100;
BA_ "GenMsgSendType" BO_ 516 0;
BA_ "GenMsgCycleTime" BO_ 692 100;
BA_ "GenMsgSendType" BO_ 692 0;
BA_ "GenMsgCycleTime" BO_ 548 100;
BA_ "GenMsgSendType" BO_ 548 0;
BA_ "GenMsgCycleTime" BO_ 964 1000;
BA_ "GenMsgSendType" BO_ 964 0;
BA_ "GenMsgCycleTime" BO_ 708 1000;
BA_ "GenMsgSendType" BO_ 708 0;
BA_ "GenMsgCycleTime" BO_ 676 1000;
BA_ "GenMsgSendType" BO_ 676 0;
BA_ "GenMsgCycleTime" BO_ 790 1000;
BA_ "GenMsgSendType" BO_ 790 0;
BA_ "GenMsgCycleTime" BO_ 1748 1000;
BA_ "GenMsgSendType" BO_ 1748 0;
BA_ "GenMsgCycleTime" BO_ 1551 1000;
BA_ "GenMsgSendType" BO_ 1551 0;
BA_ "GenMsgCycleTime" BO_ 837 1000;
BA_ "GenMsgSendType" BO_ 837 0;
BA_ "GenMsgCycleTime" BO_ 647 100;
BA_ "GenMsgSendType" BO_ 647 0;
BA_ "GenMsgCycleTime" BO_ 816 1000;
BA_ "GenMsgSendType" BO_ 816 0;
BA_ "GenMsgCycleTime" BO_ 585 50;
BA_ "GenMsgSendType" BO_ 585 0;
BA_ "GenMsgCycleTime" BO_ 553 100;
BA_ "GenMsgSendType" BO_ 553 0;
BA_ "GenMsgCycleTime" BO_ 297 10;
BA_ "GenMsgSendType" BO_ 297 0;
BA_ "GenMsgCycleTime" BO_ 1597 1000;
BA_ "GenMsgSendType" BO_ 1597 0;
BA_ "GenMsgCycleTime" BO_ 523 20;
BA_ "GenMsgSendType" BO_ 523 0;
BA_ "GenMsgCycleTime" BO_ 1398 100;
BA_ "GenMsgSendType" BO_ 1398 0;
BA_ "GenMsgCycleTime" BO_ 1357 1000;
BA_ "GenMsgSendType" BO_ 1357 0;
BA_ "GenMsgCycleTime" BO_ 525 100;
BA_ "GenMsgSendType" BO_ 525 0;
BA_ "GenMsgCycleTime" BO_ 409 50;
BA_ "GenMsgSendType" BO_ 409 0;
BA_ "GenMsgCycleTime" BO_ 410 50;
BA_ "GenMsgSendType" BO_ 410 0;
BA_ "GenMsgCycleTime" BO_ 538 100;
BA_ "GenMsgSendType" BO_ 538 0;
BA_ "GenMsgCycleTime" BO_ 1657 500;
BA_ "GenMsgSendType" BO_ 1657 0;
BA_ "GenMsgCycleTime" BO_ 1021 500;
BA_ "GenMsgSendType" BO_ 1021 0;
BA_ "GenMsgCycleTime" BO_ 819 500;
BA_ "GenMsgSendType" BO_ 819 0;
BA_ "GenMsgCycleTime" BO_ 659 500;
BA_ "GenMsgSendType" BO_ 659 0;
BA_ "GenMsgCycleTime" BO_ 531 500;
BA_ "GenMsgSendType" BO_ 531 0;
BA_ "GenMsgCycleTime" BO_ 568 500;
BA_ "GenMsgSendType" BO_ 568 0;
BA_ "GenMsgCycleTime" BO_ 645 500;
BA_ "GenMsgSendType" BO_ 645 0;
BA_ "GenMsgCycleTime" BO_ 651 500;
BA_ "GenMsgSendType" BO_ 651 0;
BA_ "GenMsgCycleTime" BO_ 1139 500;
BA_ "GenMsgSendType" BO_ 1139 0;
BA_ "GenMsgCycleTime" BO_ 883 1000;
BA_ "GenMsgSendType" BO_ 883 0;
BA_ "GenMsgCycleTime" BO_ 755 500;
BA_ "GenMsgSendType" BO_ 755 0;
BA_ "GenMsgCycleTime" BO_ 1523 1000;
BA_ "GenMsgSendType" BO_ 1523 0;
BA_ "GenMsgCycleTime" BO_ 948 500;
BA_ "GenMsgSendType" BO_ 948 0;
BA_ "GenMsgCycleTime" BO_ 827 1000;
BA_ "GenMsgSendType" BO_ 827 0;
BA_ "GenMsgCycleTime" BO_ 820 500;
BA_ "GenMsgSendType" BO_ 820 0;
BA_ "GenMsgCycleTime" BO_ 826 1000;
BA_ "GenMsgSendType" BO_ 826 0;
BA_ "GenMsgCycleTime" BO_ 723 1000;
BA_ "GenMsgSendType" BO_ 723 0;
BA_ "GenMsgCycleTime" BO_ 851 1000;
BA_ "GenMsgSendType" BO_ 851 0;
BA_ "GenMsgCycleTime" BO_ 991 500;
BA_ "GenMsgSendType" BO_ 991 0;
BA_ "GenMsgCycleTime" BO_ 663 500;
BA_ "GenMsgSendType" BO_ 663 0;
BA_ "GenMsgCycleTime" BO_ 787 500;
BA_ "GenMsgSendType" BO_ 787 0;
BA_ "GenMsgCycleTime" BO_ 839 1000;
BA_ "GenMsgSendType" BO_ 839 0;
BA_ "GenMsgCycleTime" BO_ 627 500;
BA_ "GenMsgSendType" BO_ 627 0;
BA_ "GenMsgCycleTime" BO_ 947 500;
BA_ "GenMsgSendType" BO_ 947 0;
BA_ "GenMsgCycleTime" BO_ 660 500;
BA_ "GenMsgSendType" BO_ 660 0;
BA_ "GenMsgCycleTime" BO_ 853 1000;
BA_ "GenMsgSendType" BO_ 853 0;
BA_ "GenMsgCycleTime" BO_ 644 500;
BA_ "GenMsgSendType" BO_ 644 0;
BA_ "GenMsgCycleTime" BO_ 595 500;
BA_ "GenMsgSendType" BO_ 595 0;
BA_ "GenMsgCycleTime" BO_ 1285 100;
BA_ "GenMsgSendType" BO_ 1285 0;
BA_ "Confidence" SG_ 516 PCS_chgMainState 0;
BA_ "Confidence" SG_ 516 PCS_gridConfig 0;
BA_ "GenSigSNA" SG_ 516 PCS_gridConfig "0";
BA_ "Confidence" SG_ 516 PCS_chgPHAEnable 0;
BA_ "Confidence" SG_ 516 PCS_chgPHBEnable 0;
BA_ "Confidence" SG_ 516 PCS_hvInletConductorEnergizedAc 0;
BA_ "Confidence" SG_ 516 PCS_chgHighPowerActive 0;
BA_ "Confidence" SG_ 516 PCS_chgPHCEnable 0;
BA_ "Confidence" SG_ 516 PCS_chgInstantAcPowerAvailable 0;
BA_ "Confidence" SG_ 516 PCS_chgMaxAcPowerAvailable 0;
BA_ "GenSigSNA" SG_ 516 PCS_chgMaxAcPowerAvailable "255";
BA_ "Confidence" SG_ 516 PCS_chgPHALineCurrentRequest 0;
BA_ "Confidence" SG_ 516 PCS_chgPHBLineCurrentRequest 0;
BA_ "Confidence" SG_ 516 PCS_chgPHCLineCurrentRequest 0;
BA_ "Confidence" SG_ 516 PCS_chgPwmEnableLine 0;
BA_ "Confidence" SG_ 516 PCS_hwVariantType 0;
BA_ "GenSigSNA" SG_ 516 PCS_hwVariantType "3";
BA_ "Confidence" SG_ 692 PCS_dcdcLvBusVolt 0;
BA_ "Confidence" SG_ 692 PCS_dcdcHvBusVolt 0;
BA_ "Confidence" SG_ 692 PCS_dcdcLvOutputCurrent 0;
BA_ "Confidence" SG_ 548 PCS_dcdcPrechargeStatus 0;
BA_ "Confidence" SG_ 548 PCS_dcdcLvSupportStatus 0;
BA_ "Confidence" SG_ 548 PCS_dcdcHvBusDischargeStatus 0;
BA_ "Confidence" SG_ 548 PCS_coldSleepAllowed 0;
BA_ "Confidence" SG_ 548 PCS_dcdcPchgHVBusLowRDetected 0;
BA_ "Confidence" SG_ 548 PCS_dcdcSubState 0;
BA_ "Confidence" SG_ 548 PCS_dcdcFaulted 0;
BA_ "Confidence" SG_ 548 PCS_okToBePowerCycled 0;
BA_ "Confidence" SG_ 548 PCS_dcdcOutputIsLimited 0;
BA_ "Confidence" SG_ 548 PCS_dcdcMaxOutputCurrentAllowed 0;
BA_ "Confidence" SG_ 548 PCS_dcdcPrechargeRtyCnt 0;
BA_ "Confidence" SG_ 548 PCS_dcdcLvSupportRtyCnt 0;
BA_ "Confidence" SG_ 548 PCS_dcdcDischargeRtyCnt 0;
BA_ "Confidence" SG_ 548 PCS_dcdcPwmEnableLine 0;
BA_ "Confidence" SG_ 548 PCS_dcdcSupportingFixedLvTarget 0;
BA_ "Confidence" SG_ 548 PCS_ecuLogUploadRequest 0;
BA_ "Confidence" SG_ 548 PCS_dcdcPrechargeRestartCnt 0;
BA_ "Confidence" SG_ 548 PCS_dcdcInitialPrechargeSubState 0;
BA_ "Confidence" SG_ 964 PCS_infoIndex 1;
BA_ "Confidence" SG_ 964 PCS_buildType 0;
BA_ "Confidence" SG_ 964 PCS_buildConfigId 0;
BA_ "Confidence" SG_ 964 PCS_hardwareId 0;
BA_ "Confidence" SG_ 964 PCS_componentId 0;
BA_ "Confidence" SG_ 964 PCS_pcbaId 0;
BA_ "Confidence" SG_ 964 PCS_assemblyId 0;
BA_ "Confidence" SG_ 964 PCS_usageId 0;
BA_ "Confidence" SG_ 964 PCS_subUsageId 0;
BA_ "Confidence" SG_ 964 PCS_platformType 0;
BA_ "Confidence" SG_ 964 PCS_appCrc 0;
BA_ "Confidence" SG_ 964 PCS_cpu2AppCrc 0;
BA_ "Confidence" SG_ 964 PCS_appGitHash 0;
BA_ "Confidence" SG_ 964 PCS_bootGitHash 0;
BA_ "Confidence" SG_ 964 PCS_bootUdsProtoVersion 0;
BA_ "Confidence" SG_ 964 PCS_bootCrc 0;
BA_ "Confidence" SG_ 708 PCS_logMessageSelect 1;
BA_ "Confidence" SG_ 708 PCS_chgPhAInputIrms 0;
BA_ "Confidence" SG_ 708 PCS_chgPhAIntBusV 0;
BA_ "Confidence" SG_ 708 PCS_chgPhAIntBusVTarget 0;
BA_ "Confidence" SG_ 708 PCS_chgPhAOutputI 0;
BA_ "Confidence" SG_ 708 PCS_chgPhAInputCurrentLimitReaso 0;
BA_ "SystemSignalLongSymbol" SG_ 708 PCS_chgPhAInputCurrentLimitReaso "PCS_chgPhAInputCurrentLimitReason";
BA_ "Confidence" SG_ 708 PCS_chgPhBInputIrms 0;
BA_ "Confidence" SG_ 708 PCS_chgPhBIntBusV 0;
BA_ "Confidence" SG_ 708 PCS_chgPhBIntBusVTarget 0;
BA_ "Confidence" SG_ 708 PCS_chgPhBOutputI 0;
BA_ "Confidence" SG_ 708 PCS_chgPhBInputCurrentLimitReaso 0;
BA_ "SystemSignalLongSymbol" SG_ 708 PCS_chgPhBInputCurrentLimitReaso "PCS_chgPhBInputCurrentLimitReason";
BA_ "Confidence" SG_ 708 PCS_chgPhCInputIrms 0;
BA_ "Confidence" SG_ 708 PCS_chgPhCIntBusV 0;
BA_ "Confidence" SG_ 708 PCS_chgPhCIntBusVTarget 0;
BA_ "Confidence" SG_ 708 PCS_chgPhCOutputI 0;
BA_ "Confidence" SG_ 708 PCS_chgPhCInputCurrentLimitReaso 0;
BA_ "SystemSignalLongSymbol" SG_ 708 PCS_chgPhCInputCurrentLimitReaso "PCS_chgPhCInputCurrentLimitReason";
BA_ "Confidence" SG_ 708 PCS_chgInputL1NVrms 0;
BA_ "Confidence" SG_ 708 PCS_chgInputL2NVrms 0;
BA_ "Confidence" SG_ 708 PCS_chgInputL3NVrms 0;
BA_ "Confidence" SG_ 708 PCS_chgInputL1L2Vrms 0;
BA_ "Confidence" SG_ 708 PCS_chgInputNGVrms 0;
BA_ "Confidence" SG_ 708 PCS_chgInputFrequencyL1N 0;
BA_ "Confidence" SG_ 708 PCS_chgInputFrequencyL2N 0;
BA_ "Confidence" SG_ 708 PCS_chgInputFrequencyL3N 0;
BA_ "Confidence" SG_ 708 PCS_chgInternalPhaseConfig 0;
BA_ "GenSigSNA" SG_ 708 PCS_chgInternalPhaseConfig "0";
BA_ "Confidence" SG_ 708 PCS_chgPhasesPriority 0;
BA_ "Confidence" SG_ 708 PCS_chgOutputV 0;
BA_ "Confidence" SG_ 708 PCS_chgPhAState 0;
BA_ "Confidence" SG_ 708 PCS_chgPhBState 0;
BA_ "Confidence" SG_ 708 PCS_chgPhCState 0;
BA_ "Confidence" SG_ 708 PCS_chgPhALastShutdownReason 0;
BA_ "Confidence" SG_ 708 PCS_chgPhBLastShutdownReason 0;
BA_ "Confidence" SG_ 708 PCS_chgPhCLastShutdownReason 0;
BA_ "Confidence" SG_ 708 PCS_chgPhARetryCount 0;
BA_ "Confidence" SG_ 708 PCS_chgPhBRetryCount 0;
BA_ "Confidence" SG_ 708 PCS_chgPhCRetryCount 0;
BA_ "Confidence" SG_ 708 PCS_chgRetryCount 0;
BA_ "Confidence" SG_ 708 PCS_chgPhManCurrentToDist 0;
BA_ "Confidence" SG_ 708 PCS_chgL1NPllLocked 0;
BA_ "Confidence" SG_ 708 PCS_chgL2NPllLocked 0;
BA_ "Confidence" SG_ 708 PCS_chgL3NPllLocked 0;
BA_ "Confidence" SG_ 708 PCS_chgL1L2PllLocked 0;
BA_ "Confidence" SG_ 708 PCS_chgNgPllLocked 0;
BA_ "Confidence" SG_ 708 PCS_chgPhManOptimalPhsToUse 0;
BA_ "Confidence" SG_ 708 PCS_chg5VL1Enable 0;
BA_ "Confidence" SG_ 708 PCS_dcdcMaxLvOutputCurrent 0;
BA_ "Confidence" SG_ 708 PCS_dcdcCurrentLimit 0;
BA_ "Confidence" SG_ 708 PCS_dcdcLvOutputCurrentTempLimit 0;
BA_ "Confidence" SG_ 708 PCS_dcdcLvOutputCurrentFiltered 0;
BA_ "Confidence" SG_ 708 PCS_dcdcUnifiedCommand 0;
BA_ "Confidence" SG_ 708 PCS_dcdcCLAControllerOutput 0;
BA_ "Confidence" SG_ 708 PCS_dcdcTankVoltage 0;
BA_ "GenSigSNA" SG_ 708 PCS_dcdcTankVoltage "1024";
BA_ "Confidence" SG_ 708 PCS_dcdcTankVoltageTarget 0;
BA_ "Confidence" SG_ 708 PCS_dcdcClaCurrentFreq 0;
BA_ "Confidence" SG_ 708 PCS_dcdcTCommMeasured 0;
BA_ "Confidence" SG_ 708 PCS_dcdcShortTimeUs 0;
BA_ "Confidence" SG_ 708 PCS_dcdcHalfPeriodUs 0;
BA_ "Confidence" SG_ 708 PCS_dcdcLvBusVoltTargetWithOffse 0;
BA_ "SystemSignalLongSymbol" SG_ 708 PCS_dcdcLvBusVoltTargetWithOffse "PCS_dcdcLvBusVoltTargetWithOffset";
BA_ "Confidence" SG_ 708 PCS_cpu2BootState 0;
BA_ "Confidence" SG_ 708 PCS_acChargeSelfTestState 0;
BA_ "Confidence" SG_ 708 PCS_1V5Min10s 0;
BA_ "Confidence" SG_ 708 PCS_1V5Max10s 0;
BA_ "Confidence" SG_ 708 PCS_1V2Min10s 0;
BA_ "Confidence" SG_ 708 PCS_1V2Max10s 0;
BA_ "Confidence" SG_ 708 PCS_5VNMax10s 0;
BA_ "Confidence" SG_ 708 PCS_chgPhAIntBusVMin10s 0;
BA_ "Confidence" SG_ 708 PCS_chgPhAIntBusVMax10s 0;
BA_ "Confidence" SG_ 708 PCS_chgPhAPchgVoltDeltaMax10s 0;
BA_ "Confidence" SG_ 708 PCS_chgPhALifetimekWh 0;
BA_ "Confidence" SG_ 708 PCS_chgPhATransientRetryCount 0;
BA_ "Confidence" SG_ 708 PCS_chgPhBIntBusVMin10s 0;
BA_ "Confidence" SG_ 708 PCS_chgPhBIntBusVMax10s 0;
BA_ "Confidence" SG_ 708 PCS_chgPhBPchgVoltDeltaMax10s 0;
BA_ "Confidence" SG_ 708 PCS_chgPhBLifetimekWh 0;
BA_ "Confidence" SG_ 708 PCS_chgPhBTransientRetryCount 0;
BA_ "Confidence" SG_ 708 PCS_chgPhCIntBusVMin10s 0;
BA_ "Confidence" SG_ 708 PCS_chgPhCIntBusVMax10s 0;
BA_ "Confidence" SG_ 708 PCS_chgPhCPchgVoltDeltaMax10s 0;
BA_ "Confidence" SG_ 708 PCS_chgPhCLifetimekWh 0;
BA_ "Confidence" SG_ 708 PCS_chgPhCTransientRetryCount 0;
BA_ "Confidence" SG_ 708 PCS_chgPhANoFlowBucket 0;
BA_ "Confidence" SG_ 708 PCS_chgPhBNoFlowBucket 0;
BA_ "Confidence" SG_ 708 PCS_chgPhCNoFlowBucket 0;
BA_ "Confidence" SG_ 708 PCS_chgCurrentSensorOutOfBandUs 0;
BA_ "Confidence" SG_ 708 PCS_chgAcpwHeartbeatState 0;
BA_ "Confidence" SG_ 708 PCS_chgKwhLostByFreqDroop 0;
BA_ "Confidence" SG_ 708 PCS_chgReqKwhLostByFreqDroop 0;
BA_ "Confidence" SG_ 708 PCS_dcdcLvSupportLifetimekWh 0;
BA_ "Confidence" SG_ 708 PCS_chgPwmEnableLineErrorCount 0;
BA_ "Confidence" SG_ 708 PCS_dcdcPwmEnableLineErrorCount 0;
BA_ "Confidence" SG_ 708 PCS_numAlertsSet 0;
BA_ "Confidence" SG_ 708 PCS_dcdcPchgStartLvBusVolt 0;
BA_ "Confidence" SG_ 708 PCS_dcdcPchgStartHvBusVolt 0;
BA_ "Confidence" SG_ 708 PCS_processorDieIdLot 0;
BA_ "Confidence" SG_ 708 PCS_processorDieIdWafer 0;
BA_ "Confidence" SG_ 708 PCS_processorDieIdX 0;
BA_ "Confidence" SG_ 708 PCS_processorDieIdY 0;
BA_ "Confidence" SG_ 676 PCS_chgPhATemp 0;
BA_ "GenSigSNA" SG_ 676 PCS_chgPhATemp "1025";
BA_ "Confidence" SG_ 676 PCS_chgPhBTemp 0;
BA_ "GenSigSNA" SG_ 676 PCS_chgPhBTemp "1025";
BA_ "Confidence" SG_ 676 PCS_chgPhCTemp 0;
BA_ "GenSigSNA" SG_ 676 PCS_chgPhCTemp "1025";
BA_ "Confidence" SG_ 676 PCS_dcdcTemp 0;
BA_ "GenSigSNA" SG_ 676 PCS_dcdcTemp "1025";
BA_ "Confidence" SG_ 676 PCS_ambientTemp 0;
BA_ "GenSigSNA" SG_ 676 PCS_ambientTemp "1025";
BA_ "Confidence" SG_ 676 PCS_dcdcBusbarTemp 0;
BA_ "GenSigSNA" SG_ 676 PCS_dcdcBusbarTemp "511";
BA_ "Confidence" SG_ 790 PMF_infoIndex 1;
BA_ "Confidence" SG_ 790 PMF_buildType 0;
BA_ "Confidence" SG_ 790 PMF_buildConfigurationId 0;
BA_ "Confidence" SG_ 790 PMF_hardwareId 0;
BA_ "Confidence" SG_ 790 PMF_deviceFused 0;
BA_ "Confidence" SG_ 790 PMF_componentId 0;
BA_ "Confidence" SG_ 790 PMF_pcbaId 0;
BA_ "Confidence" SG_ 790 PMF_assemblyId 0;
BA_ "Confidence" SG_ 790 PMF_usageId 0;
BA_ "Confidence" SG_ 790 PMF_subUsageId 0;
BA_ "Confidence" SG_ 790 PMF_applicationCrc 0;
BA_ "Confidence" SG_ 790 PMF_appGitHash 0;
BA_ "Confidence" SG_ 790 PMF_bootGitHash 0;
BA_ "Confidence" SG_ 790 PMF_platformTyp 0;
BA_ "Confidence" SG_ 790 PMF_udsProtocolVersion 0;
BA_ "Confidence" SG_ 790 PMF_bootloaderCrc 0;
BA_ "Confidence" SG_ 1748 PMR_infoIndex 1;
BA_ "Confidence" SG_ 1748 PMR_buildType 0;
BA_ "Confidence" SG_ 1748 PMR_buildConfigurationId 0;
BA_ "Confidence" SG_ 1748 PMR_hardwareId 0;
BA_ "Confidence" SG_ 1748 PMR_deviceFused 0;
BA_ "Confidence" SG_ 1748 PMR_componentId 0;
BA_ "Confidence" SG_ 1748 PMR_pcbaId 0;
BA_ "Confidence" SG_ 1748 PMR_assemblyId 0;
BA_ "Confidence" SG_ 1748 PMR_usageId 0;
BA_ "Confidence" SG_ 1748 PMR_subUsageId 0;
BA_ "Confidence" SG_ 1748 PMR_applicationCrc 0;
BA_ "Confidence" SG_ 1748 PMR_appGitHash 0;
BA_ "Confidence" SG_ 1748 PMR_bootGitHash 0;
BA_ "Confidence" SG_ 1748 PMR_platformTyp 0;
BA_ "Confidence" SG_ 1748 PMR_udsProtocolVersion 0;
BA_ "Confidence" SG_ 1748 PMR_bootloaderCrc 0;
BA_ "Confidence" SG_ 1551 PM_infoIndex 1;
BA_ "Confidence" SG_ 1551 PM_buildType 0;
BA_ "Confidence" SG_ 1551 PM_buildConfigurationId 0;
BA_ "Confidence" SG_ 1551 PM_hardwareId 0;
BA_ "Confidence" SG_ 1551 PM_deviceFused 0;
BA_ "Confidence" SG_ 1551 PM_componentId 0;
BA_ "Confidence" SG_ 1551 PM_pcbaId 0;
BA_ "Confidence" SG_ 1551 PM_assemblyId 0;
BA_ "Confidence" SG_ 1551 PM_usageId 0;
BA_ "Confidence" SG_ 1551 PM_subUsageId 0;
BA_ "Confidence" SG_ 1551 PM_applicationCrc 0;
BA_ "Confidence" SG_ 1551 PM_bootGitHash 0;
BA_ "Confidence" SG_ 837 PTC_infoIndex 1;
BA_ "Confidence" SG_ 837 PTC_infoBuildType 0;
BA_ "Confidence" SG_ 837 PTC_infoBuildConfigId 0;
BA_ "Confidence" SG_ 837 PTC_infoHardwareId 0;
BA_ "Confidence" SG_ 837 PTC_infoComponentId 0;
BA_ "Confidence" SG_ 837 PTC_infoPcbaId 0;
BA_ "Confidence" SG_ 837 PTC_infoAssemblyId 0;
BA_ "GenSigSNA" SG_ 837 PTC_infoAssemblyId "255";
BA_ "Confidence" SG_ 837 PTC_infoUsageId 0;
BA_ "Confidence" SG_ 837 PTC_infoSubUsageId 0;
BA_ "Confidence" SG_ 837 PTC_infoPlatformType 0;
BA_ "Confidence" SG_ 837 PTC_infoAppCrc 0;
BA_ "Confidence" SG_ 837 PTC_infoBootUdsProtoVersion 0;
BA_ "Confidence" SG_ 837 PTC_infoBootCrc 0;
BA_ "Confidence" SG_ 647 PTC_leftTempIGBT 0;
BA_ "Confidence" SG_ 647 PTC_tempOCP 0;
BA_ "Confidence" SG_ 647 PTC_rightTempIGBT 0;
BA_ "Confidence" SG_ 647 PTC_tempPCB 0;
BA_ "Confidence" SG_ 647 PTC_voltageHV 0;
BA_ "Confidence" SG_ 647 PTC_leftCurrentHV 0;
BA_ "Confidence" SG_ 647 PTC_rightCurrentHV 0;
BA_ "Confidence" SG_ 816 SCCM_infoIndex 1;
BA_ "Confidence" SG_ 816 SCCM_infoBuildType 0;
BA_ "Confidence" SG_ 816 SCCM_infoBuildConfigId 0;
BA_ "Confidence" SG_ 816 SCCM_infoHardwareId 0;
BA_ "Confidence" SG_ 816 SCCM_infoComponentId 0;
BA_ "Confidence" SG_ 816 SCCM_infoPcbaId 0;
BA_ "Confidence" SG_ 816 SCCM_infoAssemblyId 0;
BA_ "Confidence" SG_ 816 SCCM_infoUsageId 0;
BA_ "Confidence" SG_ 816 SCCM_infoSubUsageId 0;
BA_ "Confidence" SG_ 816 SCCM_infoPlatformType 0;
BA_ "Confidence" SG_ 816 SCCM_infoBootSvnRev 0;
BA_ "Confidence" SG_ 816 SCCM_infoBootSvnUrlHash 0;
BA_ "Confidence" SG_ 816 SCCM_infoSubcomponent1Version 0;
BA_ "Confidence" SG_ 816 SCCM_infoAppSvnHash 0;
BA_ "Confidence" SG_ 816 SCCM_infoBootSvnHash 0;
BA_ "Confidence" SG_ 816 SCCM_infoUdsProtoVersion 0;
BA_ "Confidence" SG_ 816 SCCM_infoBootCrc 0;
BA_ "Confidence" SG_ 585 SCCM_leftStalkCrc 0;
BA_ "Confidence" SG_ 585 SCCM_leftStalkCounter 0;
BA_ "Confidence" SG_ 585 SCCM_highBeamStalkStatus 0;
BA_ "GenSigSNA" SG_ 585 SCCM_highBeamStalkStatus "3";
BA_ "Confidence" SG_ 585 SCCM_washWipeButtonStatus 0;
BA_ "GenSigSNA" SG_ 585 SCCM_washWipeButtonStatus "3";
BA_ "Confidence" SG_ 585 SCCM_turnIndicatorStalkStatus 0;
BA_ "GenSigSNA" SG_ 585 SCCM_turnIndicatorStalkStatus "9";
BA_ "Confidence" SG_ 585 SCCM_turnIndicatorStalkAngle 0;
BA_ "GenSigSNA" SG_ 585 SCCM_turnIndicatorStalkAngle "4095";
BA_ "Confidence" SG_ 553 SCCM_rightStalkCrc 0;
BA_ "Confidence" SG_ 553 SCCM_rightStalkCounter 0;
BA_ "Confidence" SG_ 553 SCCM_rightStalkStatus 0;
BA_ "GenSigSNA" SG_ 553 SCCM_rightStalkStatus "6";
BA_ "Confidence" SG_ 553 SCCM_rightStalkReserved1 0;
BA_ "Confidence" SG_ 553 SCCM_parkButtonStatus 0;
BA_ "GenSigSNA" SG_ 553 SCCM_parkButtonStatus "3";
BA_ "Confidence" SG_ 553 SCCM_rightStalkReserved2 0;
BA_ "Confidence" SG_ 297 SCCM_steeringAngleCrc 0;
BA_ "Confidence" SG_ 297 SCCM_steeringAngleCounter 0;
BA_ "Confidence" SG_ 297 SCCM_supplierID 0;
BA_ "Confidence" SG_ 297 SCCM_steeringAngleSensorStatus 0;
BA_ "Confidence" SG_ 297 SCCM_steeringAngle 0;
BA_ "GenSigSNA" SG_ 297 SCCM_steeringAngle "16383";
BA_ "Confidence" SG_ 297 SCCM_steeringAngleValidity 0;
BA_ "GenSigSNA" SG_ 297 SCCM_steeringAngleValidity "3";
BA_ "Confidence" SG_ 297 SCCM_steeringAngleSpeed 0;
BA_ "Confidence" SG_ 297 SCCM_steeringAngleSensorReservd1 0;
BA_ "Confidence" SG_ 297 SCCM_steeringAngleSensorReservd2 0;
BA_ "Confidence" SG_ 297 SCCM_steeringAngleSensorReservd3 0;
BA_ "Confidence" SG_ 1597 SDCR_infoIndex 1;
BA_ "Confidence" SG_ 1597 SDCR_infoBuildType 1;
BA_ "Confidence" SG_ 1597 SDCR_infoBuildConfigId 0;
BA_ "Confidence" SG_ 1597 SDCR_infoHardwareId 0;
BA_ "Confidence" SG_ 1597 SDCR_infoSubUsageId 0;
BA_ "Confidence" SG_ 1597 SDCR_infoBootGitHash 0;
BA_ "Confidence" SG_ 523 TAS_axleIndex 1;
BA_ "Confidence" SG_ 523 TAS_rawHeightFL 0;
BA_ "GenSigSNA" SG_ 523 TAS_rawHeightFL "1023";
BA_ "Confidence" SG_ 523 TAS_staticHeightEstimateFL 0;
BA_ "GenSigSNA" SG_ 523 TAS_staticHeightEstimateFL "1023";
BA_ "Confidence" SG_ 523 TAS_componentPressureFL 0;
BA_ "GenSigSNA" SG_ 523 TAS_componentPressureFL "255";
BA_ "Confidence" SG_ 523 TAS_rawHeightFR 0;
BA_ "GenSigSNA" SG_ 523 TAS_rawHeightFR "1023";
BA_ "Confidence" SG_ 523 TAS_staticHeightEstimateFR 0;
BA_ "GenSigSNA" SG_ 523 TAS_staticHeightEstimateFR "1023";
BA_ "Confidence" SG_ 523 TAS_componentPressureFR 0;
BA_ "GenSigSNA" SG_ 523 TAS_componentPressureFR "255";
BA_ "Confidence" SG_ 523 TAS_rawHeightRL 0;
BA_ "GenSigSNA" SG_ 523 TAS_rawHeightRL "1023";
BA_ "Confidence" SG_ 523 TAS_staticHeightEstimateRL 0;
BA_ "GenSigSNA" SG_ 523 TAS_staticHeightEstimateRL "1023";
BA_ "Confidence" SG_ 523 TAS_componentPressureRL 0;
BA_ "GenSigSNA" SG_ 523 TAS_componentPressureRL "255";
BA_ "Confidence" SG_ 523 TAS_rawHeightRR 0;
BA_ "GenSigSNA" SG_ 523 TAS_rawHeightRR "1023";
BA_ "Confidence" SG_ 523 TAS_staticHeightEstimateRR 0;
BA_ "GenSigSNA" SG_ 523 TAS_staticHeightEstimateRR "1023";
BA_ "Confidence" SG_ 523 TAS_componentPressureRR 0;
BA_ "GenSigSNA" SG_ 523 TAS_componentPressureRR "255";
BA_ "Confidence" SG_ 1398 TAS_endstopState 0;
BA_ "Confidence" SG_ 1398 TAS_continuousControlState 0;
BA_ "Confidence" SG_ 1398 TAS_activeTireTune 0;
BA_ "Confidence" SG_ 1398 TAS_roughnessRaiseReason 0;
BA_ "Confidence" SG_ 1398 TAS_frontMetricDrivesRear 0;
BA_ "Confidence" SG_ 1398 TAS_roadCondition 0;
BA_ "GenSigSNA" SG_ 1398 TAS_roadCondition "255";
BA_ "Confidence" SG_ 1398 TAS_bellyProtect 0;
BA_ "Confidence" SG_ 1398 TAS_frontMetricDrivesFront 0;
BA_ "Confidence" SG_ 1398 TAS_speedBumpAxleFront 0;
BA_ "Confidence" SG_ 1398 TAS_speedBumpAxleRear 0;
BA_ "Confidence" SG_ 1398 TAS_holeProtectFL 0;
BA_ "Confidence" SG_ 1398 TAS_holeProtectFR 0;
BA_ "Confidence" SG_ 1398 TAS_holeProtectRL 0;
BA_ "Confidence" SG_ 1398 TAS_holeProtectRR 0;
BA_ "Confidence" SG_ 1398 TAS_stepProtectFL 0;
BA_ "Confidence" SG_ 1398 TAS_stepProtectFR 0;
BA_ "Confidence" SG_ 1398 TAS_stepProtectRL 0;
BA_ "Confidence" SG_ 1398 TAS_stepProtectRR 0;
BA_ "Confidence" SG_ 1398 TAS_FDUTorqueCorruptionScale 0;
BA_ "GenSigSNA" SG_ 1398 TAS_FDUTorqueCorruptionScale "15";
BA_ "Confidence" SG_ 1398 TAS_sprungMassEstimate 0;
BA_ "GenSigSNA" SG_ 1398 TAS_sprungMassEstimate "31";
BA_ "Confidence" SG_ 1398 TAS_anyDamperActive 0;
BA_ "Confidence" SG_ 1398 TAS_dampingStatesCounter 0;
BA_ "Confidence" SG_ 1398 TAS_dampingStatesChecksum 0;
BA_ "Confidence" SG_ 1357 TAS_infoIndex 1;
BA_ "Confidence" SG_ 1357 TAS_infoBuildType 0;
BA_ "Confidence" SG_ 1357 TAS_infoBuildConfigId 0;
BA_ "Confidence" SG_ 1357 TAS_infoHardwareId 0;
BA_ "Confidence" SG_ 1357 TAS_infoComponentId 0;
BA_ "Confidence" SG_ 1357 TAS_infoPcbaId 0;
BA_ "Confidence" SG_ 1357 TAS_infoAssemblyId 0;
BA_ "GenSigSNA" SG_ 1357 TAS_infoAssemblyId "255";
BA_ "Confidence" SG_ 1357 TAS_infoUsageId 0;
BA_ "Confidence" SG_ 1357 TAS_infoSubUsageId 0;
BA_ "Confidence" SG_ 1357 TAS_infoAppCrc 0;
BA_ "Confidence" SG_ 1357 TAS_infoAppGitHash 0;
BA_ "Confidence" SG_ 1357 TAS_infoBootGitHash 0;
BA_ "Confidence" SG_ 1357 TAS_infoPlatformType 0;
BA_ "Confidence" SG_ 1357 TAS_infoMajorVersion 0;
BA_ "GenSigSNA" SG_ 1357 TAS_infoMajorVersion "255";
BA_ "Confidence" SG_ 1357 TAS_infoBranchOrigin 0;
BA_ "GenSigSNA" SG_ 1357 TAS_infoBranchOrigin "255";
BA_ "Confidence" SG_ 1357 TAS_infoMaturity 0;
BA_ "GenSigSNA" SG_ 1357 TAS_infoMaturity "255";
BA_ "Confidence" SG_ 1357 TAS_infoHardwareRevision 0;
BA_ "GenSigSNA" SG_ 1357 TAS_infoHardwareRevision "255";
BA_ "Confidence" SG_ 525 TAS_levelingState 0;
BA_ "Confidence" SG_ 525 TAS_levelingItem 0;
BA_ "Confidence" SG_ 525 TAS_pressureGallery 0;
BA_ "GenSigSNA" SG_ 525 TAS_pressureGallery "255";
BA_ "Confidence" SG_ 525 TAS_pressureReservoir 0;
BA_ "GenSigSNA" SG_ 525 TAS_pressureReservoir "255";
BA_ "Confidence" SG_ 525 TAS_runMode 0;
BA_ "Confidence" SG_ 525 TAS_filterMode 0;
BA_ "Confidence" SG_ 525 TAS_compressorRun 0;
BA_ "Confidence" SG_ 525 TAS_twistDetected 0;
BA_ "Confidence" SG_ 525 TAS_leanDetected 0;
BA_ "Confidence" SG_ 525 TAS_limpHomeMode 0;
BA_ "Confidence" SG_ 525 TAS_targetLevel 0;
BA_ "Confidence" SG_ 525 TAS_currentLevel 0;
BA_ "Confidence" SG_ 525 TAS_jackMode 0;
BA_ "Confidence" SG_ 525 TAS_reduceVehicleSpeedRequest 0;
BA_ "Confidence" SG_ 525 TAS_statesCounter 0;
BA_ "Confidence" SG_ 525 TAS_statesChecksum 0;
BA_ "Confidence" SG_ 409 TAS_adaptiveActivityFL_C 0;
BA_ "GenSigSNA" SG_ 409 TAS_adaptiveActivityFL_C "31";
BA_ "Confidence" SG_ 409 TAS_adaptiveActivityFL_R 0;
BA_ "GenSigSNA" SG_ 409 TAS_adaptiveActivityFL_R "31";
BA_ "Confidence" SG_ 409 TAS_adaptiveActivityFR_C 0;
BA_ "GenSigSNA" SG_ 409 TAS_adaptiveActivityFR_C "31";
BA_ "Confidence" SG_ 409 TAS_adaptiveActivityFR_R 0;
BA_ "GenSigSNA" SG_ 409 TAS_adaptiveActivityFR_R "31";
BA_ "Confidence" SG_ 409 TAS_adaptiveActivityRL_C 0;
BA_ "GenSigSNA" SG_ 409 TAS_adaptiveActivityRL_C "31";
BA_ "Confidence" SG_ 409 TAS_adaptiveActivityRL_R 0;
BA_ "GenSigSNA" SG_ 409 TAS_adaptiveActivityRL_R "31";
BA_ "Confidence" SG_ 409 TAS_adaptiveActivityRR_C 0;
BA_ "GenSigSNA" SG_ 409 TAS_adaptiveActivityRR_C "31";
BA_ "Confidence" SG_ 409 TAS_adaptiveActivityRR_R 0;
BA_ "GenSigSNA" SG_ 409 TAS_adaptiveActivityRR_R "31";
BA_ "Confidence" SG_ 409 TAS_uiHeightFL 0;
BA_ "GenSigSNA" SG_ 409 TAS_uiHeightFL "63";
BA_ "Confidence" SG_ 409 TAS_uiHeightFR 0;
BA_ "GenSigSNA" SG_ 409 TAS_uiHeightFR "63";
BA_ "Confidence" SG_ 409 TAS_uiHeightRL 0;
BA_ "GenSigSNA" SG_ 409 TAS_uiHeightRL "63";
BA_ "Confidence" SG_ 409 TAS_uiHeightRR 0;
BA_ "GenSigSNA" SG_ 409 TAS_uiHeightRR "63";
BA_ "Confidence" SG_ 410 TAS_bodyAccelFL 0;
BA_ "GenSigSNA" SG_ 410 TAS_bodyAccelFL "255";
BA_ "Confidence" SG_ 410 TAS_bodyAccelFR 0;
BA_ "GenSigSNA" SG_ 410 TAS_bodyAccelFR "255";
BA_ "Confidence" SG_ 410 TAS_bodyAccelRL 0;
BA_ "GenSigSNA" SG_ 410 TAS_bodyAccelRL "255";
BA_ "Confidence" SG_ 410 TAS_bodyAccelRR 0;
BA_ "GenSigSNA" SG_ 410 TAS_bodyAccelRR "255";
BA_ "Confidence" SG_ 538 TAS_yellowWarningLamp 0;
BA_ "Confidence" SG_ 538 TAS_redWarningLamp 0;
BA_ "Confidence" SG_ 538 TAS_veryLowAllowed 0;
BA_ "Confidence" SG_ 538 TAS_lowAllowed 0;
BA_ "Confidence" SG_ 538 TAS_standardAllowed 0;
BA_ "Confidence" SG_ 538 TAS_highAllowed 0;
BA_ "Confidence" SG_ 538 TAS_veryHighAllowed 0;
BA_ "Confidence" SG_ 538 TAS_extractAllowed 0;
BA_ "Confidence" SG_ 538 TAS_showSpinner 0;
BA_ "Confidence" SG_ 538 TAS_adaptiveRideModeOverride 0;
BA_ "GenSigSNA" SG_ 538 TAS_adaptiveRideModeOverride "3";
BA_ "Confidence" SG_ 538 TAS_levelSelectEnabled 0;
BA_ "Confidence" SG_ 538 TAS_jackModeToggleEnabled 0;
BA_ "Confidence" SG_ 538 TAS_adaptiveRideSelectEnabled 0;
BA_ "Confidence" SG_ 538 TAS_launchModeState 0;
BA_ "Confidence" SG_ 538 TAS_restrictUpLevelingFalcons 0;
BA_ "Confidence" SG_ 538 TAS_restrictUpLevelingTrunk 0;
BA_ "Confidence" SG_ 538 TAS_restrictDownLevelingDoors 0;
BA_ "Confidence" SG_ 538 TAS_restrictLevelingChargeCable 0;
BA_ "Confidence" SG_ 538 TAS_restrictLevelingSystemCheck 0;
BA_ "Confidence" SG_ 538 TAS_restrictLevelingTransport 0;
BA_ "Confidence" SG_ 538 TAS_restrictLevelingShowroom 0;
BA_ "Confidence" SG_ 538 TAS_uiControlCounter 0;
BA_ "Confidence" SG_ 538 TAS_uiControlChecksum 0;
BA_ "Confidence" SG_ 1657 UI_rgbEnableState 0;
BA_ "Confidence" SG_ 1657 UI_rgbEffectType 0;
BA_ "Confidence" SG_ 1657 UI_rgbBrightnessLevel 0;
BA_ "GenSigSNA" SG_ 1657 UI_rgbBrightnessLevel "127";
BA_ "Confidence" SG_ 1657 UI_rgbTargetDOORFL 0;
BA_ "Confidence" SG_ 1657 UI_rgbTargetDOORFR 0;
BA_ "Confidence" SG_ 1657 UI_rgbTargetDOORRL 0;
BA_ "Confidence" SG_ 1657 UI_rgbTargetDOORRR 0;
BA_ "Confidence" SG_ 1657 UI_rgbTargetIPFL 0;
BA_ "Confidence" SG_ 1657 UI_rgbTargetIPFR 0;
BA_ "Confidence" SG_ 1021 UI_autopilotControlIndex 1;
BA_ "Confidence" SG_ 1021 UI_hovEnabled 0;
BA_ "Confidence" SG_ 1021 UI_smartSetSpeedOffset 0;
BA_ "Confidence" SG_ 1021 UI_smartSetSpeedOffsetType 0;
BA_ "Confidence" SG_ 1021 UI_fsdStopsControlEnabled 0;
BA_ "Confidence" SG_ 1021 UI_smartSetSpeed 0;
BA_ "Confidence" SG_ 1021 UI_automaticSetSpeedOffset 0;
BA_ "Confidence" SG_ 1021 UI_enableFullSelfDriving 0;
BA_ "Confidence" SG_ 1021 UI_hasFullSelfDriving 0;
BA_ "Confidence" SG_ 1021 UI_autosteerActivation 0;
BA_ "Confidence" SG_ 1021 UI_autopilotDrivingProfile 1;
BA_ "Confidence" SG_ 1021 UI_fsdBetaRequest 0;
BA_ "Confidence" SG_ 1021 UI_fullSelfDrivingSuspended 0;
BA_ "Confidence" SG_ 1021 UI_disableOptionalLaneChanges 0;
BA_ "Confidence" SG_ 1021 UI_selectableCameraRequest 0;
BA_ "GenSigSNA" SG_ 1021 UI_selectableCameraRequest "15";
BA_ "Confidence" SG_ 1021 UI_driverMonitorConfirmation 0;
BA_ "Confidence" SG_ 1021 UI_parkAssistUseVision 0;
BA_ "Confidence" SG_ 1021 UI_noStalkConfirmAlertHaptic 0;
BA_ "Confidence" SG_ 1021 UI_noStalkConfirmAlertChime 0;
BA_ "Confidence" SG_ 1021 UI_factorySummonEnable 0;
BA_ "Confidence" SG_ 1021 UI_enableCabinCamera 0;
BA_ "Confidence" SG_ 1021 UI_enableAutopilotStopWarning 0;
BA_ "Confidence" SG_ 1021 UI_enableVisionSpeedControl 0;
BA_ "Confidence" SG_ 1021 UI_enableTeslaAutopark 0;
BA_ "Confidence" SG_ 1021 UI_autoTurnSignalMode 0;
BA_ "Confidence" SG_ 1021 UI_enableCabinAudioRecording 0;
BA_ "Confidence" SG_ 819 UI_openChargePortDoorRequest 0;
BA_ "Confidence" SG_ 819 UI_closeChargePortDoorRequest 0;
BA_ "Confidence" SG_ 819 UI_chargeEnableRequest 0;
BA_ "Confidence" SG_ 819 UI_acChargeCurrentLimit 0;
BA_ "GenSigSNA" SG_ 819 UI_acChargeCurrentLimit "127";
BA_ "Confidence" SG_ 819 UI_dSocAlertEnable 1;
BA_ "Confidence" SG_ 819 UI_chargeTerminationPct 0;
BA_ "Confidence" SG_ 819 UI_scheduledDepartureEnabled 0;
BA_ "Confidence" SG_ 819 UI_chargePortLatchRequest 0;
BA_ "Confidence" SG_ 819 UI_cpInletHeaterRequest 0;
BA_ "Confidence" SG_ 659 UI_steeringTuneRequest 0;
BA_ "Confidence" SG_ 659 UI_tractionControlMode 0;
BA_ "Confidence" SG_ 659 UI_parkBrakeRequest 0;
BA_ "GenSigSNA" SG_ 659 UI_parkBrakeRequest "3";
BA_ "Confidence" SG_ 659 UI_winchModeRequest 0;
BA_ "Confidence" SG_ 659 UI_trailerMode 0;
BA_ "Confidence" SG_ 659 UI_accOvertakeEnable 0;
BA_ "GenSigSNA" SG_ 659 UI_accOvertakeEnable "3";
BA_ "Confidence" SG_ 659 UI_aebEnable 0;
BA_ "GenSigSNA" SG_ 659 UI_aebEnable "3";
BA_ "Confidence" SG_ 659 UI_aesEnable 0;
BA_ "GenSigSNA" SG_ 659 UI_aesEnable "3";
BA_ "Confidence" SG_ 659 UI_ahlbEnable 0;
BA_ "GenSigSNA" SG_ 659 UI_ahlbEnable "3";
BA_ "Confidence" SG_ 659 UI_autoLaneChangeEnable 0;
BA_ "GenSigSNA" SG_ 659 UI_autoLaneChangeEnable "3";
BA_ "Confidence" SG_ 659 UI_winchProxUserOverride 0;
BA_ "Confidence" SG_ 659 UI_autoParkRequest 0;
BA_ "GenSigSNA" SG_ 659 UI_autoParkRequest "15";
BA_ "Confidence" SG_ 659 UI_bsdEnable 0;
BA_ "GenSigSNA" SG_ 659 UI_bsdEnable "3";
BA_ "Confidence" SG_ 659 UI_fcwEnable 0;
BA_ "GenSigSNA" SG_ 659 UI_fcwEnable "3";
BA_ "Confidence" SG_ 659 UI_fcwSensitivity 0;
BA_ "GenSigSNA" SG_ 659 UI_fcwSensitivity "3";
BA_ "Confidence" SG_ 659 UI_latControlEnable 0;
BA_ "GenSigSNA" SG_ 659 UI_latControlEnable "3";
BA_ "Confidence" SG_ 659 UI_ldwEnable 0;
BA_ "GenSigSNA" SG_ 659 UI_ldwEnable "3";
BA_ "Confidence" SG_ 531 UI_cruiseSpeedCommand 0;
BA_ "Confidence" SG_ 568 UI_roadClass 0;
BA_ "GenSigSNA" SG_ 568 UI_roadClass "0";
BA_ "Confidence" SG_ 568 UI_navRouteActive 0;
BA_ "Confidence" SG_ 568 UI_parallelAutoparkEnabled 0;
BA_ "Confidence" SG_ 568 UI_perpendicularAutoparkEnabled 0;
BA_ "Confidence" SG_ 568 UI_controlledAccess 0;
BA_ "Confidence" SG_ 568 UI_autosteerRestricted 0;
BA_ "Confidence" SG_ 645 UI_driverProfileRecallIndex 1;
BA_ "GenSigSNA" SG_ 645 UI_driverProfileRecallIndex "0";
BA_ "Confidence" SG_ 645 UI_driverProfileRecallStop 0;
BA_ "Confidence" SG_ 645 UI_frontSeatRecallActive 0;
BA_ "Confidence" SG_ 645 UI_leftMirrorTiltXPosition 0;
BA_ "Confidence" SG_ 645 UI_leftMirrorTiltYPosition 0;
BA_ "Confidence" SG_ 645 UI_customMirrorDipPositionsSet 0;
BA_ "Confidence" SG_ 645 UI_leftMirrorDipXPosition 0;
BA_ "Confidence" SG_ 645 UI_leftMirrorDipYPosition 0;
BA_ "Confidence" SG_ 645 UI_modifyMirrorDipRequest 0;
BA_ "Confidence" SG_ 651 UI_driverProfileIndex 0;
BA_ "Confidence" SG_ 651 UI_driverProfileSelectionType 0;
BA_ "Confidence" SG_ 651 UI_driverProfilePositionAdjusted 0;
BA_ "Confidence" SG_ 651 UI_activeKeyRequested 0;
BA_ "Confidence" SG_ 1139 UI_nmKeepAwakeReason 1;
BA_ "GenSigSNA" SG_ 1139 UI_nmKeepAwakeReason "0";
BA_ "Confidence" SG_ 1139 UI_wakeupTime 0;
BA_ "Confidence" SG_ 883 UI_mapSpeedLimitUnits 0;
BA_ "Confidence" SG_ 883 UI_mppSpeedLimit 0;
BA_ "Confidence" SG_ 883 UI_gpsNmeaMIA 0;
BA_ "Confidence" SG_ 883 UI_gpsAntennaDisconnected 0;
BA_ "Confidence" SG_ 883 UI_conditionalLimitActive 0;
BA_ "Confidence" SG_ 883 UI_conditionalSpeedLimit 0;
BA_ "GenSigSNA" SG_ 883 UI_conditionalSpeedLimit "31";
BA_ "Confidence" SG_ 755 UI_hvacReqTempSetpointLeft 0;
BA_ "Confidence" SG_ 755 UI_hvacReqAutoBlowerLevel 0;
BA_ "Confidence" SG_ 755 UI_hvacReqTempSetpointRight 0;
BA_ "Confidence" SG_ 755 UI_hvacReqAirDistributionMode 0;
BA_ "Confidence" SG_ 755 UI_hvacReqBlowerSegment 0;
BA_ "Confidence" SG_ 755 UI_hvacReqRecirc 0;
BA_ "Confidence" SG_ 755 UI_hvacReqACDisable 0;
BA_ "Confidence" SG_ 755 UI_hvacDefogState 0;
BA_ "Confidence" SG_ 755 UI_hvacReqUserPowerState 0;
BA_ "Confidence" SG_ 755 UI_hvacReqSecondRowState 0;
BA_ "Confidence" SG_ 755 UI_hvacReqKeepClimateOn 0;
BA_ "Confidence" SG_ 755 UI_hvacReqBioWeaponDefMode 0;
BA_ "Confidence" SG_ 755 UI_hvacReqTempSetpointCOP 0;
BA_ "Confidence" SG_ 1523 UI_odometer 0;
BA_ "GenSigSNA" SG_ 1523 UI_odometer "16777215";
BA_ "Confidence" SG_ 948 UI_usbFrontHubPowerStateRequest 0;
BA_ "GenSigSNA" SG_ 948 UI_usbFrontHubPowerStateRequest "0";
BA_ "Confidence" SG_ 827 UI_idlePowerConsumption 0;
BA_ "Confidence" SG_ 827 UI_chargeTimeUntilTerminationPct 0;
BA_ "GenSigSNA" SG_ 827 UI_chargeTimeUntilTerminationPct "2047";
BA_ "Confidence" SG_ 827 UI_chargeTimeUntilReadyToDepart 0;
BA_ "GenSigSNA" SG_ 827 UI_chargeTimeUntilReadyToDepart "2047";
BA_ "Confidence" SG_ 820 UI_pedalMap 0;
BA_ "Confidence" SG_ 820 UI_enableRegenBackfill 0;
BA_ "Confidence" SG_ 820 UI_regenTorqueMax 0;
BA_ "Confidence" SG_ 820 UI_limitMode 0;
BA_ "Confidence" SG_ 820 UI_motorOnMode 0;
BA_ "Confidence" SG_ 820 UI_stoppingMode 1;
BA_ "Confidence" SG_ 820 UI_speedLimit 1;
BA_ "GenSigSNA" SG_ 820 UI_speedLimit "511";
BA_ "Confidence" SG_ 820 UI_enableSmartShift 1;
BA_ "Confidence" SG_ 820 UI_navVehParallelToRdCanContinue 1;
BA_ "GenSigSNA" SG_ 820 UI_navVehParallelToRdCanContinue "0";
BA_ "Confidence" SG_ 826 UI_ratedRange 0;
BA_ "Confidence" SG_ 826 UI_soe 0;
BA_ "Confidence" SG_ 826 UI_uSoe 0;
BA_ "Confidence" SG_ 723 UI_isSunUp 0;
BA_ "GenSigSNA" SG_ 723 UI_isSunUp "3";
BA_ "Confidence" SG_ 723 UI_solarElevationAngle 0;
BA_ "GenSigSNA" SG_ 723 UI_solarElevationAngle "127";
BA_ "Confidence" SG_ 723 UI_screenPCBTemperature 0;
BA_ "Confidence" SG_ 723 UI_minsToSunset 0;
BA_ "Confidence" SG_ 723 UI_minsToSunrise 0;
BA_ "Confidence" SG_ 851 UI_touchActive 0;
BA_ "Confidence" SG_ 851 UI_audioActive 0;
BA_ "Confidence" SG_ 851 UI_cellActive 0;
BA_ "Confidence" SG_ 851 UI_displayReady 0;
BA_ "Confidence" SG_ 851 UI_displayOn 0;
BA_ "Confidence" SG_ 851 UI_wifiActive 0;
BA_ "Confidence" SG_ 851 UI_wifiConnected 0;
BA_ "Confidence" SG_ 851 UI_readyForDrive 0;
BA_ "Confidence" SG_ 851 UI_cellConnected 0;
BA_ "Confidence" SG_ 851 UI_vpnActive 0;
BA_ "Confidence" SG_ 851 UI_factoryReset 0;
BA_ "GenSigSNA" SG_ 851 UI_factoryReset "0";
BA_ "Confidence" SG_ 851 UI_gpsActive 0;
BA_ "Confidence" SG_ 851 UI_cellNetworkTechnology 0;
BA_ "GenSigSNA" SG_ 851 UI_cellNetworkTechnology "15";
BA_ "Confidence" SG_ 851 UI_falseTouchCounter 0;
BA_ "Confidence" SG_ 851 UI_cellSignalBars 0;
BA_ "GenSigSNA" SG_ 851 UI_cellSignalBars "7";
BA_ "Confidence" SG_ 851 UI_trailerModeTelltale 0;
BA_ "Confidence" SG_ 851 UI_pcbTemperature 0;
BA_ "Confidence" SG_ 851 UI_cpuTemperature 0;
BA_ "Confidence" SG_ 991 UI_userActivity 0;
BA_ "Confidence" SG_ 991 UI_activeTouchPoints 0;
BA_ "Confidence" SG_ 991 UI_linkState 0;
BA_ "Confidence" SG_ 991 UI_autopilotSentryRequest 0;
BA_ "Confidence" SG_ 991 UI_mobileAppConnected 0;
BA_ "Confidence" SG_ 991 UI_autoshiftDRState 0;
BA_ "Confidence" SG_ 991 UI_wifiBtModuleType 0;
BA_ "Confidence" SG_ 991 UI_selfParkState 0;
BA_ "GenSigSNA" SG_ 991 UI_selfParkState "255";
BA_ "Confidence" SG_ 991 UI_summonDeviceIndex 0;
BA_ "Confidence" SG_ 663 UI_adaptiveRideRequest 0;
BA_ "Confidence" SG_ 663 UI_geofenceLevelingRequest 0;
BA_ "GenSigSNA" SG_ 663 UI_geofenceLevelingRequest "5";
BA_ "Confidence" SG_ 787 UI_trackModeRequest 0;
BA_ "Confidence" SG_ 787 UI_trackDrivePowerAvailability 0;
BA_ "Confidence" SG_ 839 UI_tripPlanningActive 0;
BA_ "Confidence" SG_ 839 UI_navToSupercharger 0;
BA_ "Confidence" SG_ 839 UI_navFastchargerType 0;
BA_ "Confidence" SG_ 839 UI_battPreconditionOnNavState 0;
BA_ "Confidence" SG_ 839 UI_requestActiveBatteryHeating 0;
BA_ "Confidence" SG_ 839 UI_battPreconditionOnNavPowerReq 0;
BA_ "GenSigSNA" SG_ 839 UI_battPreconditionOnNavPowerReq "127";
BA_ "Confidence" SG_ 839 UI_battPreconditionOnNavTargetT 0;
BA_ "GenSigSNA" SG_ 839 UI_battPreconditionOnNavTargetT "255";
BA_ "Confidence" SG_ 839 UI_energyAtDestination 0;
BA_ "GenSigSNA" SG_ 839 UI_energyAtDestination "32768";
BA_ "Confidence" SG_ 627 UI_powerStateRequest 0;
BA_ "Confidence" SG_ 627 UI_childDoorLockOnRight 0;
BA_ "Confidence" SG_ 627 UI_frontFogSwitch 0;
BA_ "Confidence" SG_ 627 UI_summonActive 0;
BA_ "Confidence" SG_ 627 UI_frunkRequest 0;
BA_ "Confidence" SG_ 627 UI_wiperMode 0;
BA_ "GenSigSNA" SG_ 627 UI_wiperMode "0";
BA_ "Confidence" SG_ 627 UI_steeringButtonMode 0;
BA_ "Confidence" SG_ 627 UI_walkUpUnlock 0;
BA_ "Confidence" SG_ 627 UI_walkAwayLock 0;
BA_ "Confidence" SG_ 627 UI_unlockOnPark 0;
BA_ "Confidence" SG_ 627 UI_globalUnlockOn 0;
BA_ "Confidence" SG_ 627 UI_childDoorLockOnLeft 0;
BA_ "Confidence" SG_ 627 UI_lockRequest 0;
BA_ "GenSigSNA" SG_ 627 UI_lockRequest "7";
BA_ "Confidence" SG_ 627 UI_alarmEnabled 0;
BA_ "Confidence" SG_ 627 UI_stop12vSupport 0;
BA_ "Confidence" SG_ 627 UI_rearFogSwitch 0;
BA_ "Confidence" SG_ 627 UI_mirrorFoldRequest 0;
BA_ "GenSigSNA" SG_ 627 UI_mirrorFoldRequest "3";
BA_ "Confidence" SG_ 627 UI_mirrorHeatRequest 0;
BA_ "Confidence" SG_ 627 UI_remoteStartRequest 0;
BA_ "GenSigSNA" SG_ 627 UI_remoteStartRequest "4";
BA_ "Confidence" SG_ 627 UI_seeYouHomeLightingOn 0;
BA_ "Confidence" SG_ 627 UI_powerOff 0;
BA_ "Confidence" SG_ 627 UI_displayBrightnessLevel 0;
BA_ "GenSigSNA" SG_ 627 UI_displayBrightnessLevel "255";
BA_ "Confidence" SG_ 627 UI_autoHighBeamEnabled 0;
BA_ "Confidence" SG_ 627 UI_frontLeftSeatHeatReq 0;
BA_ "Confidence" SG_ 627 UI_frontRightSeatHeatReq 0;
BA_ "Confidence" SG_ 627 UI_rearLeftSeatHeatReq 0;
BA_ "Confidence" SG_ 627 UI_rearCenterSeatHeatReq 0;
BA_ "Confidence" SG_ 627 UI_rearRightSeatHeatReq 0;
BA_ "Confidence" SG_ 627 UI_autoFoldMirrorsOn 0;
BA_ "Confidence" SG_ 627 UI_mirrorDipOnReverse 0;
BA_ "Confidence" SG_ 627 UI_remoteClosureRequest 0;
BA_ "GenSigSNA" SG_ 627 UI_remoteClosureRequest "3";
BA_ "Confidence" SG_ 627 UI_wiperRequest 0;
BA_ "GenSigSNA" SG_ 627 UI_wiperRequest "0";
BA_ "Confidence" SG_ 627 UI_domeLightSwitch 0;
BA_ "Confidence" SG_ 947 UI_gloveboxRequest 0;
BA_ "Confidence" SG_ 947 UI_trunkRequest 0;
BA_ "Confidence" SG_ 947 UI_PINToDriveEnabled 0;
BA_ "Confidence" SG_ 947 UI_PINToDrivePassed 0;
BA_ "Confidence" SG_ 947 UI_disableMirrorAutoDim 0;
BA_ "Confidence" SG_ 947 UI_lightSwitch 0;
BA_ "GenSigSNA" SG_ 947 UI_lightSwitch "4";
BA_ "Confidence" SG_ 947 UI_readyToAddKey 0;
BA_ "Confidence" SG_ 947 UI_alarmTriggerRequest 0;
BA_ "Confidence" SG_ 947 UI_displayOnForUser 0;
BA_ "Confidence" SG_ 947 UI_BLEPushNotificationRequest 0;
BA_ "Confidence" SG_ 947 UI_keepAutopilotAwake 0;
BA_ "Confidence" SG_ 947 UI_batteryPreconditioningRequest 0;
BA_ "Confidence" SG_ 947 UI_autopilotPowerStateRequest 0;
BA_ "Confidence" SG_ 947 UI_autoRollWindowsOnLockEnable 0;
BA_ "Confidence" SG_ 947 UI_steeringWheelHeatReq 0;
BA_ "Confidence" SG_ 947 UI_disableHorn 0;
BA_ "Confidence" SG_ 947 UI_frontLeftSeatFanReq 0;
BA_ "Confidence" SG_ 947 UI_frontRightSeatAutoClimateReq 0;
BA_ "Confidence" SG_ 947 UI_frontRightSeatFanReq 0;
BA_ "Confidence" SG_ 947 UI_frontLeftSeatAutoClimateReq 0;
BA_ "Confidence" SG_ 947 UI_wiperHeaterReq 0;
BA_ "Confidence" SG_ 947 UI_silentAlarm 0;
BA_ "Confidence" SG_ 660 UI_lightFlashRequest 0;
BA_ "Confidence" SG_ 660 UI_phoneCallActive 0;
BA_ "Confidence" SG_ 660 UI_lightShowClosuresEnabled 0;
BA_ "Confidence" SG_ 660 UI_steeringWheelHeatAutoReq 0;
BA_ "Confidence" SG_ 660 UI_steeringWheelHeatLevelReq 0;
BA_ "Confidence" SG_ 660 UI_headlightPulseRequest 0;
BA_ "Confidence" SG_ 660 UI_displayRedShiftActive 0;
BA_ "Confidence" SG_ 660 UI_fasciaCameraWashRequest 0;
BA_ "Confidence" SG_ 660 UI_leftRearSeatAdjustmentRequest 0;
BA_ "Confidence" SG_ 660 UI_rightRearSeatAdjustmentReques 0;
BA_ "SystemSignalLongSymbol" SG_ 660 UI_rightRearSeatAdjustmentReques "UI_rightRearSeatAdjustmentRequest";
BA_ "Confidence" SG_ 660 UI_blindSpotIndicatorLightReques 0;
BA_ "SystemSignalLongSymbol" SG_ 660 UI_blindSpotIndicatorLightReques "UI_blindSpotIndicatorLightRequest";
BA_ "Confidence" SG_ 660 UI_keepOnAccessoryPortsReq 0;
BA_ "Confidence" SG_ 660 UI_fasciaCameraShown 0;
BA_ "Confidence" SG_ 660 UI_rearSeatChildLock 0;
BA_ "Confidence" SG_ 660 UI_windowPercentageRequest 0;
BA_ "Confidence" SG_ 660 UI_windowRequestedFL 0;
BA_ "Confidence" SG_ 660 UI_windowRequestedFR 0;
BA_ "Confidence" SG_ 660 UI_windowRequestedRL 0;
BA_ "Confidence" SG_ 660 UI_windowRequestedRR 0;
BA_ "Confidence" SG_ 660 UI_windowRequest 0;
BA_ "Confidence" SG_ 660 UI_closeTrunkRequest 0;
BA_ "Confidence" SG_ 660 UI_childPresenceDetectionDisable 0;
BA_ "SystemSignalLongSymbol" SG_ 660 UI_childPresenceDetectionDisable "UI_childPresenceDetectionDisableRequest";
BA_ "Confidence" SG_ 660 UI_derivedLoadshedFeature 0;
BA_ "Confidence" SG_ 660 UI_selfParkStandingBy 0;
BA_ "Confidence" SG_ 853 UI_coolantFlowRequest 0;
BA_ "Confidence" SG_ 853 UI_inletActiveCoolTarget 0;
BA_ "Confidence" SG_ 853 UI_disableHVPTThermalLoads 0;
BA_ "Confidence" SG_ 644 UI_transportMode 0;
BA_ "Confidence" SG_ 644 UI_showroomMode 0;
BA_ "Confidence" SG_ 644 UI_serviceMode 0;
BA_ "Confidence" SG_ 644 UI_carWashMode 0;
BA_ "Confidence" SG_ 644 UI_gameMode 0;
BA_ "Confidence" SG_ 644 UI_serviceModePlus 0;
BA_ "Confidence" SG_ 644 UI_premiumAmpPowerOff 0;
BA_ "Confidence" SG_ 644 UI_lightShowType 0;
BA_ "Confidence" SG_ 595 UI_ventPanelControlRequestIndex 1;
BA_ "Confidence" SG_ 595 UI_ventPanelLeftPositionX 0;
BA_ "Confidence" SG_ 595 UI_ventPanelLeftPositionY 0;
BA_ "Confidence" SG_ 595 UI_ventPanelLeftLateralSplit 0;
BA_ "Confidence" SG_ 595 UI_ventPanelRightPositionX 0;
BA_ "Confidence" SG_ 595 UI_ventPanelRightPositionY 0;
BA_ "Confidence" SG_ 595 UI_ventPanelRightLateralSplit 0;
BA_ "Confidence" SG_ 595 UI_ventPanelLeftLateralMode 0;
BA_ "Confidence" SG_ 595 UI_ventPanelRightLateralMode 0;
BA_ "Confidence" SG_ 595 UI_hvacReqActiveVents 0;
BA_ "Confidence" SG_ 595 UI_vent2RLeftPositionX 0;
BA_ "Confidence" SG_ 595 UI_vent2RLeftPositionY 0;
BA_ "Confidence" SG_ 595 UI_vent2RRightPositionX 0;
BA_ "Confidence" SG_ 595 UI_vent2RRightPositionY 0;
BA_ "Confidence" SG_ 1285 SA_infoIndex 1;
BA_ "Confidence" SG_ 1285 SA_genealogyVersion 0;
BA_ "Confidence" SG_ 1285 SA_genealogyCrc 0;
BA_ "Confidence" SG_ 1285 SA_region 0;
BA_ "Confidence" SG_ 1285 SA_OverTempThreshold 0;
BA_ "Confidence" SG_ 1285 SA_partNumInt 0;
BA_ "Confidence" SG_ 1285 SA_partNumRev 0;
BA_ "Confidence" SG_ 1285 SA_currentLimit 0;
BA_ "Confidence" SG_ 1285 SA_l1Voltage 0;
VAL_ 516 PCS_chgMainState 9 "PCS_CHG_STATE_CLEAR_FAULTS" 8 "PCS_CHG_STATE_FAULTED" 7 "PCS_CHG_STATE_SHUTDOWN" 6 "PCS_CHG_STATE_ENABLE" 5 "PCS_CHG_STATE_SYSTEM_CONFIG" 4 "PCS_CHG_STATE_QUALIFY_LINE_CONFIG" 3 "PCS_CHG_STATE_WAIT_FOR_LINE_VOLTAGE" 2 "PCS_CHG_STATE_STARTUP" 1 "PCS_CHG_STATE_IDLE" 0 "PCS_CHG_STATE_INIT" ;
VAL_ 516 PCS_gridConfig 3 "GRID_CONFIG_THREE_PHASE_DELTA" 2 "GRID_CONFIG_THREE_PHASE" 1 "GRID_CONFIG_SINGLE_PHASE" 0 "GRID_CONFIG_SNA" ;
VAL_ 516 PCS_chgMaxAcPowerAvailable 255 "SNA" ;
VAL_ 516 PCS_hwVariantType 3 "PCS_HW_VARIANT_TYPE_SNA" 2 "PCS_THREE_PHASES_VARIANT" 1 "PCS_32A_SINGLE_PHASE_VARIANT" 0 "PCS_48A_SINGLE_PHASE_VARIANT" ;
VAL_ 548 PCS_dcdcPrechargeStatus 3 "PCS_DCDC_PRECHARGE_IMPEDANCE_CHECK" 2 "PCS_DCDC_PRECHARGE_FAULTED" 1 "PCS_DCDC_PRECHARGE_ACTIVE" 0 "PCS_DCDC_PRECHARGE_IDLE" ;
VAL_ 548 PCS_dcdcLvSupportStatus 2 "PCS_DCDC_LV_SUPPORT_FAULTED" 1 "PCS_DCDC_LV_SUPPORT_ACTIVE" 0 "PCS_DCDC_LV_SUPPORT_IDLE" ;
VAL_ 548 PCS_dcdcHvBusDischargeStatus 2 "PCS_DCDC_DIS_HVBUS_FAULTED" 1 "PCS_DCDC_DIS_HVBUS_ACTIVE" 0 "PCS_DCDC_DIS_HVBUS_IDLE" ;
VAL_ 548 PCS_dcdcSubState 18 "DCDC_SUBSTATE_NUM" 17 "DCDC_SUBSTATE_FAULTED" 16 "DCDC_SUBSTATE_CLEAR_FAULTS" 15 "DCDC_SUBSTATE_PCHG_FAULTED" 14 "DCDC_SUBSTATE_DIS_HVBUS_FAULTED" 13 "DCDC_SUBSTATE_LV_SUPPORT_FAULTED" 12 "DCDC_SUBSTATE_SHUTDOWN" 11 "DCDC_SUBSTATE_PCHG_FLT_FAST_DIS_HVBUS" 10 "DCDC_SUBSTATE_PCHG_ACTIVE" 9 "DCDC_SUBSTATE_PCHG_DI_RECOVERY_WAIT" 8 "DCDC_SUBSTATE_PCHG_DWELL_WAIT" 7 "DCDC_SUBSTATE_PCHG_DWELL_CHARGE" 6 "DCDC_SUBSTATE_PCHG_SLOW_DIS_HVBUS" 5 "DCDC_SUBSTATE_PCHG_FAST_DIS_HVBUS" 4 "DCDC_SUBSTATE_SLOW_DIS_HVBUS" 3 "DCDC_SUBSTATE_FAST_DIS_HVBUS" 2 "DCDC_SUBSTATE_LV_SUPPORT_ACTIVE" 1 "DCDC_SUBSTATE_STANDBY" 0 "DCDC_SUBSTATE_PWR_UP_INIT" ;
VAL_ 548 PCS_ecuLogUploadRequest 3 "REQUEST_PRIORITY_3" 2 "REQUEST_PRIORITY_2" 1 "REQUEST_PRIORITY_1" 0 "REQUEST_PRIORITY_NONE" ;
VAL_ 548 PCS_dcdcInitialPrechargeSubState 18 "DCDC_SUBSTATE_NUM" 17 "DCDC_SUBSTATE_FAULTED" 16 "DCDC_SUBSTATE_CLEAR_FAULTS" 15 "DCDC_SUBSTATE_PCHG_FAULTED" 14 "DCDC_SUBSTATE_DIS_HVBUS_FAULTED" 13 "DCDC_SUBSTATE_LV_SUPPORT_FAULTED" 12 "DCDC_SUBSTATE_SHUTDOWN" 11 "DCDC_SUBSTATE_PCHG_FLT_FAST_DIS_HVBUS" 10 "DCDC_SUBSTATE_PCHG_ACTIVE" 9 "DCDC_SUBSTATE_PCHG_DI_RECOVERY_WAIT" 8 "DCDC_SUBSTATE_PCHG_DWELL_WAIT" 7 "DCDC_SUBSTATE_PCHG_DWELL_CHARGE" 6 "DCDC_SUBSTATE_PCHG_SLOW_DIS_HVBUS" 5 "DCDC_SUBSTATE_PCHG_FAST_DIS_HVBUS" 4 "DCDC_SUBSTATE_SLOW_DIS_HVBUS" 3 "DCDC_SUBSTATE_FAST_DIS_HVBUS" 2 "DCDC_SUBSTATE_LV_SUPPORT_ACTIVE" 1 "DCDC_SUBSTATE_STANDBY" 0 "DCDC_SUBSTATE_PWR_UP_INIT" ;
VAL_ 964 PCS_infoIndex 255 "END" 31 "SUBCOMPONENT_GITHASH" 30 "PACKAGE_SN_8_14" 29 "PACKAGE_SN_1_7" 27 "PACKAGE_PN_15_20" 26 "PACKAGE_PN_8_14" 25 "PACKAGE_PN_1_7" 23 "SUBCOMPONENT2" 22 "VARIANTCRC" 20 "UDS_PROTOCOL_BOOTCRC" 19 "VERSION_DEPRECATED" 18 "BOOTLOADER_GITHASH" 17 "APP_GITHASH" 16 "SUBCOMPONENT" 15 "BOOTLOADER_CRC" 14 "BOOTLOADER_SVN" 13 "APP_CRC" 11 "PCBAID_ASSYID_USAGEID" 10 "BUILD_HWID_COMPONENTID" 9 "DEPRECATED_9" 8 "DEPRECATED_8" 7 "DEPRECATED_7" 6 "DEPRECATED_6" 5 "DEPRECATED_5" 4 "DEPRECATED_4" 3 "DEPRECATED_3" 2 "DEPRECATED_2" 1 "DEPRECATED_1" 0 "DEPRECATED_0" ;
VAL_ 964 PCS_buildType 4 "INFO_MFG_BUILD" 3 "INFO_TRACEABLE_CI_BUILD" 2 "INFO_LOCAL_BUILD" 1 "INFO_PLATFORM_BUILD" 0 "INFO_UNKNOWN_BUILD" ;
VAL_ 708 PCS_logMessageSelect 27 "NUM_MSGS" 26 "PROCESSOR_DIE_ID" 25 "DCDC_IMPEDANCE_EST" 24 "DCDC_HVBUS_PCHG_DATA" 23 "CHG_MACHINEMODEL" 22 "DCDC_STATISTICS" 21 "CHG_LINE_OFFSET" 20 "CHG_NO_FLOW" 19 "DCDC_5" 18 "DCDC_4" 17 "DLOG_4" 16 "DLOG_3" 15 "DLOG_2" 14 "DLOG_1" 13 "CHG_4" 12 "PHC_2" 11 "PHB_2" 10 "PHA_2" 9 "SYSTEM_1" 8 "DCDC_3" 7 "DCDC_2" 6 "DCDC_1" 5 "CHG_3" 4 "CHG_2" 3 "CHG_1" 2 "PHC_1" 1 "PHB_1" 0 "PHA_1" ;
VAL_ 708 PCS_chgPhAInputCurrentLimitReaso 5 "PCS_IAC_LIMITED_BY_PHASE_MACHINE_MODEL" 4 "PCS_IAC_LIMITED_BY_PHASE_THERMAL_LIMIT" 3 "PCS_IAC_LIMITED_BY_INPUT_POWER" 2 "PCS_IAC_LIMITED_BY_OUTPUT_POWER" 1 "PCS_IAC_LIMITED_BY_RIPPLE_RELAXED" 0 "PCS_IAC_LIMITED_BY_NONE" ;
VAL_ 708 PCS_chgPhBInputCurrentLimitReaso 5 "PCS_IAC_LIMITED_BY_PHASE_MACHINE_MODEL" 4 "PCS_IAC_LIMITED_BY_PHASE_THERMAL_LIMIT" 3 "PCS_IAC_LIMITED_BY_INPUT_POWER" 2 "PCS_IAC_LIMITED_BY_OUTPUT_POWER" 1 "PCS_IAC_LIMITED_BY_RIPPLE_RELAXED" 0 "PCS_IAC_LIMITED_BY_NONE" ;
VAL_ 708 PCS_chgPhCInputCurrentLimitReaso 5 "PCS_IAC_LIMITED_BY_PHASE_MACHINE_MODEL" 4 "PCS_IAC_LIMITED_BY_PHASE_THERMAL_LIMIT" 3 "PCS_IAC_LIMITED_BY_INPUT_POWER" 2 "PCS_IAC_LIMITED_BY_OUTPUT_POWER" 1 "PCS_IAC_LIMITED_BY_RIPPLE_RELAXED" 0 "PCS_IAC_LIMITED_BY_NONE" ;
VAL_ 708 PCS_chgInputFrequencyL1N 0 "FREQUENCY_UNKNOWN" ;
VAL_ 708 PCS_chgInputFrequencyL2N 0 "FREQUENCY_UNKNOWN" ;
VAL_ 708 PCS_chgInputFrequencyL3N 0 "FREQUENCY_UNKNOWN" ;
VAL_ 708 PCS_chgInternalPhaseConfig 9 "PHASE_CONFIG_TOTAL_NUM" 8 "PHASE_CONFIG_SINGLE_PHASE_EVSE_PARALLEL" 7 "PHASE_CONFIG_SINGLE_PHASE_BRIDGED_HARNESS" 6 "PHASE_CONFIG_MFG_TEST_CONFIG_2" 5 "PHASE_CONFIG_MFG_TEST_CONFIG_1" 4 "PHASE_CONFIG_SINGLE_PHASE_IEC_GB" 3 "PHASE_CONFIG_THREE_PHASE_DELTA" 2 "PHASE_CONFIG_THREE_PHASE" 1 "PHASE_CONFIG_SINGLE_PHASE" 0 "PHASE_CONFIG_SNA" ;
VAL_ 708 PCS_chgPhasesPriority 36 "PHASES_PRIORITY_ABC" 33 "PHASES_PRIORITY_BAC" 24 "PHASES_PRIORITY_ACB" 18 "PHASES_PRIORITY_CAB" 9 "PHASES_PRIORITY_BCA" 6 "PHASES_PRIORITY_CBA" 0 "UNDEFINED_PHASES_PRIORITY" ;
VAL_ 708 PCS_chgPhAState 6 "PCS_PH_STATE_SHUTTING_DOWN" 5 "PCS_PH_STATE_CLEAR_FAULTS" 4 "PCS_PH_STATE_FAULT" 3 "PCS_PH_STATE_ENABLE" 2 "PCS_PH_STATE_PRECHARGE" 1 "PCS_PH_STATE_IDLE" 0 "PCS_PH_STATE_INIT" ;
VAL_ 708 PCS_chgPhBState 6 "PCS_PH_STATE_SHUTTING_DOWN" 5 "PCS_PH_STATE_CLEAR_FAULTS" 4 "PCS_PH_STATE_FAULT" 3 "PCS_PH_STATE_ENABLE" 2 "PCS_PH_STATE_PRECHARGE" 1 "PCS_PH_STATE_IDLE" 0 "PCS_PH_STATE_INIT" ;
VAL_ 708 PCS_chgPhCState 6 "PCS_PH_STATE_SHUTTING_DOWN" 5 "PCS_PH_STATE_CLEAR_FAULTS" 4 "PCS_PH_STATE_FAULT" 3 "PCS_PH_STATE_ENABLE" 2 "PCS_PH_STATE_PRECHARGE" 1 "PCS_PH_STATE_IDLE" 0 "PCS_PH_STATE_INIT" ;
VAL_ 708 PCS_chgPhALastShutdownReason 17 "PCS_PH_SHUTDOWN_LINE_TRANSIENT_FAULT" 16 "PCS_PH_SHUTDOWN_FREQ_OUT_OF_RANGE" 15 "PCS_PH_SHUTDOWN_SENSOR_IRRATIONAL" 14 "PCS_PH_SHUTDOWN_TEMP_IRRATIONAL" 13 "PCS_PH_SHUTDOWN_OVER_TEMPERATURE" 12 "PCS_PH_SHUTDOWN_CONTROL_REGULATION_FAULT" 11 "PCS_PH_SHUTDOWN_INT_BUS_UV" 10 "PCS_PH_SHUTDOWN_PRECHARGE_TIMEOUT" 9 "PCS_PH_SHUTDOWN_OUTPUT_OV" 8 "PCS_PH_SHUTDOWN_OUTPUT_UV" 7 "PCS_PH_SHUTDOWN_INPUT_OV" 6 "PCS_PH_SHUTDOWN_INPUT_UV" 5 "PCS_PH_SHUTDOWN_PLL_NOT_LOCKED" 4 "PCS_PH_SHUTDOWN_HW_FAULT" 3 "PCS_PH_SHUTDOWN_SW_FAULT" 2 "PCS_PH_SHUTDOWN_HW_ENABLE" 1 "PCS_PH_SHUTDOWN_SW_ENABLE" 0 "PCS_PH_SHUTDOWN_REASON_NONE" ;
VAL_ 708 PCS_chgPhBLastShutdownReason 17 "PCS_PH_SHUTDOWN_LINE_TRANSIENT_FAULT" 16 "PCS_PH_SHUTDOWN_FREQ_OUT_OF_RANGE" 15 "PCS_PH_SHUTDOWN_SENSOR_IRRATIONAL" 14 "PCS_PH_SHUTDOWN_TEMP_IRRATIONAL" 13 "PCS_PH_SHUTDOWN_OVER_TEMPERATURE" 12 "PCS_PH_SHUTDOWN_CONTROL_REGULATION_FAULT" 11 "PCS_PH_SHUTDOWN_INT_BUS_UV" 10 "PCS_PH_SHUTDOWN_PRECHARGE_TIMEOUT" 9 "PCS_PH_SHUTDOWN_OUTPUT_OV" 8 "PCS_PH_SHUTDOWN_OUTPUT_UV" 7 "PCS_PH_SHUTDOWN_INPUT_OV" 6 "PCS_PH_SHUTDOWN_INPUT_UV" 5 "PCS_PH_SHUTDOWN_PLL_NOT_LOCKED" 4 "PCS_PH_SHUTDOWN_HW_FAULT" 3 "PCS_PH_SHUTDOWN_SW_FAULT" 2 "PCS_PH_SHUTDOWN_HW_ENABLE" 1 "PCS_PH_SHUTDOWN_SW_ENABLE" 0 "PCS_PH_SHUTDOWN_REASON_NONE" ;
VAL_ 708 PCS_chgPhCLastShutdownReason 17 "PCS_PH_SHUTDOWN_LINE_TRANSIENT_FAULT" 16 "PCS_PH_SHUTDOWN_FREQ_OUT_OF_RANGE" 15 "PCS_PH_SHUTDOWN_SENSOR_IRRATIONAL" 14 "PCS_PH_SHUTDOWN_TEMP_IRRATIONAL" 13 "PCS_PH_SHUTDOWN_OVER_TEMPERATURE" 12 "PCS_PH_SHUTDOWN_CONTROL_REGULATION_FAULT" 11 "PCS_PH_SHUTDOWN_INT_BUS_UV" 10 "PCS_PH_SHUTDOWN_PRECHARGE_TIMEOUT" 9 "PCS_PH_SHUTDOWN_OUTPUT_OV" 8 "PCS_PH_SHUTDOWN_OUTPUT_UV" 7 "PCS_PH_SHUTDOWN_INPUT_OV" 6 "PCS_PH_SHUTDOWN_INPUT_UV" 5 "PCS_PH_SHUTDOWN_PLL_NOT_LOCKED" 4 "PCS_PH_SHUTDOWN_HW_FAULT" 3 "PCS_PH_SHUTDOWN_SW_FAULT" 2 "PCS_PH_SHUTDOWN_HW_ENABLE" 1 "PCS_PH_SHUTDOWN_SW_ENABLE" 0 "PCS_PH_SHUTDOWN_REASON_NONE" ;
VAL_ 708 PCS_dcdcTankVoltage -1024 "TANK_VOLTAGE_SNA" ;
VAL_ 708 PCS_cpu2BootState 3 "CPU2_STATE_ERROR" 2 "CPU2_STATE_APPLICATION" 1 "CPU2_STATE_BOOTLOADER" 0 "CPU2_STATE_BOOTROM" ;
VAL_ 708 PCS_acChargeSelfTestState 1 "PCS_SELF_TEST_STARTED" 0 "PCS_SELF_TEST_IDLE" ;
VAL_ 708 PCS_chgAcpwHeartbeatState 4 "PCS_ACPW_HEARTBEAT_STATE_NUM" 3 "PCS_ACPW_HEARTBEAT_STATE_DETECTED_ONGRID" 2 "PCS_ACPW_HEARTBEAT_STATE_DETECTED_OFFGRID" 1 "PCS_ACPW_HEARTBEAT_STATE_NOT_DETECTED" 0 "PCS_ACPW_HEARTBEAT_STATE_UNKNOWN" ;
VAL_ 676 PCS_chgPhATemp -1023 "SNA" ;
VAL_ 676 PCS_chgPhBTemp -1023 "SNA" ;
VAL_ 676 PCS_chgPhCTemp -1023 "SNA" ;
VAL_ 676 PCS_dcdcTemp -1023 "SNA" ;
VAL_ 676 PCS_ambientTemp -1023 "SNA" ;
VAL_ 676 PCS_dcdcBusbarTemp 511 "SNA" ;
VAL_ 790 PMF_infoIndex 255 "END" 21 "DI_BUILD_DATA" 20 "UDS_PROTOCOL_BOOTCRC" 19 "VERSION_DEPRECATED" 18 "BOOTLOADER_GITHASH" 17 "APP_GITHASH" 16 "SUBCOMPONENT" 15 "BOOTLOADER_CRC" 14 "BOOTLOADER_SVN" 13 "APP_CRC" 11 "PCBAID_ASSYID_USAGEID" 10 "BUILD_HWID_COMPONENTID" 9 "DEPRECATED_9" 8 "DEPRECATED_8" 7 "DEPRECATED_7" 6 "DEPRECATED_6" 5 "DEPRECATED_5" 4 "DEPRECATED_4" 3 "DEPRECATED_3" 2 "DEPRECATED_2" 1 "DEPRECATED_1" 0 "DEPRECATED_0" ;
VAL_ 790 PMF_buildType 4 "INFO_MFG_BUILD" 3 "INFO_TRACEABLE_CI_BUILD" 2 "INFO_LOCAL_BUILD" 1 "INFO_PLATFORM_BUILD" 0 "INFO_UNKNOWN_BUILD" ;
VAL_ 790 PMF_hardwareId 252 "CONFIGURABLE_HWID_PLACEHOLDER" ;
VAL_ 1748 PMR_infoIndex 255 "END" 21 "DI_BUILD_DATA" 20 "UDS_PROTOCOL_BOOTCRC" 19 "VERSION_DEPRECATED" 18 "BOOTLOADER_GITHASH" 17 "APP_GITHASH" 16 "SUBCOMPONENT" 15 "BOOTLOADER_CRC" 14 "BOOTLOADER_SVN" 13 "APP_CRC" 11 "PCBAID_ASSYID_USAGEID" 10 "BUILD_HWID_COMPONENTID" 9 "DEPRECATED_9" 8 "DEPRECATED_8" 7 "DEPRECATED_7" 6 "DEPRECATED_6" 5 "DEPRECATED_5" 4 "DEPRECATED_4" 3 "DEPRECATED_3" 2 "DEPRECATED_2" 1 "DEPRECATED_1" 0 "DEPRECATED_0" ;
VAL_ 1748 PMR_buildType 4 "INFO_MFG_BUILD" 3 "INFO_TRACEABLE_CI_BUILD" 2 "INFO_LOCAL_BUILD" 1 "INFO_PLATFORM_BUILD" 0 "INFO_UNKNOWN_BUILD" ;
VAL_ 1748 PMR_hardwareId 252 "CONFIGURABLE_HWID_PLACEHOLDER" ;
VAL_ 1551 PM_infoIndex 255 "END" 21 "DI_BUILD_DATA" 20 "UDS_PROTOCOL_BOOTCRC" 19 "VERSION_DEPRECATED" 18 "BOOTLOADER_GITHASH" 17 "APP_GITHASH" 16 "SUBCOMPONENT" 15 "BOOTLOADER_CRC" 14 "BOOTLOADER_SVN" 13 "APP_CRC" 11 "PCBAID_ASSYID_USAGEID" 10 "BUILD_HWID_COMPONENTID" 9 "DEPRECATED_9" 8 "DEPRECATED_8" 7 "DEPRECATED_7" 6 "DEPRECATED_6" 5 "DEPRECATED_5" 4 "DEPRECATED_4" 3 "DEPRECATED_3" 2 "DEPRECATED_2" 1 "DEPRECATED_1" 0 "DEPRECATED_0" ;
VAL_ 1551 PM_buildType 4 "INFO_MFG_BUILD" 3 "INFO_TRACEABLE_CI_BUILD" 2 "INFO_LOCAL_BUILD" 1 "INFO_PLATFORM_BUILD" 0 "INFO_UNKNOWN_BUILD" ;
VAL_ 1551 PM_hardwareId 252 "CONFIGURABLE_HWID_PLACEHOLDER" ;
VAL_ 837 PTC_infoIndex 255 "END" 31 "SUBCOMPONENT_GITHASH" 30 "PACKAGE_SN_8_14" 29 "PACKAGE_SN_1_7" 27 "PACKAGE_PN_15_20" 26 "PACKAGE_PN_8_14" 25 "PACKAGE_PN_1_7" 23 "SUBCOMPONENT2" 22 "VARIANTCRC" 20 "UDS_PROTOCOL_BOOTCRC" 19 "VERSION_DEPRECATED" 18 "BOOTLOADER_GITHASH" 17 "APP_GITHASH" 16 "SUBCOMPONENT" 15 "BOOTLOADER_CRC" 14 "BOOTLOADER_SVN" 13 "APP_CRC" 11 "PCBAID_ASSYID_USAGEID" 10 "BUILD_HWID_COMPONENTID" 9 "DEPRECATED_9" 8 "DEPRECATED_8" 7 "DEPRECATED_7" 6 "DEPRECATED_6" 5 "DEPRECATED_5" 4 "DEPRECATED_4" 3 "DEPRECATED_3" 2 "DEPRECATED_2" 1 "DEPRECATED_1" 0 "DEPRECATED_0" ;
VAL_ 837 PTC_infoBuildType 4 "INFO_MFG_BUILD" 3 "INFO_TRACEABLE_CI_BUILD" 2 "INFO_LOCAL_BUILD" 1 "INFO_PLATFORM_BUILD" 0 "INFO_UNKNOWN_BUILD" ;
VAL_ 837 PTC_infoAssemblyId 255 "ASSEMBLY_SNA" 1 "ASSEMBLY1" ;
VAL_ 816 SCCM_infoIndex 255 "END" 20 "UDS_PROTOCOL_BOOTCRC" 18 "BOOTLOADER_SVNHASH" 17 "APP_SVNHASH" 16 "SUBCOMPONENT1" 14 "BOOTLOADER_SVN" 13 "APP_CRC" 11 "PCBAID_ASSYID_USAGEID" 10 "BUILD_HWID_COMPONENTID" ;
VAL_ 816 SCCM_infoBuildType 4 "INFO_MFG_BUILD" 3 "INFO_TRACEABLE_CI_BUILD" 2 "INFO_LOCAL_BUILD" 1 "INFO_PLATFORM_BUILD" 0 "INFO_UNKNOWN_BUILD" ;
VAL_ 585 SCCM_highBeamStalkStatus 3 "SNA" 2 "PUSH" 1 "PULL" 0 "IDLE" ;
VAL_ 585 SCCM_washWipeButtonStatus 3 "SNA" 2 "2ND_DETENT" 1 "1ST_DETENT" 0 "NOT_PRESSED" ;
VAL_ 585 SCCM_turnIndicatorStalkStatus 9 "SNA" 8 "DOWN_2" 7 "DOWN_1_5" 6 "DOWN_1" 5 "DOWN_0_5" 4 "UP_2" 3 "UP_1_5" 2 "UP_1" 1 "UP_0_5" 0 "IDLE" ;
VAL_ 585 SCCM_turnIndicatorStalkAngle 4095 "SNA" ;
VAL_ 553 SCCM_rightStalkStatus 6 "SNA" 5 "INIT" 4 "DOWN_2" 3 "DOWN_1" 2 "UP_2" 1 "UP_1" 0 "IDLE" ;
VAL_ 553 SCCM_parkButtonStatus 3 "SNA" 2 "INIT" 1 "PRESSED" 0 "NOT_PRESSED" ;
VAL_ 297 SCCM_steeringAngleSensorStatus 3 "ERROR_INIT" 2 "ERROR" 1 "INIT" 0 "OK" ;
VAL_ 297 SCCM_steeringAngle 16383 "SNA" ;
VAL_ 297 SCCM_steeringAngleValidity 3 "SNA" 2 "INIT" 1 "VALID" 0 "INVALID" ;
VAL_ 1597 SDCR_infoIndex 255 "END" 41 "SUBCOMPONENT14" 40 "SUBCOMPONENT13" 39 "SUBCOMPONENT12" 38 "SUBCOMPONENT11" 37 "SUBCOMPONENT10" 36 "SUBCOMPONENT9" 35 "SUBCOMPONENT8" 34 "SUBCOMPONENT7" 33 "SUBCOMPONENT6" 32 "SUBCOMPONENT5" 31 "SUBCOMPONENT4" 24 "SUBCOMPONENT3" 23 "SUBCOMPONENT2" 20 "UDS_PROTOCOL_BOOTCRC" 19 "VERSION_DEPRECATED" 18 "BOOTLOADER_GITHASH" 17 "APP_GITHASH" 16 "SUBCOMPONENT1" 15 "BOOTLOADER_CRC" 14 "BOOTLOADER_SVN" 13 "APP_CRC" 11 "PCBAID_ASSYID_USAGEID" 10 "BUILD_HWID_COMPONENTID" 9 "DEPRECATED_9" 8 "DEPRECATED_8" 7 "DEPRECATED_7" 6 "DEPRECATED_6" 5 "DEPRECATED_5" 4 "DEPRECATED_4" 3 "DEPRECATED_3" 2 "DEPRECATED_2" 1 "DEPRECATED_1" 0 "DEPRECATED_0" ;
VAL_ 1597 SDCR_infoBuildType 4 "INFO_MFG_BUILD" 3 "INFO_TRACEABLE_CI_BUILD" 2 "INFO_LOCAL_BUILD" 1 "INFO_PLATFORM_BUILD" 0 "INFO_UNKNOWN_BUILD" ;
VAL_ 523 TAS_axleIndex 1 "axleRear" 0 "axleFront" ;
VAL_ 523 TAS_rawHeightFL 1023 "SNA" ;
VAL_ 523 TAS_staticHeightEstimateFL 1023 "SNA" ;
VAL_ 523 TAS_componentPressureFL 255 "SNA" ;
VAL_ 523 TAS_rawHeightFR 1023 "SNA" ;
VAL_ 523 TAS_staticHeightEstimateFR 1023 "SNA" ;
VAL_ 523 TAS_componentPressureFR 255 "SNA" ;
VAL_ 523 TAS_rawHeightRL 1023 "SNA" ;
VAL_ 523 TAS_staticHeightEstimateRL 1023 "SNA" ;
VAL_ 523 TAS_componentPressureRL 255 "SNA" ;
VAL_ 523 TAS_rawHeightRR 1023 "SNA" ;
VAL_ 523 TAS_staticHeightEstimateRR 1023 "SNA" ;
VAL_ 523 TAS_componentPressureRR 255 "SNA" ;
VAL_ 1398 TAS_endstopState 1 "TAS_DAMPING_STATE_ACTIVE" 0 "TAS_DAMPING_STATE_STANDBY" ;
VAL_ 1398 TAS_continuousControlState 1 "TAS_DAMPING_STATE_ACTIVE" 0 "TAS_DAMPING_STATE_STANDBY" ;
VAL_ 1398 TAS_activeTireTune 1 "TAS_TIRE_TUNE_MICHELIN_SUMMER_21" 0 "TAS_TIRE_TUNE_DEFAULT" ;
VAL_ 1398 TAS_roughnessRaiseReason 2 "TAS_ROUGHNESS_RAISE_REASON_LOOKAHEAD" 1 "TAS_ROUGHNESS_RAISE_REASON_LEGACY" 0 "TAS_ROUGHNESS_RAISE_REASON_NONE" ;
VAL_ 1398 TAS_frontMetricDrivesRear 3 "TAS_ACTION_ACTIVE" 2 "TAS_ACTION_ARMED" 1 "TAS_ACTION_STANDBY" 0 "TAS_ACTION_DISABLED" ;
VAL_ 1398 TAS_roadCondition 255 "SNA" ;
VAL_ 1398 TAS_bellyProtect 3 "TAS_ACTION_ACTIVE" 2 "TAS_ACTION_ARMED" 1 "TAS_ACTION_STANDBY" 0 "TAS_ACTION_DISABLED" ;
VAL_ 1398 TAS_frontMetricDrivesFront 3 "TAS_ACTION_ACTIVE" 2 "TAS_ACTION_ARMED" 1 "TAS_ACTION_STANDBY" 0 "TAS_ACTION_DISABLED" ;
VAL_ 1398 TAS_speedBumpAxleFront 4 "TAS_ACTION_CANCELED" 3 "TAS_ACTION_ACTIVE" 2 "TAS_ACTION_ARMED" 1 "TAS_ACTION_STANDBY" 0 "TAS_ACTION_DISABLED" ;
VAL_ 1398 TAS_speedBumpAxleRear 4 "TAS_ACTION_CANCELED" 3 "TAS_ACTION_ACTIVE" 2 "TAS_ACTION_ARMED" 1 "TAS_ACTION_STANDBY" 0 "TAS_ACTION_DISABLED" ;
VAL_ 1398 TAS_holeProtectFL 3 "TAS_ACTION_ACTIVE" 2 "TAS_ACTION_ARMED" 1 "TAS_ACTION_STANDBY" 0 "TAS_ACTION_DISABLED" ;
VAL_ 1398 TAS_holeProtectFR 3 "TAS_ACTION_ACTIVE" 2 "TAS_ACTION_ARMED" 1 "TAS_ACTION_STANDBY" 0 "TAS_ACTION_DISABLED" ;
VAL_ 1398 TAS_holeProtectRL 3 "TAS_ACTION_ACTIVE" 2 "TAS_ACTION_ARMED" 1 "TAS_ACTION_STANDBY" 0 "TAS_ACTION_DISABLED" ;
VAL_ 1398 TAS_holeProtectRR 3 "TAS_ACTION_ACTIVE" 2 "TAS_ACTION_ARMED" 1 "TAS_ACTION_STANDBY" 0 "TAS_ACTION_DISABLED" ;
VAL_ 1398 TAS_stepProtectFL 3 "TAS_ACTION_ACTIVE" 2 "TAS_ACTION_ARMED" 1 "TAS_ACTION_STANDBY" 0 "TAS_ACTION_DISABLED" ;
VAL_ 1398 TAS_stepProtectFR 3 "TAS_ACTION_ACTIVE" 2 "TAS_ACTION_ARMED" 1 "TAS_ACTION_STANDBY" 0 "TAS_ACTION_DISABLED" ;
VAL_ 1398 TAS_stepProtectRL 3 "TAS_ACTION_ACTIVE" 2 "TAS_ACTION_ARMED" 1 "TAS_ACTION_STANDBY" 0 "TAS_ACTION_DISABLED" ;
VAL_ 1398 TAS_stepProtectRR 3 "TAS_ACTION_ACTIVE" 2 "TAS_ACTION_ARMED" 1 "TAS_ACTION_STANDBY" 0 "TAS_ACTION_DISABLED" ;
VAL_ 1398 TAS_FDUTorqueCorruptionScale 15 "SNA" ;
VAL_ 1398 TAS_sprungMassEstimate 31 "SNA" ;
VAL_ 1357 TAS_infoIndex 255 "END" 41 "SUBCOMPONENT14" 40 "SUBCOMPONENT13" 39 "SUBCOMPONENT12" 38 "SUBCOMPONENT11" 37 "SUBCOMPONENT10" 36 "SUBCOMPONENT9" 35 "SUBCOMPONENT8" 34 "SUBCOMPONENT7" 33 "SUBCOMPONENT6" 32 "SUBCOMPONENT5" 31 "SUBCOMPONENT4" 24 "SUBCOMPONENT3" 23 "SUBCOMPONENT2" 20 "UDS_PROTOCOL_BOOTCRC" 19 "VERSION_DEPRECATED" 18 "BOOTLOADER_GITHASH" 17 "APP_GITHASH" 16 "SUBCOMPONENT1" 15 "BOOTLOADER_CRC" 14 "BOOTLOADER_SVN" 13 "APP_CRC" 11 "PCBAID_ASSYID_USAGEID" 10 "BUILD_HWID_COMPONENTID" 9 "DEPRECATED_9" 8 "DEPRECATED_8" 7 "DEPRECATED_7" 6 "DEPRECATED_6" 5 "DEPRECATED_5" 4 "DEPRECATED_4" 3 "DEPRECATED_3" 2 "DEPRECATED_2" 1 "DEPRECATED_1" 0 "DEPRECATED_0" ;
VAL_ 1357 TAS_infoBuildType 4 "INFO_MFG_BUILD" 3 "INFO_TRACEABLE_CI_BUILD" 2 "INFO_LOCAL_BUILD" 1 "INFO_PLATFORM_BUILD" 0 "INFO_UNKNOWN_BUILD" ;
VAL_ 1357 TAS_infoAssemblyId 255 "ASSEMBLY_SNA" 1 "ASSEMBLY1" ;
VAL_ 1357 TAS_infoMajorVersion 255 "SNA" 254 "LOCAL_BUILD" ;
VAL_ 1357 TAS_infoBranchOrigin 255 "SNA" 254 "LOCAL_BUILD" ;
VAL_ 1357 TAS_infoMaturity 255 "SNA" 254 "LOCAL_BUILD" ;
VAL_ 1357 TAS_infoHardwareRevision 255 "SNA" 254 "LOCAL_BUILD" ;
VAL_ 525 TAS_levelingState 15 "LEVELING_STATE_CROSSLINK" 14 "LEVELING_STATE_QUIET_EXHAUST" 13 "LEVELING_STATE_EXHAUST_RESERVOIR" 12 "LEVELING_STATE_LOWER_SPRING_WITH_COMPRESSOR" 11 "LEVELING_STATE_LOWER_SPRING" 10 "LEVELING_STATE_FILL_SPRING_RESERVOIR_FROM_COMPRESSOR" 9 "LEVELING_STATE_FILL_SPRING_FROM_RESERVOIR" 8 "LEVELING_STATE_FILL_SPRING_FROM_BOOST" 7 "LEVELING_STATE_FILL_SPRING_FROM_COMPRESSOR" 6 "LEVELING_STATE_FILL_RESERVOIR_FROM_COMPRESSOR" 5 "LEVELING_STATE_COMPRESSOR_PREFILL_GALLERY" 4 "LEVELING_STATE_COMPRESSOR_RAMPUP" 3 "LEVELING_STATE_EXHAUST_GALLERY" 2 "LEVELING_STATE_MEASURE_SPRING_PRESSURE" 1 "LEVELING_STATE_READ_P_RESERVOIR" 0 "LEVELING_STATE_IDLE" ;
VAL_ 525 TAS_levelingItem 7 "TAS_LEVELING_ITEM_ALL" 6 "TAS_LEVELING_ITEM_REAR_AXLE" 5 "TAS_LEVELING_ITEM_FRONT_AXLE" 4 "TAS_LEVELING_ITEM_RR" 3 "TAS_LEVELING_ITEM_RL" 2 "TAS_LEVELING_ITEM_FR" 1 "TAS_LEVELING_ITEM_FL" 0 "TAS_LEVELING_ITEM_NONE" ;
VAL_ 525 TAS_pressureGallery 255 "SNA" ;
VAL_ 525 TAS_pressureReservoir 255 "SNA" ;
VAL_ 525 TAS_runMode 7 "RUN_MODE_DYNO" 6 "RUN_MODE_LOW_POWER" 5 "RUN_MODE_NORMAL" 4 "RUN_MODE_DAN" 3 "RUN_MODE_ASSEMBLY" 2 "RUN_MODE_SERVICE" 1 "RUN_MODE_SYSTEM_CHECK" 0 "RUN_MODE_INIT" ;
VAL_ 525 TAS_filterMode 7 "MODE_STOPPING" 6 "MODE_DRIVE" 5 "MODE_LOADING" 4 "MODE_READY" 3 "MODE_TEST" 2 "MODE_CALIBRATE" 1 "MODE_INIT" 0 "MODE_NONE" ;
VAL_ 525 TAS_limpHomeMode 4 "LIMP_HOME_MODE_40" 3 "LIMP_HOME_MODE_30" 2 "LIMP_HOME_MODE_20" 1 "LIMP_HOME_MODE_10" 0 "LIMP_HOME_MODE_0" ;
VAL_ 525 TAS_targetLevel 4 "TAS_VERY_LOW" 3 "TAS_LOW" 2 "TAS_STANDARD" 1 "TAS_HIGH" 0 "TAS_VERY_HIGH" ;
VAL_ 525 TAS_currentLevel 4 "TAS_VERY_LOW" 3 "TAS_LOW" 2 "TAS_STANDARD" 1 "TAS_HIGH" 0 "TAS_VERY_HIGH" ;
VAL_ 409 TAS_adaptiveActivityFL_C 31 "SNA" ;
VAL_ 409 TAS_adaptiveActivityFL_R 31 "SNA" ;
VAL_ 409 TAS_adaptiveActivityFR_C 31 "SNA" ;
VAL_ 409 TAS_adaptiveActivityFR_R 31 "SNA" ;
VAL_ 409 TAS_adaptiveActivityRL_C 31 "SNA" ;
VAL_ 409 TAS_adaptiveActivityRL_R 31 "SNA" ;
VAL_ 409 TAS_adaptiveActivityRR_C 31 "SNA" ;
VAL_ 409 TAS_adaptiveActivityRR_R 31 "SNA" ;
VAL_ 409 TAS_uiHeightFL 63 "SNA" ;
VAL_ 409 TAS_uiHeightFR 63 "SNA" ;
VAL_ 409 TAS_uiHeightRL 63 "SNA" ;
VAL_ 409 TAS_uiHeightRR 63 "SNA" ;
VAL_ 410 TAS_bodyAccelFL 255 "SNA" ;
VAL_ 410 TAS_bodyAccelFR 255 "SNA" ;
VAL_ 410 TAS_bodyAccelRL 255 "SNA" ;
VAL_ 410 TAS_bodyAccelRR 255 "SNA" ;
VAL_ 538 TAS_adaptiveRideModeOverride 3 "TAS_ADAPTIVE_RIDE_MODE_SNA" 2 "TAS_ADAPTIVE_RIDE_MODE_SPORT" 1 "TAS_ADAPTIVE_RIDE_MODE_AUTO" 0 "TAS_ADAPTIVE_RIDE_MODE_COMFORT" ;
VAL_ 538 TAS_launchModeState 4 "TAS_LAUNCH_MODE_STATE_RAISE_SUSPENSION" 3 "TAS_LAUNCH_MODE_STATE_READY" 2 "TAS_LAUNCH_MODE_STATE_LOWER_SUSPENSION" 1 "TAS_LAUNCH_MODE_STATE_IDLE" 0 "TAS_LAUNCH_MODE_STATE_BLOCKED" ;
VAL_ 1657 UI_rgbEnableState 2 "AUTO" 1 "ON" 0 "OFF" ;
VAL_ 1657 UI_rgbEffectType 20 "RAMP_5000MS" 19 "RAMP_4750MS" 18 "RAMP_4500MS" 17 "RAMP_4250MS" 16 "RAMP_4000MS" 15 "RAMP_3750MS" 14 "RAMP_3500MS" 13 "RAMP_3250MS" 12 "RAMP_3000MS" 11 "RAMP_2750MS" 10 "RAMP_2500MS" 9 "RAMP_2250MS" 8 "RAMP_2000MS" 7 "RAMP_1750MS" 6 "RAMP_1500MS" 5 "RAMP_1250MS" 4 "RAMP_1000MS" 3 "RAMP_750MS" 2 "RAMP_500MS" 1 "RAMP_250MS" 0 "RAMP_INSTANT" ;
VAL_ 1657 UI_rgbBrightnessLevel 127 "SNA" ;
VAL_ 1021 UI_autopilotControlIndex 7 "7" 6 "6" 5 "5" 4 "4" 3 "3" 2 "2" 1 "1" 0 "0" ;
VAL_ 1021 UI_hovEnabled 1 "HOV_ON" 0 "HOV_OFF" ;
VAL_ 1021 UI_smartSetSpeedOffsetType 1 "PERCENTAGE_OFFSET" 0 "FIXED_OFFSET" ;
VAL_ 1021 UI_autosteerActivation 1 "DOUBLE_CLICK" 0 "SINGLE_CLICK" ;
VAL_ 1021 UI_autopilotDrivingProfile 3 "MAD_MAX" 2 "ASSERTIVE" 1 "NORMAL" 0 "CHILL" ;
VAL_ 1021 UI_fsdBetaRequest 1 "FSD_REQUEST_ACTIVE" 0 "FSD_REQUEST_NOT_ACTIVE" ;
VAL_ 1021 UI_selectableCameraRequest 15 "SNA" 13 "REPEATERS_BACKUP" 12 "FASCIA" 11 "GRID_VIEW" 10 "OCTA" 9 "BACKUP" 8 "RIGHT_REPEATER" 7 "RIGHT_PILLAR" 6 "LEFT_REPEATER" 5 "LEFT_PILLAR" 4 "FRONT_NARROW" 3 "FRONT_FISHEYE" 2 "FRONT_MAIN" 1 "SELFIE" 0 "NONE" ;
VAL_ 1021 UI_autoTurnSignalMode 1 "UI_AUTO_TURN_SIGNAL_MODE_AUTO_CANCEL" 0 "UI_AUTO_TURN_SIGNAL_MODE_OFF" ;
VAL_ 819 UI_acChargeCurrentLimit 127 "SNA" ;
VAL_ 819 UI_chargePortLatchRequest 2 "UI_LATCH_REQUEST_DISENGAGE" 1 "UI_LATCH_REQUEST_ENGAGE" 0 "UI_LATCH_REQUEST_NONE" ;
VAL_ 819 UI_cpInletHeaterRequest 2 "HEATER_MANUAL_OVERRIDE" 1 "HEATER_AUTO" 0 "HEATER_OFF" ;
VAL_ 659 UI_steeringTuneRequest 2 "STEERING_TUNE_SPORT" 1 "STEERING_TUNE_STANDARD" 0 "STEERING_TUNE_COMFORT" ;
VAL_ 659 UI_tractionControlMode 7 "TC_SLIPPERY_SURFACE_SELECTED" 6 "TC_OFFROAD_ASSIST_SELECTED" 5 "TC_DYNO_MODE_SELECTED" 4 "TC_ROLLS_MODE_SELECTED" 3 "TC_DEV_MODE_2_SELECTED" 2 "TC_DEV_MODE_1_SELECTED" 1 "TC_SLIP_START_SELECTED" 0 "TC_NORMAL_SELECTED" ;
VAL_ 659 UI_parkBrakeRequest 3 "PARK_BRAKE_REQUEST_SNA" 1 "PARK_BRAKE_REQUEST_PRESSED" 0 "PARK_BRAKE_REQUEST_IDLE" ;
VAL_ 659 UI_winchModeRequest 3 "WINCH_MODE_DIALOGUE_OPEN" 2 "WINCH_MODE_EXIT" 1 "WINCH_MODE_ENTER" 0 "WINCH_MODE_IDLE" ;
VAL_ 659 UI_trailerMode 1 "TRAILER_MODE_ON" 0 "TRAILER_MODE_OFF" ;
VAL_ 659 UI_accOvertakeEnable 3 "SNA" 1 "ACC_OVERTAKE_ON" 0 "ACC_OVERTAKE_OFF" ;
VAL_ 659 UI_aebEnable 3 "SNA" 1 "AEB_ON" 0 "AEB_OFF" ;
VAL_ 659 UI_aesEnable 3 "SNA" 1 "AES_ON" 0 "AES_OFF" ;
VAL_ 659 UI_ahlbEnable 3 "SNA" 1 "AHLB_ON" 0 "AHLB_OFF" ;
VAL_ 659 UI_autoLaneChangeEnable 3 "SNA" 1 "ON" 0 "OFF" ;
VAL_ 659 UI_autoParkRequest 15 "SNA" 12 "BEGIN_PARKING" 11 "RESUME" 10 "PAUSE" 9 "SEARCH" 8 "COMPLETE" 7 "ABORT" 6 "PARALLEL_PULL_OUT_TO_RIGHT" 5 "PARALLEL_PULL_OUT_TO_LEFT" 4 "PARK_RIGHT_CROSS" 3 "PARK_RIGHT_PARALLEL" 2 "PARK_LEFT_CROSS" 1 "PARK_LEFT_PARALLEL" 0 "NONE" ;
VAL_ 659 UI_bsdEnable 3 "SNA" 1 "BSD_ON" 0 "BSD_OFF" ;
VAL_ 659 UI_fcwEnable 3 "SNA" 1 "FCW_ON" 0 "FCW_OFF" ;
VAL_ 659 UI_fcwSensitivity 3 "SNA" 2 "AEB_SENSITIVITY_LATE" 1 "AEB_SENSITIVITY_AVERAGE" 0 "AEB_SENSITIVITY_EARLY" ;
VAL_ 659 UI_latControlEnable 3 "LATERAL_CONTROL_SNA" 2 "LATERAL_CONTROL_UNAVAILABLE" 1 "LATERAL_CONTROL_ON" 0 "LATERAL_CONTROL_OFF" ;
VAL_ 659 UI_ldwEnable 3 "SNA" 1 "LDW_TRIGGERS_HAPTIC" 0 "NO_HAPTIC" ;
VAL_ 531 UI_cruiseSpeedCommand 6 "CRUISE_SPEED_SNAP_SPEEDO" 5 "CRUISE_SPEED_SNAP" 4 "CRUISE_SPEED_DEC_LONG" 3 "CRUISE_SPEED_DEC_SHORT" 2 "CRUISE_SPEED_INC_LONG" 1 "CRUISE_SPEED_INC_SHORT" 0 "CRUISE_SPEED_IDLE" ;
VAL_ 568 UI_roadClass 6 "CLASS_6_MINOR" 5 "CLASS_5" 4 "CLASS_4" 3 "CLASS_3" 2 "CLASS_2" 1 "CLASS_1_MAJOR" 0 "UNKNOWN_INVALID_SNA" ;
VAL_ 645 UI_driverProfileRecallIndex 5 "5" 4 "4" 3 "3" 2 "2" 1 "1" 0 "SNA" ;
VAL_ 645 UI_modifyMirrorDipRequest 2 "MODIFY_MIRROR_DIP_REQUEST_DIPPED" 1 "MODIFY_MIRROR_DIP_REQUEST_UNDIPPED" 0 "MODIFY_MIRROR_DIP_REQUEST_NONE" ;
VAL_ 651 UI_driverProfileSelectionType 3 "DRIVER_PROFILE_SELECTION_TYPE_NONE" 2 "DRIVER_PROFILE_SELECTION_TYPE_AUTOMATIC_NO_OP" 1 "DRIVER_PROFILE_SELECTION_TYPE_AUTOMATIC_RESTORE" 0 "DRIVER_PROFILE_SELECTION_TYPE_MANUAL" ;
VAL_ 1139 UI_nmKeepAwakeReason 31 "UI_KEEPAWAKE_REASON_AUTO_CONDITIONING_START" 30 "UI_KEEPAWAKE_REASON_WINDOW_CONTROL" 29 "UI_KEEPAWAKE_REASON_GET_VEHICLE_CONFIGURATION" 28 "UI_KEEPAWAKE_REASON_MOTHERSHIP_SMS_OWNER_WAKE_UP" 27 "UI_KEEPAWAKE_REASON_MOTHERSHIP_SMS_GARAGE_WAKE_UP" 26 "UI_KEEPAWAKE_REASON_MOTHERSHIP_SMS_VEHICLE_TASK" 25 "UI_KEEPAWAKE_REASON_MOTHERSHIP_SMS_YOUVE_GOT_MAIL" 24 "UI_KEEPAWAKE_REASON_WAKE_UP" 23 "UI_KEEPAWAKE_REASON_FIRMWARE_HANDSHAKE" 22 "UI_KEEPAWAKE_REASON_VEHICLE_DATA" 21 "UI_KEEPAWAKE_REASON_DIAG_VITALS" 20 "UI_KEEPAWAKE_REASON_URGENT_UPLOAD" 19 "UI_KEEPAWAKE_REASON_UI_REQUEST_AP_KEEPALIVE" 18 "UI_KEEPAWAKE_REASON_STEAM" 17 "UI_KEEPAWAKE_REASON_CHARGING" 16 "UI_KEEPAWAKE_REASON_UI_HVAC_REQUEST" 15 "UI_KEEPAWAKE_REASON_USER_NOTIFICATION_TIMER" 14 "UI_KEEPAWAKE_REASON_ODIN" 13 "UI_KEEPAWAKE_REASON_MEDIA_DOWNLOAD" 12 "UI_KEEPAWAKE_REASON_SENTRY_MODE" 11 "UI_KEEPAWAKE_REASON_SELFTEST" 10 "UI_KEEPAWAKE_REASON_ECALL_ACTIVE" 9 "UI_KEEPAWAKE_REASON_UPDATE_COUNTDOWN" 8 "UI_KEEPAWAKE_REASON_AUTOFUSER" 7 "UI_KEEPAWAKE_REASON_HERMES" 6 "UI_KEEPAWAKE_REASON_UPDATER" 5 "UI_KEEPAWAKE_REASON_MODEM_RESET" 4 "UI_KEEPAWAKE_REASON_UNKNOWN_REMOTE_REQUEST" 3 "UI_KEEPAWAKE_REASON_PM_CHECKING" 2 "UI_KEEPAWAKE_REASON_GUI_NEVER_SLEEP_SET" 1 "UI_KEEPAWAKE_REASON_KEEPALIVEACTIVE" 0 "UI_KEEPAWAKE_REASON_NONE_SNA" ;
VAL_ 883 UI_mapSpeedLimitUnits 1 "KPH" 0 "MPH" ;
VAL_ 883 UI_conditionalSpeedLimit 31 "SNA" ;
VAL_ 755 UI_hvacReqTempSetpointLeft 26 "HI" 0 "LO" ;
VAL_ 755 UI_hvacReqAutoBlowerLevel 4 "VERY_HIGH" 3 "HIGH" 2 "MEDIUM" 1 "LOW" 0 "VERY_LOW" ;
VAL_ 755 UI_hvacReqTempSetpointRight 26 "HI" 0 "LO" ;
VAL_ 755 UI_hvacReqAirDistributionMode 7 "MANUAL_DEFROST_PANEL_FLOOR" 6 "MANUAL_DEFROST_PANEL" 5 "MANUAL_DEFROST_FLOOR" 4 "MANUAL_DEFROST" 3 "MANUAL_PANEL_FLOOR" 2 "MANUAL_PANEL" 1 "MANUAL_FLOOR" 0 "AUTO" ;
VAL_ 755 UI_hvacReqBlowerSegment 11 "AUTO" 10 "10" 9 "9" 8 "8" 7 "7" 6 "6" 5 "5" 4 "4" 3 "3" 2 "2" 1 "1" 0 "OFF" ;
VAL_ 755 UI_hvacReqRecirc 2 "FRESH" 1 "RECIRC" 0 "AUTO" ;
VAL_ 755 UI_hvacReqACDisable 2 "ON" 1 "OFF" 0 "AUTO" ;
VAL_ 755 UI_hvacDefogState 3 "AUTO_DEFOG" 2 "DEFROST" 1 "DEFOG" 0 "NONE" ;
VAL_ 755 UI_hvacReqUserPowerState 4 "OVERHEAT_PROTECT" 3 "OVERHEAT_PROTECT_FANONLY" 2 "PRECONDITION" 1 "ON" 0 "OFF" ;
VAL_ 755 UI_hvacReqSecondRowState 4 "HIGH" 3 "MED" 2 "LOW" 1 "OFF" 0 "AUTO" ;
VAL_ 755 UI_hvacReqKeepClimateOn 3 "KEEP_CLIMATE_ON_REQ_PARTY" 2 "KEEP_CLIMATE_ON_REQ_DOG" 1 "KEEP_CLIMATE_ON_REQ_ON" 0 "KEEP_CLIMATE_ON_REQ_OFF" ;
VAL_ 755 UI_hvacReqTempSetpointCOP 2 "HIGH" 1 "MEDIUM" 0 "LOW" ;
VAL_ 1523 UI_odometer 16777215 "SNA" ;
VAL_ 948 UI_usbFrontHubPowerStateRequest 2 "POWER_ON" 1 "POWER_NO_PREFERENCE" 0 "POWER_REQUEST_SNA" ;
VAL_ 827 UI_chargeTimeUntilTerminationPct 2047 "SNA" 1440 "MAXVAL" ;
VAL_ 827 UI_chargeTimeUntilReadyToDepart 2047 "SNA" 1440 "MAXVAL" ;
VAL_ 820 UI_pedalMap 2 "PERFORMANCE" 1 "SPORT" 0 "CHILL" ;
VAL_ 820 UI_limitMode 3 "LIMIT_SERVICE" 2 "LIMIT_FACTORY" 1 "LIMIT_VALET" 0 "LIMIT_NORMAL" ;
VAL_ 820 UI_motorOnMode 2 "MOTORONMODE_REAR_ONLY" 1 "MOTORONMODE_FRONT_ONLY" 0 "MOTORONMODE_NORMAL" ;
VAL_ 820 UI_stoppingMode 2 "HOLD" 1 "CREEP" 0 "STANDARD" ;
VAL_ 820 UI_speedLimit 511 "SNA" ;
VAL_ 820 UI_enableSmartShift 2 "ENABLED_P_R_D" 1 "ENABLED_P" 0 "OFF" ;
VAL_ 820 UI_navVehParallelToRdCanContinue 2 "TRUE" 1 "FALSE" 0 "SNA" ;
VAL_ 723 UI_isSunUp 3 "SUN_SNA" 1 "SUN_UP" 0 "SUN_DOWN" ;
VAL_ 723 UI_solarElevationAngle 127 "SNA" ;
VAL_ 851 UI_factoryReset 3 "CUSTOMER" 2 "DIAGNOSTIC" 1 "DEVELOPER" 0 "NONE_SNA" ;
VAL_ 851 UI_cellNetworkTechnology 15 "CELL_NETWORK_SNA" 14 "CELL_NETWORK_NGRAN" 13 "CELL_NETWORK_5GSA" 12 "CELL_NETWORK_5GNSA" 11 "CELL_NETWORK_LTE5GCN" 10 "CELL_NETWORK_WCDMA" 9 "CELL_NETWORK_CDMA" 8 "CELL_NETWORK_GSM" 7 "CELL_NETWORK_LTE" 6 "CELL_NETWORK_HSPA" 5 "CELL_NETWORK_HSUPA" 4 "CELL_NETWORK_HSDPA" 3 "CELL_NETWORK_UMTS" 2 "CELL_NETWORK_EDGE" 1 "CELL_NETWORK_GPRS" 0 "CELL_NETWORK_NONE" ;
VAL_ 851 UI_cellSignalBars 7 "SNA" 5 "FIVE" 4 "FOUR" 3 "THREE" 2 "TWO" 1 "ONE" 0 "ZERO" ;
VAL_ 851 UI_trailerModeTelltale 3 "TRAILER_MODE_TELLTALE_RED" 2 "TRAILER_MODE_TELLTALE_YELLOW" 1 "TRAILER_MODE_TELLTALE_BLUE" 0 "TRAILER_MODE_TELLTALE_OFF" ;
VAL_ 991 UI_userActivity 1 "USER_ACTIVE" 0 "USER_IDLE" ;
VAL_ 991 UI_linkState 2 "LINK_STATE_WIFI" 1 "LINK_STATE_CELL" 0 "LINK_STATE_NONE" ;
VAL_ 991 UI_mobileAppConnected 1 "CONNECTED" 0 "NOT_CONNECTED" ;
VAL_ 991 UI_autoshiftDRState 6 "AUTOSHIFT_DR_STATE_BRAKE_GEAR_SHIFT_CONFIRMED_D" 5 "AUTOSHIFT_DR_STATE_BRAKE_GEAR_SHIFT_CONFIRMED_R" 4 "AUTOSHIFT_DR_STATE_BRAKE_STEERING_AND_BRAKE_CONFIRMED" 3 "AUTOSHIFT_DR_STATE_ONLY_STEERING_CONFIRMED" 2 "AUTOSHIFT_DR_STATE_ONLY_BRAKE_CONFIRMED" 1 "AUTOSHIFT_DR_STATE_PROMPT_SHOWING_UNCONFIRMED" 0 "AUTOSHIFT_DR_STATE_INACTIVE" ;
VAL_ 991 UI_wifiBtModuleType 4 "ELEKTRA" 3 "TCU4G" 2 "BCM4359" 1 "QCA6595" 0 "UNKNOWN" ;
VAL_ 991 UI_selfParkState 255 "SNA" 52 "SELF_PARK_USER_PAUSED" 51 "SELF_PARK_REMOTE_PRE_ABORT" 50 "SELF_PARK_RESUME" 49 "SELF_PARK_PAUSE" 48 "SELF_PARK_DV_MISMATCH" 47 "SELF_PARK_DI_PANIC" 46 "SELF_PARK_POST_ACTIVE_FAILURE" 45 "SELF_PARK_POST_ACTIVE_SUCCESS" 44 "SELF_PARK_CANCEL_AUTO_SUMMON" 43 "SELF_PARK_REMOTE_ABORT" 42 "SELF_PARK_OBSTACLE_NOT_CLEARED" 41 "SELF_PARK_OBSTACLE_CLEARED" 40 "SELF_PARK_OPEN_GATE" 39 "SELF_PARK_ACTIVE" 38 "SELF_PARK_STARTED_REVERSE" 37 "SELF_PARK_STARTED_FORWARD" 36 "SELF_PARK_NOT_STARTED_TIMEOUT" 35 "SELF_PARK_PRIMED" 34 "SELF_PARK_PREPRIMED" 33 "SELF_PARK_TURN_ON_DRIVE_RAIL" 32 "SELF_PARK_DETECT_KEY_FOB" 31 "SELF_PARK_WAKE_UP_BUSES" 30 "SELF_PARK_CONNECTING_BLUETOOTH" 29 "SELF_PARK_UNAVAILABLE_CAR_WASH_MODE" 28 "SELF_PARK_UNAVAILABLE_CAR_ALARM" 27 "SELF_PARK_UNAVAILABLE_CRASH_STATE" 26 "SELF_PARK_UNAVAILABLE_DRAG_STRIP_MODE" 25 "SELF_PARK_UNAVAILABLE_TRACK_MODE" 24 "SELF_PARK_UNAVAILABLE_SERVICE_MODE" 23 "SELF_PARK_UNAVAILABLE_DOG_MODE" 22 "SELF_PARK_UNAVAILABLE_GAME_MODE" 21 "SELF_PARK_UNAVAILABLE_BLUETOOTH_CONNECT_TIMEOUT" 20 "SELF_PARK_UNAVAILABLE_WAKEUP_TIMEOUT" 19 "SELF_PARK_UNAVAILABLE_NO_BLUETOOTH_DEVICES_PAIRED" 18 "SELF_PARK_UNAVAILABLE_BRAKE_PRESSED" 17 "SELF_PARK_UNAVAILABLE_ROAD_GRADE" 16 "SELF_PARK_UNAVAILABLE_TRAILER_MODE" 15 "SELF_PARK_UNAVAILABLE_KEY_FOB_BATTERY_LOW" 14 "SELF_PARK_UNAVAILABLE_KEY_FOB_NOT_DETECTED" 13 "SELF_PARK_UNAVAILABLE_PARK_SENSOR_ISSUE" 12 "SELF_PARK_UNAVAILABLE_AUTOSTEER_NOT_ENABLED" 11 "SELF_PARK_UNAVAILABLE_LV_BUS_SUPPORT_ISSUE" 10 "SELF_PARK_UNAVAILABLE_ON_PUBLIC_ROAD" 9 "SELF_PARK_UNAVAILABLE_PARKED_TOO_LONG" 8 "SELF_PARK_UNAVAILABLE_DOOR_OPEN" 7 "SELF_PARK_UNAVAILABLE_TRUNK_OPEN" 6 "SELF_PARK_UNAVAILABLE_FRUNK_OPEN" 5 "SELF_PARK_UNAVAILABLE_PLUGGED_IN" 4 "SELF_PARK_UNAVAILABLE_NOT_PARKED" 3 "SELF_PARK_UNAVAILABLE" 2 "SELF_PARK_IDLE" 1 "SELF_PARK_DRIVING" 0 "SELF_PARK_DISABLED" ;
VAL_ 991 UI_summonDeviceIndex 3 "UNKNOWN" 2 "DEVICE_2" 1 "DEVICE_1" 0 "DEVICE_0" ;
VAL_ 663 UI_adaptiveRideRequest 3 "ADAPTIVE_RIDE_REQUEST_ADVANCED" 2 "ADAPTIVE_RIDE_REQUEST_SPORT" 1 "ADAPTIVE_RIDE_REQUEST_AUTO" 0 "ADAPTIVE_RIDE_REQUEST_COMFORT" ;
VAL_ 663 UI_geofenceLevelingRequest 5 "GEOFENCE_LEVELING_REQUEST_SNA" 4 "GEOFENCE_LEVELING_REQUEST_VERY_HIGH_PERSIST" 3 "GEOFENCE_LEVELING_REQUEST_HIGH_PERSIST" 2 "GEOFENCE_LEVELING_REQUEST_VERY_HIGH_TEMPORARY" 1 "GEOFENCE_LEVELING_REQUEST_HIGH_TEMPORARY" 0 "GEOFENCE_LEVELING_REQUEST_NONE" ;
VAL_ 787 UI_trackModeRequest 2 "TRACK_MODE_REQUEST_OFF" 1 "TRACK_MODE_REQUEST_ON" 0 "TRACK_MODE_REQUEST_IDLE" ;
VAL_ 787 UI_trackDrivePowerAvailability 2 "TRACK_MODE_POWER_MAX" 1 "TRACK_MODE_POWER_MIDDLE" 0 "TRACK_MODE_POWER_ENDURANCE" ;
VAL_ 839 UI_navFastchargerType 4 "V4" 3 "V3" 2 "V2" 1 "LOW_POWER" 0 "NONE" ;
VAL_ 839 UI_battPreconditionOnNavState 3 "ACTIVE_COOL" 2 "PASSIVE_COOL" 1 "ACTIVE_HEAT" 0 "PASSIVE_HEAT" ;
VAL_ 839 UI_battPreconditionOnNavPowerReq 127 "SNA" 126 "MAX" -126 "MIN" ;
VAL_ 839 UI_battPreconditionOnNavTargetT 255 "SNA" 254 "MAX" 0 "MIN" ;
VAL_ 839 UI_energyAtDestination -32767 "TRIP_TOO_LONG" -32768 "SNA" ;
VAL_ 627 UI_powerStateRequest 3 "DRIVE_SUMMON" 2 "ACCESSORY_PLUS" 1 "ACCESSORY" 0 "IDLE" ;
VAL_ 627 UI_wiperMode 3 "WIPER_MODE_PARK" 2 "WIPER_MODE_NORMAL" 1 "WIPER_MODE_SERVICE" 0 "WIPER_MODE_SNA" ;
VAL_ 627 UI_steeringButtonMode 7 "STEERING_BUTTON_MODE_SEATS" 6 "STEERING_BUTTON_MODE_WIPERS" 5 "STEERING_BUTTON_MODE_HEADLIGHT_RIGHT" 4 "STEERING_BUTTON_MODE_HEADLIGHT_LEFT" 3 "STEERING_BUTTON_MODE_MIRROR_RIGHT" 2 "STEERING_BUTTON_MODE_MIRROR_LEFT" 1 "STEERING_BUTTON_MODE_STEERING_COLUMN_ADJ" 0 "STEERING_BUTTON_MODE_OFF" ;
VAL_ 627 UI_lockRequest 7 "UI_LOCK_REQUEST_SNA" 4 "UI_LOCK_REQUEST_REMOTE_LOCK" 3 "UI_LOCK_REQUEST_REMOTE_UNLOCK" 2 "UI_LOCK_REQUEST_UNLOCK" 1 "UI_LOCK_REQUEST_LOCK" 0 "UI_LOCK_REQUEST_IDLE" ;
VAL_ 627 UI_mirrorFoldRequest 3 "MIRROR_FOLD_REQUEST_SNA" 2 "MIRROR_FOLD_REQUEST_PRESENT" 1 "MIRROR_FOLD_REQUEST_RETRACT" 0 "MIRROR_FOLD_REQUEST_IDLE" ;
VAL_ 627 UI_remoteStartRequest 4 "UI_REMOTE_START_REQUEST_SNA" 1 "UI_REMOTE_START_REQUEST_START" 0 "UI_REMOTE_START_REQUEST_IDLE" ;
VAL_ 627 UI_displayBrightnessLevel 255 "SNA" ;
VAL_ 627 UI_frontLeftSeatHeatReq 3 "HEATER_REQUEST_LEVEL3" 2 "HEATER_REQUEST_LEVEL2" 1 "HEATER_REQUEST_LEVEL1" 0 "HEATER_REQUEST_OFF" ;
VAL_ 627 UI_frontRightSeatHeatReq 3 "HEATER_REQUEST_LEVEL3" 2 "HEATER_REQUEST_LEVEL2" 1 "HEATER_REQUEST_LEVEL1" 0 "HEATER_REQUEST_OFF" ;
VAL_ 627 UI_rearLeftSeatHeatReq 3 "HEATER_REQUEST_LEVEL3" 2 "HEATER_REQUEST_LEVEL2" 1 "HEATER_REQUEST_LEVEL1" 0 "HEATER_REQUEST_OFF" ;
VAL_ 627 UI_rearCenterSeatHeatReq 3 "HEATER_REQUEST_LEVEL3" 2 "HEATER_REQUEST_LEVEL2" 1 "HEATER_REQUEST_LEVEL1" 0 "HEATER_REQUEST_OFF" ;
VAL_ 627 UI_rearRightSeatHeatReq 3 "HEATER_REQUEST_LEVEL3" 2 "HEATER_REQUEST_LEVEL2" 1 "HEATER_REQUEST_LEVEL1" 0 "HEATER_REQUEST_OFF" ;
VAL_ 627 UI_remoteClosureRequest 3 "UI_REMOTE_CLOSURE_REQUEST_SNA" 2 "UI_REMOTE_CLOSURE_REQUEST_FRONT_TRUNK_MOVE" 1 "UI_REMOTE_CLOSURE_REQUEST_REAR_TRUNK_MOVE" 0 "UI_REMOTE_CLOSURE_REQUEST_IDLE" ;
VAL_ 627 UI_wiperRequest 6 "WIPER_REQUEST_FAST_CONTINUOUS" 5 "WIPER_REQUEST_SLOW_CONTINUOUS" 4 "WIPER_REQUEST_FAST_INTERMITTENT" 3 "WIPER_REQUEST_SLOW_INTERMITTENT" 2 "WIPER_REQUEST_AUTO" 1 "WIPER_REQUEST_OFF" 0 "WIPER_REQUEST_SNA" ;
VAL_ 627 UI_domeLightSwitch 2 "DOME_LIGHT_SWITCH_AUTO" 1 "DOME_LIGHT_SWITCH_ON" 0 "DOME_LIGHT_SWITCH_OFF" ;
VAL_ 947 UI_lightSwitch 4 "LIGHT_SWITCH_SNA" 3 "LIGHT_SWITCH_OFF" 2 "LIGHT_SWITCH_PARKING" 1 "LIGHT_SWITCH_ON" 0 "LIGHT_SWITCH_AUTO" ;
VAL_ 947 UI_autopilotPowerStateRequest 2 "AUTOPILOT_SUSPEND" 1 "AUTOPILOT_SENTRY" 0 "AUTOPILOT_NOMINAL" ;
VAL_ 947 UI_frontLeftSeatFanReq 3 "FAN_REQUEST_LEVEL3" 2 "FAN_REQUEST_LEVEL2" 1 "FAN_REQUEST_LEVEL1" 0 "FAN_REQUEST_OFF" ;
VAL_ 947 UI_frontRightSeatFanReq 3 "FAN_REQUEST_LEVEL3" 2 "FAN_REQUEST_LEVEL2" 1 "FAN_REQUEST_LEVEL1" 0 "FAN_REQUEST_OFF" ;
VAL_ 660 UI_lightFlashRequest 3 "LIGHT_FLASH_SENTRY" 2 "LIGHT_FLASH_MOBILE_APP" 1 "LIGHT_FLASH_HOMELINK" 0 "LIGHT_FLASH_INACTIVE" ;
VAL_ 660 UI_steeringWheelHeatLevelReq 3 "STEERING_WHEEL_HEAT_LEVEL3" 2 "STEERING_WHEEL_HEAT_LEVEL2" 1 "STEERING_WHEEL_HEAT_LEVEL1" 0 "STEERING_WHEEL_HEAT_OFF" ;
VAL_ 660 UI_leftRearSeatAdjustmentRequest 6 "UI_ADJUSTABLE_FOLD_FLAT_REQUEST_STOP" 5 "UI_ADJUSTABLE_FOLD_FLAT_REQUEST_TOGGLE_FOLD" 4 "UI_ADJUSTABLE_FOLD_FLAT_REQUEST_REARWARD_FAST" 3 "UI_ADJUSTABLE_FOLD_FLAT_REQUEST_REARWARD_COMFORT" 2 "UI_ADJUSTABLE_FOLD_FLAT_REQUEST_FORWARD_FAST" 1 "UI_ADJUSTABLE_FOLD_FLAT_REQUEST_FORWARD_COMFORT" 0 "UI_ADJUSTABLE_FOLD_FLAT_REQUEST_NONE" ;
VAL_ 660 UI_rightRearSeatAdjustmentReques 6 "UI_ADJUSTABLE_FOLD_FLAT_REQUEST_STOP" 5 "UI_ADJUSTABLE_FOLD_FLAT_REQUEST_TOGGLE_FOLD" 4 "UI_ADJUSTABLE_FOLD_FLAT_REQUEST_REARWARD_FAST" 3 "UI_ADJUSTABLE_FOLD_FLAT_REQUEST_REARWARD_COMFORT" 2 "UI_ADJUSTABLE_FOLD_FLAT_REQUEST_FORWARD_FAST" 1 "UI_ADJUSTABLE_FOLD_FLAT_REQUEST_FORWARD_COMFORT" 0 "UI_ADJUSTABLE_FOLD_FLAT_REQUEST_NONE" ;
VAL_ 660 UI_rearSeatChildLock 3 "UI_ADJUSTABLE_FOLD_FLAT_CHILD_LOCK_BOTH" 2 "UI_ADJUSTABLE_FOLD_FLAT_CHILD_LOCK_RIGHT" 1 "UI_ADJUSTABLE_FOLD_FLAT_CHILD_LOCK_LEFT" 0 "UI_ADJUSTABLE_FOLD_FLAT_CHILD_LOCK_NONE" ;
VAL_ 660 UI_windowRequest 6 "WINDOW_REQUEST_GOTO_RELATIVE_PERCENT" 5 "WINDOW_REQUEST_GOTO_CLOSED_CARWASH" 4 "WINDOW_REQUEST_GOTO_OPEN" 3 "WINDOW_REQUEST_GOTO_CLOSED" 2 "WINDOW_REQUEST_GOTO_VENT" 1 "WINDOW_REQUEST_GOTO_PERCENT" 0 "WINDOW_REQUEST_IDLE" ;
VAL_ 644 UI_transportMode 1 "TRANSPORT_MODE_ENABLED" 0 "TRANSPORT_MODE_DISABLED" ;
VAL_ 644 UI_showroomMode 1 "SHOWROOM_MODE_ENABLED" 0 "SHOWROOM_MODE_DISABLED" ;
VAL_ 644 UI_serviceMode 1 "SERVICE_MODE_ENABLED" 0 "SERVICE_MODE_DISABLED" ;
VAL_ 644 UI_serviceModePlus 1 "SERVICE_MODE_PLUS_ENABLED" 0 "SERVICE_MODE_PLUS_DISABLED" ;
VAL_ 644 UI_lightShowType 5 "LIGHT_SHOW_TYPE_STANDARD_CNY24" 4 "LIGHT_SHOW_TYPE_STANDARD_THE_ARRIVAL" 3 "LIGHT_SHOW_TYPE_STANDARD_CNY23" 2 "LIGHT_SHOW_TYPE_STANDARD_AULD_LANG_SYNE" 1 "LIGHT_SHOW_TYPE_STANDARD_CAROL_OF_THE_BELLS" 0 "LIGHT_SHOW_TYPE_CUSTOM_USB" ;
VAL_ 595 UI_ventPanelControlRequestIndex 1 "1" 0 "0" ;
VAL_ 595 UI_ventPanelLeftLateralMode 2 "SWING" 1 "SPLIT" 0 "SINGLE" ;
VAL_ 595 UI_ventPanelRightLateralMode 2 "SWING" 1 "SPLIT" 0 "SINGLE" ;
VAL_ 595 UI_hvacReqActiveVents 3 "OFF" 2 "RIGHT" 1 "LEFT" 0 "BOTH" ;
VAL_ 1285 SA_infoIndex 32 "Mux32" 31 "Mux31" 30 "Mux30" 29 "Mux29" 27 "Mux27" 26 "Mux26" 25 "Mux25" 11 "Mux11" 0 "Mux0" ;
VAL_ 1285 SA_region 6 "SA_REGION_INDIA" 5 "SA_REGION_SOUTH_KOREA" 4 "SA_REGION_AUSTRALIA" 3 "SA_REGION_JAPAN" 2 "SA_REGION_CHINA" 1 "SA_REGION_EU" 0 "SA_REGION_NA" ;
